[part 3 of 15: package /Cluster]
AUTOSAR XML (schema 4-3-0)
package /Cluster  (continued)
  can cluster HCP3_CANFD01: baudrate=500000, protocol-name=CAN, protocol-version=2.0, bus-off-recovery={bor-counter-l-1-to-l-2=1, bor-time-l-1=0.05, bor-time-l-2=0.2}, can-fd-baudrate=1000000  (continued)
    can physical channel CHNL: comm-connectors=CN_HCP3_CANFD01  (continued)
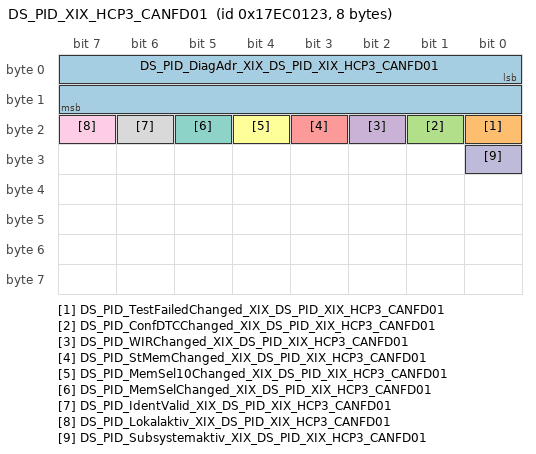
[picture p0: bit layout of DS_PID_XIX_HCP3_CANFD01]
      frame DS_PID_XIX_HCP3_CANFD01: id 0x17EC0123, to HCP3_IONode, frame-length=8, can-addressing-mode=EXTENDED, can-frame-rx-behavior=CAN-FD, can-frame-tx-behavior=CAN-FD
        pdu DS_PID_XIX_HCP3_CANFD01: length=8, minimum-delay=0.08, transmission-mode-true-timing={cyclic-timing={time-offset=0.0, time-period=1.0}, event-controlled-timing={number-of-repetitions=0, repetition-period=0.0}}, unused-bit-pattern=0
          signal DS_PID_DiagAdr_XIX_DS_PID_XIX_HCP3_CANFD01: start 0, 16 bit, little-endian, data-type-policy=OVERRIDE, i-signal-type=PRIMITIVE, init-value=33095, base-type=BT_DS_PID_DiagAdr, compu {phys=raw for raw 0..65535}, range phys 0..65535, raw 0..65535, transfer-property=PENDING  # Übertragung vom Diagnosestatus gem. 80114
          signal DS_PID_TestFailedChanged_XIX_DS_PID_XIX_HCP3_CANFD01: start 16, 1 bit, little-endian, data-type-policy=OVERRIDE, i-signal-type=PRIMITIVE, init-value=0, base-type=BT_DS_PID_TestFailedChanged, compu {phys=raw for raw 0..1}, range phys 0..1, raw 0..1, transfer-property=TRIGGERED-ON-CHANGE-WITHOUT-REPETITION  # Übertragung vom Diagnosestatus gem. 80114
          signal DS_PID_ConfDTCChanged_XIX_DS_PID_XIX_HCP3_CANFD01: start 17, 1 bit, little-endian, data-type-policy=OVERRIDE, i-signal-type=PRIMITIVE, init-value=0, base-type=BT_DS_PID_ConfDTCChanged, compu {phys=raw for raw 0..1}, range phys 0..1, raw 0..1, transfer-property=TRIGGERED-ON-CHANGE-WITHOUT-REPETITION  # Übertragung vom Diagnosestatus gem. 80114
          signal DS_PID_WIRChanged_XIX_DS_PID_XIX_HCP3_CANFD01: start 18, 1 bit, little-endian, data-type-policy=OVERRIDE, i-signal-type=PRIMITIVE, init-value=0, base-type=BT_DS_PID_WIRChanged, compu {phys=raw for raw 0..1}, range phys 0..1, raw 0..1, transfer-property=TRIGGERED-ON-CHANGE-WITHOUT-REPETITION  # Übertragung vom Diagnosestatus gem. 80114
          signal DS_PID_StMemChanged_XIX_DS_PID_XIX_HCP3_CANFD01: start 19, 1 bit, little-endian, data-type-policy=OVERRIDE, i-signal-type=PRIMITIVE, init-value=0, base-type=BT_DS_PID_StMemChanged, compu {phys=raw for raw 0..1}, range phys 0..1, raw 0..1, transfer-property=TRIGGERED-ON-CHANGE-WITHOUT-REPETITION  # Übertragung vom Diagnosestatus gem. 80114
          signal DS_PID_MemSel10Changed_XIX_DS_PID_XIX_HCP3_CANFD01: start 20, 1 bit, little-endian, data-type-policy=OVERRIDE, i-signal-type=PRIMITIVE, init-value=0, base-type=BT_DS_PID_MemSel10Changed, compu {phys=raw for raw 0..1}, range phys 0..1, raw 0..1, transfer-property=TRIGGERED-ON-CHANGE-WITHOUT-REPETITION  # Übertragung vom Diagnosestatus gem. 80114
          signal DS_PID_MemSelChanged_XIX_DS_PID_XIX_HCP3_CANFD01: start 21, 1 bit, little-endian, data-type-policy=OVERRIDE, i-signal-type=PRIMITIVE, init-value=0, base-type=BT_DS_PID_MemSelChanged, compu {phys=raw for raw 0..1}, range phys 0..1, raw 0..1, transfer-property=TRIGGERED-ON-CHANGE-WITHOUT-REPETITION  # Übertragung vom Diagnosestatus gem. 80114
          signal DS_PID_IdentValid_XIX_DS_PID_XIX_HCP3_CANFD01: start 22, 1 bit, little-endian, data-type-policy=OVERRIDE, i-signal-type=PRIMITIVE, init-value=1, base-type=BT_DS_PID_IdentValid, compu {1=Cx1_Gueltig (CM_DS_PID_IdentValid_Cx1_Gueltig), 0=Cx0_Ungueltig (CM_DS_PID_IdentValid_Cx0_Ungueltig)}, range raw 0..1, transfer-property=TRIGGERED-ON-CHANGE-WITHOUT-REPETITION  # Signalisiert ob die Identifikationsdaten gueltig sind
          signal DS_PID_Lokalaktiv_XIX_DS_PID_XIX_HCP3_CANFD01: start 23, 1 bit, little-endian, data-type-policy=OVERRIDE, i-signal-type=PRIMITIVE, init-value=0, base-type=BT_DS_PID_Lokalaktiv, compu {0=Cx0_war_nicht_lokal_aktiv (CM_DS_PID_Lokalaktiv_Cx0_war_nicht_lokal_aktiv), 1=Cx1_war_lokal_aktiv (CM_DS_PID_Lokalaktiv_Cx1_war_lokal_aktiv)}, range raw 0..1, transfer-property=PENDING  # Zeigt an ob das SG nach Klemme15 AUS und nach entsprechender MAX Aktivzeit noch aktiv war.
          signal DS_PID_Subsystemaktiv_XIX_DS_PID_XIX_HCP3_CANFD01: start 24, 1 bit, little-endian, data-type-policy=OVERRIDE, i-signal-type=PRIMITIVE, init-value=0, base-type=BT_DS_PID_Subsystemaktiv, compu {0=Cx0_war_nicht_lokal_aktiv (CM_DS_PID_Subsystemaktiv_Cx0_war_nicht_lokal_aktiv), 1=Cx1_war_lokal_aktiv (CM_DS_PID_Subsystemaktiv_Cx1_war_lokal_aktiv)}, range raw 0..1, transfer-property=PENDING  # Zeigt an ob ein Subsystem des SGs nach Klemme15 AUS und nach entsprechender MAX Aktivzeit noch aktiv war
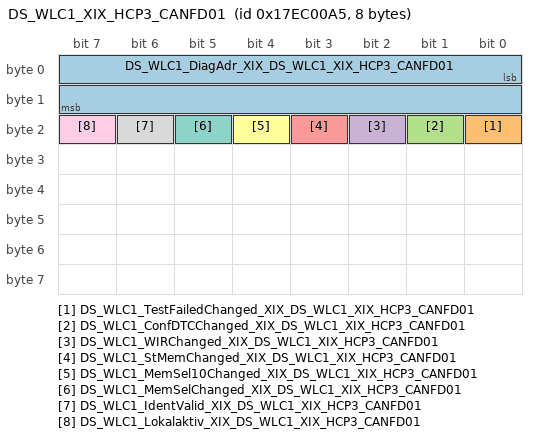
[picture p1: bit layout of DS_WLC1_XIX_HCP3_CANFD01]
      frame DS_WLC1_XIX_HCP3_CANFD01: id 0x17EC00A5, to HCP3_IONode, frame-length=8, can-addressing-mode=EXTENDED, can-frame-rx-behavior=CAN-FD, can-frame-tx-behavior=CAN-FD
        pdu DS_WLC1_XIX_HCP3_CANFD01: length=8, minimum-delay=0.08, transmission-mode-true-timing={cyclic-timing={time-offset=0.0, time-period=1.0}, event-controlled-timing={number-of-repetitions=0, repetition-period=0.0}}, unused-bit-pattern=0
          signal DS_WLC1_DiagAdr_XIX_DS_WLC1_XIX_HCP3_CANFD01: start 0, 16 bit, little-endian, data-type-policy=OVERRIDE, i-signal-type=PRIMITIVE, init-value=222, base-type=BT_DS_WLC1_DiagAdr, compu {phys=raw for raw 0..65535}, range phys 0..65535, raw 0..65535, transfer-property=PENDING  # Übertragung vom Diagnosestatus gem. 80114
          signal DS_WLC1_TestFailedChanged_XIX_DS_WLC1_XIX_HCP3_CANFD01: start 16, 1 bit, little-endian, data-type-policy=OVERRIDE, i-signal-type=PRIMITIVE, init-value=0, base-type=BT_DS_WLC1_TestFailedChanged, compu {phys=raw for raw 0..1}, range phys 0..1, raw 0..1, transfer-property=TRIGGERED-ON-CHANGE-WITHOUT-REPETITION  # Übertragung vom Diagnosestatus gem. 80114
          signal DS_WLC1_ConfDTCChanged_XIX_DS_WLC1_XIX_HCP3_CANFD01: start 17, 1 bit, little-endian, data-type-policy=OVERRIDE, i-signal-type=PRIMITIVE, init-value=0, base-type=BT_DS_WLC1_ConfDTCChanged, compu {phys=raw for raw 0..1}, range phys 0..1, raw 0..1, transfer-property=TRIGGERED-ON-CHANGE-WITHOUT-REPETITION  # Übertragung vom Diagnosestatus gem. 80114
          signal DS_WLC1_WIRChanged_XIX_DS_WLC1_XIX_HCP3_CANFD01: start 18, 1 bit, little-endian, data-type-policy=OVERRIDE, i-signal-type=PRIMITIVE, init-value=0, base-type=BT_DS_WLC1_WIRChanged, compu {phys=raw for raw 0..1}, range phys 0..1, raw 0..1, transfer-property=TRIGGERED-ON-CHANGE-WITHOUT-REPETITION  # Übertragung vom Diagnosestatus gem. 80114
          signal DS_WLC1_StMemChanged_XIX_DS_WLC1_XIX_HCP3_CANFD01: start 19, 1 bit, little-endian, data-type-policy=OVERRIDE, i-signal-type=PRIMITIVE, init-value=0, base-type=BT_DS_WLC1_StMemChanged, compu {phys=raw for raw 0..1}, range phys 0..1, raw 0..1, transfer-property=TRIGGERED-ON-CHANGE-WITHOUT-REPETITION  # Übertragung vom Diagnosestatus gem. 80114
          signal DS_WLC1_MemSel10Changed_XIX_DS_WLC1_XIX_HCP3_CANFD01: start 20, 1 bit, little-endian, data-type-policy=OVERRIDE, i-signal-type=PRIMITIVE, init-value=0, base-type=BT_DS_WLC1_MemSel10Changed, compu {phys=raw for raw 0..1}, range phys 0..1, raw 0..1, transfer-property=TRIGGERED-ON-CHANGE-WITHOUT-REPETITION  # Übertragung vom Diagnosestatus gem. 80114
          signal DS_WLC1_MemSelChanged_XIX_DS_WLC1_XIX_HCP3_CANFD01: start 21, 1 bit, little-endian, data-type-policy=OVERRIDE, i-signal-type=PRIMITIVE, init-value=0, base-type=BT_DS_WLC1_MemSelChanged, compu {phys=raw for raw 0..1}, range phys 0..1, raw 0..1, transfer-property=TRIGGERED-ON-CHANGE-WITHOUT-REPETITION  # Übertragung vom Diagnosestatus gem. 80114
          signal DS_WLC1_IdentValid_XIX_DS_WLC1_XIX_HCP3_CANFD01: start 22, 1 bit, little-endian, data-type-policy=OVERRIDE, i-signal-type=PRIMITIVE, init-value=1, base-type=BT_DS_WLC1_IdentValid, compu {1=Cx1_Gueltig (CM_DS_WLC1_IdentValid_Cx1_Gueltig), 0=Cx0_Ungueltig (CM_DS_WLC1_IdentValid_Cx0_Ungueltig)}, range raw 0..1, transfer-property=TRIGGERED-ON-CHANGE-WITHOUT-REPETITION  # Signalisiert ob die Identifikationsdaten gueltig sind
          signal DS_WLC1_Lokalaktiv_XIX_DS_WLC1_XIX_HCP3_CANFD01: start 23, 1 bit, little-endian, data-type-policy=OVERRIDE, i-signal-type=PRIMITIVE, init-value=0, base-type=BT_DS_WLC1_Lokalaktiv, compu {0=Cx0_war_nicht_lokal_aktiv (CM_DS_WLC1_Lokalaktiv_Cx0_war_nicht_lokal_aktiv), 1=Cx1_war_lokal_aktiv (CM_DS_WLC1_Lokalaktiv_Cx1_war_lokal_aktiv)}, range raw 0..1, transfer-property=PENDING  # Zeigt an ob das SG nach Klemme15 AUS und nach entsprechender MAX Aktivzeit noch aktiv war.
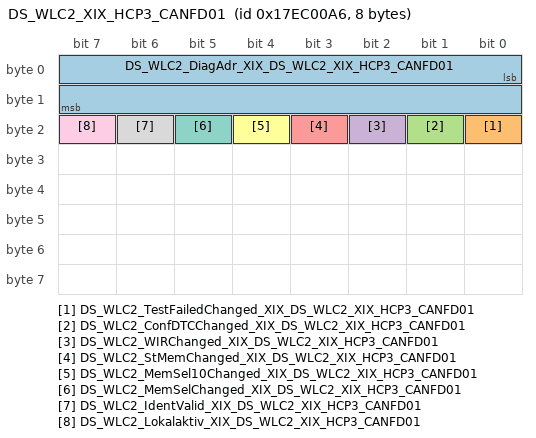
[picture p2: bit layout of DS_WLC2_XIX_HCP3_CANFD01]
      frame DS_WLC2_XIX_HCP3_CANFD01: id 0x17EC00A6, to HCP3_IONode, frame-length=8, can-addressing-mode=EXTENDED, can-frame-rx-behavior=CAN-FD, can-frame-tx-behavior=CAN-FD
        pdu DS_WLC2_XIX_HCP3_CANFD01: length=8, minimum-delay=0.08, transmission-mode-true-timing={cyclic-timing={time-offset=0.0, time-period=1.0}, event-controlled-timing={number-of-repetitions=0, repetition-period=0.0}}, unused-bit-pattern=0
          signal DS_WLC2_DiagAdr_XIX_DS_WLC2_XIX_HCP3_CANFD01: start 0, 16 bit, little-endian, data-type-policy=OVERRIDE, i-signal-type=PRIMITIVE, init-value=223, base-type=BT_DS_WLC2_DiagAdr, compu {phys=raw for raw 0..65535}, range phys 0..65535, raw 0..65535, transfer-property=PENDING  # Übertragung vom Diagnosestatus gem. 80114
          signal DS_WLC2_TestFailedChanged_XIX_DS_WLC2_XIX_HCP3_CANFD01: start 16, 1 bit, little-endian, data-type-policy=OVERRIDE, i-signal-type=PRIMITIVE, init-value=0, base-type=BT_DS_WLC2_TestFailedChanged, compu {phys=raw for raw 0..1}, range phys 0..1, raw 0..1, transfer-property=TRIGGERED-ON-CHANGE-WITHOUT-REPETITION  # Übertragung vom Diagnosestatus gem. 80114
          signal DS_WLC2_ConfDTCChanged_XIX_DS_WLC2_XIX_HCP3_CANFD01: start 17, 1 bit, little-endian, data-type-policy=OVERRIDE, i-signal-type=PRIMITIVE, init-value=0, base-type=BT_DS_WLC2_ConfDTCChanged, compu {phys=raw for raw 0..1}, range phys 0..1, raw 0..1, transfer-property=TRIGGERED-ON-CHANGE-WITHOUT-REPETITION  # Übertragung vom Diagnosestatus gem. 80114
          signal DS_WLC2_WIRChanged_XIX_DS_WLC2_XIX_HCP3_CANFD01: start 18, 1 bit, little-endian, data-type-policy=OVERRIDE, i-signal-type=PRIMITIVE, init-value=0, base-type=BT_DS_WLC2_WIRChanged, compu {phys=raw for raw 0..1}, range phys 0..1, raw 0..1, transfer-property=TRIGGERED-ON-CHANGE-WITHOUT-REPETITION  # Übertragung vom Diagnosestatus gem. 80114
          signal DS_WLC2_StMemChanged_XIX_DS_WLC2_XIX_HCP3_CANFD01: start 19, 1 bit, little-endian, data-type-policy=OVERRIDE, i-signal-type=PRIMITIVE, init-value=0, base-type=BT_DS_WLC2_StMemChanged, compu {phys=raw for raw 0..1}, range phys 0..1, raw 0..1, transfer-property=TRIGGERED-ON-CHANGE-WITHOUT-REPETITION  # Übertragung vom Diagnosestatus gem. 80114
          signal DS_WLC2_MemSel10Changed_XIX_DS_WLC2_XIX_HCP3_CANFD01: start 20, 1 bit, little-endian, data-type-policy=OVERRIDE, i-signal-type=PRIMITIVE, init-value=0, base-type=BT_DS_WLC2_MemSel10Changed, compu {phys=raw for raw 0..1}, range phys 0..1, raw 0..1, transfer-property=TRIGGERED-ON-CHANGE-WITHOUT-REPETITION  # Übertragung vom Diagnosestatus gem. 80114
          signal DS_WLC2_MemSelChanged_XIX_DS_WLC2_XIX_HCP3_CANFD01: start 21, 1 bit, little-endian, data-type-policy=OVERRIDE, i-signal-type=PRIMITIVE, init-value=0, base-type=BT_DS_WLC2_MemSelChanged, compu {phys=raw for raw 0..1}, range phys 0..1, raw 0..1, transfer-property=TRIGGERED-ON-CHANGE-WITHOUT-REPETITION  # Übertragung vom Diagnosestatus gem. 80114
          signal DS_WLC2_IdentValid_XIX_DS_WLC2_XIX_HCP3_CANFD01: start 22, 1 bit, little-endian, data-type-policy=OVERRIDE, i-signal-type=PRIMITIVE, init-value=1, base-type=BT_DS_WLC2_IdentValid, compu {1=Cx1_Gueltig (CM_DS_WLC2_IdentValid_Cx1_Gueltig), 0=Cx0_Ungueltig (CM_DS_WLC2_IdentValid_Cx0_Ungueltig)}, range raw 0..1, transfer-property=TRIGGERED-ON-CHANGE-WITHOUT-REPETITION  # Signalisiert ob die Identifikationsdaten gueltig sind
          signal DS_WLC2_Lokalaktiv_XIX_DS_WLC2_XIX_HCP3_CANFD01: start 23, 1 bit, little-endian, data-type-policy=OVERRIDE, i-signal-type=PRIMITIVE, init-value=0, base-type=BT_DS_WLC2_Lokalaktiv, compu {1=Cx1_war_lokal_aktiv (CM_DS_WLC2_Lokalaktiv_Cx1_war_lokal_aktiv), 0=Cx0_war_nicht_lokal_aktiv (CM_DS_WLC2_Lokalaktiv_Cx0_war_nicht_lokal_aktiv)}, range raw 0..1, transfer-property=PENDING  # Zeigt an ob das SG nach Klemme15 AUS und nach entsprechender MAX Aktivzeit noch aktiv war.
      frame Diag_LSR_1_Req_FD_XIX_HCP3_CANFD01: id 0x1C400693, from HCP3_IONode, frame-length=64, can-addressing-mode=EXTENDED, can-frame-rx-behavior=CAN-FD, can-frame-tx-behavior=CAN-FD
        n pdu Diag_LSR_1_Req_FD_XIX_HCP3_CANFD01: length=64
      frame Diag_LSR_1_Resp_FD_XIX_HCP3_CANFD01: id 0x1C420693, to HCP3_IONode, frame-length=64, can-addressing-mode=EXTENDED, can-frame-rx-behavior=CAN-FD, can-frame-tx-behavior=CAN-FD
        n pdu Diag_LSR_1_Resp_FD_XIX_HCP3_CANFD01: length=64
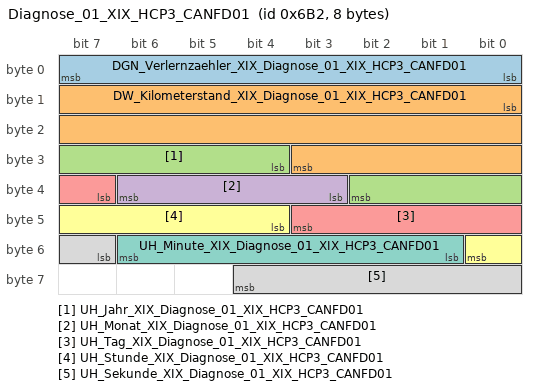
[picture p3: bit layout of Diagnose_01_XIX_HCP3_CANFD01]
      frame Diagnose_01_XIX_HCP3_CANFD01: id 0x6B2, from HCP3_IONode, frame-length=8, can-addressing-mode=STANDARD, can-frame-rx-behavior=CAN-FD, can-frame-tx-behavior=CAN-FD
        pdu Diagnose_01_XIX_HCP3_CANFD01: length=8, transmission-mode-true-timing=cyclic-timing={time-offset=0.0, time-period=1.0}, unused-bit-pattern=0
          signal DGN_Verlernzaehler_XIX_Diagnose_01_XIX_HCP3_CANFD01: start 0, 8 bit, little-endian, data-type-policy=OVERRIDE, i-signal-type=PRIMITIVE, init-value=0, base-type=BT_DGN_Verlernzaehler, compu {phys=raw for raw 0..254, 255=Cxff_ungueltiger_Zaehlerstand_oder_kein_gueltiger_Fahrzyklus (CM_DGN_Verlernzaehler_Cxff_ungueltiger_Zaehlerstand_oder_kein_gueltiger_Fahrzyklus) (ungültiger Zählerstand oder kein gültiger Fahrzyklus)}, range phys 0..254, raw 0..255, transfer-property=PENDING  # wrap around 254 --> 0
          signal DW_Kilometerstand_XIX_Diagnose_01_XIX_HCP3_CANFD01: start 8, 20 bit, little-endian, data-type-policy=OVERRIDE, i-signal-type=PRIMITIVE, init-value=1048574, base-type=BT_DW_Kilometerstand, invalid-value=Invalid_DW_Kilometerstand_XIX_Diagnose_01_XIX_HCP3_CANFD01:1048575, compu {phys=raw for raw 0..1048573, 1048575=Cxfffff_Fehler (CM_DW_Kilometerstand_Cxfffff_Fehler), 1048574=Cxffffe_Init (CM_DW_Kilometerstand_Cxffffe_Init); unit Unit_KiloMeter}, range phys 0..1048573 Unit_KiloMeter, raw 0..1048575, unit=Unit_KiloMeter, transfer-property=PENDING  # Fehler wird ausgegeben, falls Kilometerstand nicht restaurierbar
          signal UH_Jahr_XIX_Diagnose_01_XIX_HCP3_CANFD01: start 28, 7 bit, little-endian, data-type-policy=OVERRIDE, i-signal-type=PRIMITIVE, init-value=0, base-type=BT_UH_Jahr, compu {phys=raw+2000 for raw 0..127; unit Unit_Year}, range phys 2000..2127 Unit_Year, raw 0..127, unit=Unit_Year, transfer-property=PENDING
          signal UH_Monat_XIX_Diagnose_01_XIX_HCP3_CANFD01: start 35, 4 bit, little-endian, data-type-policy=OVERRIDE, i-signal-type=PRIMITIVE, init-value=0, base-type=BT_UH_Monat, invalid-value=Invalid_UH_Monat_XIX_Diagnose_01_XIX_HCP3_CANFD01:15, compu {phys=raw for raw 1..12, 15=Cxf_Fehler (CM_UH_Monat_Cxf_Fehler), 14=Cxe_Relatives_Datum (CM_UH_Monat_Cxe_Relatives_Datum), 0=Cx0_Init (CM_UH_Monat_Cx0_Init); unit Unit_Month}, range phys 1..12 Unit_Month, raw 0..15, unit=Unit_Month, transfer-property=PENDING  # 0x0D, 0xF = Werte ungültig 0x0E = Relatives Datum (nur VW)
          signal UH_Tag_XIX_Diagnose_01_XIX_HCP3_CANFD01: start 39, 5 bit, little-endian, data-type-policy=OVERRIDE, i-signal-type=PRIMITIVE, init-value=0, base-type=BT_UH_Tag, compu {phys=raw for raw 1..31, 0=Cx0_Init (CM_UH_Tag_Cx0_Init); unit Unit_Day}, range phys 1..31 Unit_Day, raw 0..31, unit=Unit_Day, transfer-property=PENDING  # 0x0: reserviert bei VW
          signal UH_Stunde_XIX_Diagnose_01_XIX_HCP3_CANFD01: start 44, 5 bit, little-endian, data-type-policy=OVERRIDE, i-signal-type=PRIMITIVE, init-value=0, base-type=BT_UH_Stunde, compu {phys=raw for raw 0..23; unit Unit_Hours}, range phys 0..23 Unit_Hours, raw 0..23, unit=Unit_Hours, transfer-property=PENDING  # 0x18 - 0x1F = Werte ungültig
          signal UH_Minute_XIX_Diagnose_01_XIX_HCP3_CANFD01: start 49, 6 bit, little-endian, data-type-policy=OVERRIDE, i-signal-type=PRIMITIVE, init-value=0, base-type=BT_UH_Minute, compu {phys=raw for raw 0..59; unit Unit_Minut}, range phys 0..59 Unit_Minut, raw 0..59, unit=Unit_Minut, transfer-property=PENDING  # 0x3C- 0x3f = Werte ungültig
          signal UH_Sekunde_XIX_Diagnose_01_XIX_HCP3_CANFD01: start 55, 6 bit, little-endian, data-type-policy=OVERRIDE, i-signal-type=PRIMITIVE, init-value=0, base-type=BT_UH_Sekunde, compu {phys=raw for raw 0..59; unit Unit_Secon}, range phys 0..59 Unit_Secon, raw 0..59, unit=Unit_Secon, transfer-property=PENDING  # 0x3C- 0x3f = Werte ungültig
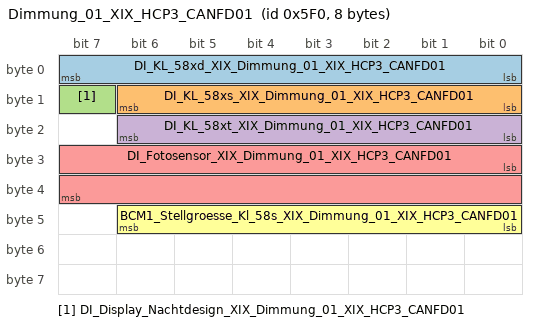
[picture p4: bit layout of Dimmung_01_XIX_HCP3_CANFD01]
      frame Dimmung_01_XIX_HCP3_CANFD01: id 0x5F0, from HCP3_IONode, frame-length=8, can-addressing-mode=STANDARD, can-frame-rx-behavior=CAN-FD, can-frame-tx-behavior=CAN-FD
        pdu Dimmung_01_XIX_HCP3_CANFD01: length=8, minimum-delay=0.05, transmission-mode-true-timing={cyclic-timing={time-offset=0.0, time-period=0.2}, event-controlled-timing={number-of-repetitions=0, repetition-period=0.0}}, unused-bit-pattern=0  # ab MQB nach abgestimmten FLH Dimmung
          signal DI_KL_58xd_XIX_Dimmung_01_XIX_HCP3_CANFD01: start 0, 8 bit, little-endian, data-type-policy=OVERRIDE, i-signal-type=PRIMITIVE, init-value=254, base-type=BT_DI_KL_58xd, invalid-value=Invalid_DI_KL_58xd_XIX_Dimmung_01_XIX_HCP3_CANFD01:255, compu {phys=raw for raw 0..253, 255=Cxff_Fehler (CM_DI_KL_58xd_Cxff_Fehler), 254=Cxfe_Init (CM_DI_KL_58xd_Cxfe_Init)}, range phys 0..253, raw 0..255, transfer-property=TRIGGERED-ON-CHANGE-WITHOUT-REPETITION  # Klemme 58xd Display- und Funktionsbeleuchtung Mit der Klemme 58xd wird die Helligkeit der Display- und der Funktionsbeleuchtungen der Schalter gesteuert. Im Detail beschrieben im 'Funktionslastenheft Dimmung MQB'.
          signal DI_KL_58xs_XIX_Dimmung_01_XIX_HCP3_CANFD01: start 8, 7 bit, little-endian, data-type-policy=OVERRIDE, i-signal-type=PRIMITIVE, init-value=126, base-type=BT_DI_KL_58xs, invalid-value=Invalid_DI_KL_58xs_XIX_Dimmung_01_XIX_HCP3_CANFD01:127, compu {phys=raw for raw 0..100, 127=Cx7f_Fehler (CM_DI_KL_58xs_Cx7f_Fehler), 126=Cx7e_Init (CM_DI_KL_58xs_Cx7e_Init); unit Unit_PerCent}, range phys 0..100 Unit_PerCent, raw 0..127, unit=Unit_PerCent, transfer-property=TRIGGERED-ON-CHANGE-WITHOUT-REPETITION  # Suchbeleuchtung Schalter EIN-AUS-Schaltalgorithmus der allgemeinen Schaltersuchbeleuchtung. Im Detail beschrieben im 'Funktionslastenheft Dimmung MQB'.
          signal DI_Display_Nachtdesign_XIX_Dimmung_01_XIX_HCP3_CANFD01: start 15, 1 bit, little-endian, data-type-policy=OVERRIDE, i-signal-type=PRIMITIVE, init-value=0, base-type=BT_DI_Display_Nachtdesign, transfer-property=TRIGGERED-ON-CHANGE-WITHOUT-REPETITION  # Für Displays sind oft automatische Umschaltungen von Tag-/Nachtdesign vorgesehen. Es gibt jedoch Zustände, an denen auch tagsüber das Abblendlicht eingeschaltet ist. z.B. Dauerfahrlicht, Geschwindigkeitsabhängiges "Licht-An-Bei-Autobahn", "Regenlicht", etc. Die Aufgabe des Signals s_Display_Nachtdesign ist es, Fehlumschaltungen zu vermeiden. Es ist im Dimm-Master zu implementieren. Im Detail beschrieben im 'Funktionslastenheft Dimmung MQB'.
          signal DI_KL_58xt_XIX_Dimmung_01_XIX_HCP3_CANFD01: start 16, 7 bit, little-endian, data-type-policy=OVERRIDE, i-signal-type=PRIMITIVE, init-value=126, base-type=BT_DI_KL_58xt, invalid-value=Invalid_DI_KL_58xt_XIX_Dimmung_01_XIX_HCP3_CANFD01:127, compu {phys=raw for raw 0..100, 127=Cx7f_Fehler (CM_DI_KL_58xt_Cx7f_Fehler), 126=Cx7e_Init (CM_DI_KL_58xt_Cx7e_Init); unit Unit_PerCent}, range phys 0..100 Unit_PerCent, raw 0..127, unit=Unit_PerCent, transfer-property=TRIGGERED-ON-CHANGE-WITHOUT-REPETITION  # Timergesteuerte Suchbeleuchtung Der EIN-AUS-Schaltalgorithmus für die vor- und nachlaufende Schaltersuchbeleuchtungen beim Ein- & Aussteigen; z.B.: Start/Stop-Taster. Im Detail beschrieben im 'Funktionslastenheft Dimmung MQB'.
          signal DI_Fotosensor_XIX_Dimmung_01_XIX_HCP3_CANFD01: start 24, 16 bit, little-endian, data-type-policy=OVERRIDE, i-signal-type=PRIMITIVE, init-value=0, base-type=BT_DI_Fotosensor, compu {phys=raw for raw 0..65535}, range phys 0..65535, raw 0..65535, transfer-property=TRIGGERED-ON-CHANGE-WITHOUT-REPETITION  # Helligkeitswert Fotosensor Für die Dimmung relevanter Wert zur Sensierung der Umgebungshelligkeit Im Detail beschrieben im 'Funktionslastenheft Dimmung MQB'.
          signal BCM1_Stellgroesse_Kl_58s_XIX_Dimmung_01_XIX_HCP3_CANFD01: start 40, 7 bit, little-endian, data-type-policy=OVERRIDE, i-signal-type=PRIMITIVE, init-value=126, base-type=BT_BCM1_Stellgroesse_Kl_58s, invalid-value=Invalid_BCM1_Stellgroesse_Kl_58s_XIX_Dimmung_01_XIX_HCP3_CANFD01:127, compu {phys=raw for raw 0..100, 127=Cx7f_Fehler (CM_BCM1_Stellgroesse_Kl_58s_Cx7f_Fehler), 125=Cx7d_Nicht_verbaut (CM_BCM1_Stellgroesse_Kl_58s_Cx7d_Nicht_verbaut), 126=Cx7e_Init (CM_BCM1_Stellgroesse_Kl_58s_Cx7e_Init)}, range phys 0..100, raw 0..127, transfer-property=TRIGGERED-ON-CHANGE-WITHOUT-REPETITION  # Rohwert Dimmpoti
      frame DispCtrlCID_CID_Req_FD_XIX_HCP3_CANFD01: id 0x1C446822, from HCP3_IONode, frame-length=64, can-addressing-mode=EXTENDED, can-frame-rx-behavior=CAN-FD, can-frame-tx-behavior=CAN-FD
        n pdu DispCtrlCID_CID_Req_FD_XIX_HCP3_CANFD01: length=64
      frame DispCtrlCID_CID_Resp_FD_XIX_HCP3_CANFD01: id 0x1C466822, to HCP3_IONode, frame-length=64, can-addressing-mode=EXTENDED, can-frame-rx-behavior=CAN-FD, can-frame-tx-behavior=CAN-FD
        n pdu DispCtrlCID_CID_Resp_FD_XIX_HCP3_CANFD01: length=64
      frame DispCtrlPID_PID_Req_FD_XIX_HCP3_CANFD01: id 0x1C446723, from HCP3_IONode, frame-length=64, can-addressing-mode=EXTENDED, can-frame-rx-behavior=CAN-FD, can-frame-tx-behavior=CAN-FD
        n pdu DispCtrlPID_PID_Req_FD_XIX_HCP3_CANFD01: length=64
      frame DispCtrlPID_PID_Resp_FD_XIX_HCP3_CANFD01: id 0x1C466723, to HCP3_IONode, frame-length=64, can-addressing-mode=EXTENDED, can-frame-rx-behavior=CAN-FD, can-frame-tx-behavior=CAN-FD
        n pdu DispCtrlPID_PID_Resp_FD_XIX_HCP3_CANFD01: length=64
      frame DispInpCID_CID_Req_FD_XIX_HCP3_CANFD01: id 0x1C446B22, from HCP3_IONode, frame-length=64, can-addressing-mode=EXTENDED, can-frame-rx-behavior=CAN-FD, can-frame-tx-behavior=CAN-FD
        n pdu DispInpCID_CID_Req_FD_XIX_HCP3_CANFD01: length=64
      frame DispInpCID_CID_Resp_FD_XIX_HCP3_CANFD01: id 0x1C466B22, to HCP3_IONode, frame-length=64, can-addressing-mode=EXTENDED, can-frame-rx-behavior=CAN-FD, can-frame-tx-behavior=CAN-FD
        n pdu DispInpCID_CID_Resp_FD_XIX_HCP3_CANFD01: length=64
      frame DispInpPID_PID_Req_FD_XIX_HCP3_CANFD01: id 0x1C446A23, from HCP3_IONode, frame-length=64, can-addressing-mode=EXTENDED, can-frame-rx-behavior=CAN-FD, can-frame-tx-behavior=CAN-FD
        n pdu DispInpPID_PID_Req_FD_XIX_HCP3_CANFD01: length=64
      frame DispInpPID_PID_Resp_FD_XIX_HCP3_CANFD01: id 0x1C466A23, to HCP3_IONode, frame-length=64, can-addressing-mode=EXTENDED, can-frame-rx-behavior=CAN-FD, can-frame-tx-behavior=CAN-FD
        n pdu DispInpPID_PID_Resp_FD_XIX_HCP3_CANFD01: length=64
      frame FBS_MKGO_01_XIX_HCP3_CANFD01: id 0x16A95538, from HCP3_IONode, frame-length=64, can-addressing-mode=EXTENDED, can-frame-rx-behavior=CAN-FD, can-frame-tx-behavior=CAN-FD
        pdu FBS_MKGO_01_XIX_HCP3_CANFD01: length=64, transmission-mode-true-timing=event-controlled-timing={number-of-repetitions=0, repetition-period=0.0}, unused-bit-pattern=0
          signal FBS_MKGO_01_XIX_FBS_MKGO_01_XIX_HCP3_CANFD01: start 0, 512 bit, opaque, data-type-policy=OVERRIDE, i-signal-type=ARRAY, init-value=64 x 0, base-type=BT_FBS_MKGO_01, implementation-data-type=FBS_MKGO_01, transfer-property=TRIGGERED-WITHOUT-REPETITION  # NFC Kommunikation FBS zu MKGO
      frame FBS_MKGO_02_XIX_HCP3_CANFD01: id 0x16A95539, from HCP3_IONode, frame-length=64, can-addressing-mode=EXTENDED, can-frame-rx-behavior=CAN-FD, can-frame-tx-behavior=CAN-FD
        pdu FBS_MKGO_02_XIX_HCP3_CANFD01: length=64, transmission-mode-true-timing=event-controlled-timing={number-of-repetitions=0, repetition-period=0.0}, unused-bit-pattern=0
          signal FBS_MKGO_02_XIX_FBS_MKGO_02_XIX_HCP3_CANFD01: start 0, 512 bit, opaque, data-type-policy=OVERRIDE, i-signal-type=ARRAY, init-value=64 x 0, base-type=BT_FBS_MKGO_02, implementation-data-type=FBS_MKGO_02, transfer-property=TRIGGERED-WITHOUT-REPETITION  # NFC Kommunikation FBS zu MKGO
      frame FBS_MKGO_03_XIX_HCP3_CANFD01: id 0x16A9553A, from HCP3_IONode, frame-length=64, can-addressing-mode=EXTENDED, can-frame-rx-behavior=CAN-FD, can-frame-tx-behavior=CAN-FD
        pdu FBS_MKGO_03_XIX_HCP3_CANFD01: length=64, transmission-mode-true-timing=event-controlled-timing={number-of-repetitions=0, repetition-period=0.0}, unused-bit-pattern=0
          signal FBS_MKGO_03_XIX_FBS_MKGO_03_XIX_HCP3_CANFD01: start 0, 512 bit, opaque, data-type-policy=OVERRIDE, i-signal-type=ARRAY, init-value=64 x 0, base-type=BT_FBS_MKGO_03, implementation-data-type=FBS_MKGO_03, transfer-property=TRIGGERED-WITHOUT-REPETITION  # NFC Kommunikation FBS zu MKGO
      frame FBS_MKGO_04_XIX_HCP3_CANFD01: id 0x16A9553B, from HCP3_IONode, frame-length=64, can-addressing-mode=EXTENDED, can-frame-rx-behavior=CAN-FD, can-frame-tx-behavior=CAN-FD
        pdu FBS_MKGO_04_XIX_HCP3_CANFD01: length=64, transmission-mode-true-timing=event-controlled-timing={number-of-repetitions=0, repetition-period=0.0}, unused-bit-pattern=0
          signal FBS_MKGO_04_XIX_FBS_MKGO_04_XIX_HCP3_CANFD01: start 0, 512 bit, opaque, data-type-policy=OVERRIDE, i-signal-type=ARRAY, init-value=64 x 0, base-type=BT_FBS_MKGO_04, implementation-data-type=FBS_MKGO_04, transfer-property=TRIGGERED-WITHOUT-REPETITION  # NFC Kommunikation FBS zu MKGO
      frame FBS_MKGO_05_XIX_HCP3_CANFD01: id 0x16A9553C, from HCP3_IONode, frame-length=64, can-addressing-mode=EXTENDED, can-frame-rx-behavior=CAN-FD, can-frame-tx-behavior=CAN-FD
        pdu FBS_MKGO_05_XIX_HCP3_CANFD01: length=64, transmission-mode-true-timing=event-controlled-timing={number-of-repetitions=0, repetition-period=0.0}, unused-bit-pattern=0
          signal FBS_MKGO_05_XIX_FBS_MKGO_05_XIX_HCP3_CANFD01: start 0, 512 bit, opaque, data-type-policy=OVERRIDE, i-signal-type=ARRAY, init-value=64 x 0, base-type=BT_FBS_MKGO_05, implementation-data-type=FBS_MKGO_05, transfer-property=TRIGGERED-WITHOUT-REPETITION  # NFC Kommunikation FBS zu MKGO
      frame HID_HUD_ZR_Req_FD_XIX_HCP3_CANFD01: id 0x1D001B73, to HCP3_IONode, frame-length=64, can-addressing-mode=EXTENDED, can-frame-rx-behavior=CAN-FD, can-frame-tx-behavior=CAN-FD
        n pdu HID_HUD_ZR_Req_FD_XIX_HCP3_CANFD01: length=64
      frame HID_HUD_ZR_Resp_FD_XIX_HCP3_CANFD01: id 0x1D021B73, from HCP3_IONode, frame-length=64, can-addressing-mode=EXTENDED, can-frame-rx-behavior=CAN-FD, can-frame-tx-behavior=CAN-FD
        n pdu HID_HUD_ZR_Resp_FD_XIX_HCP3_CANFD01: length=64
      frame HID_ZR_HUD_Req_FD_XIX_HCP3_CANFD01: id 0x1D00731B, from HCP3_IONode, frame-length=64, can-addressing-mode=EXTENDED, can-frame-rx-behavior=CAN-FD, can-frame-tx-behavior=CAN-FD
        n pdu HID_ZR_HUD_Req_FD_XIX_HCP3_CANFD01: length=64
      frame HID_ZR_HUD_Resp_FD_XIX_HCP3_CANFD01: id 0x1D02731B, to HCP3_IONode, frame-length=64, can-addressing-mode=EXTENDED, can-frame-rx-behavior=CAN-FD, can-frame-tx-behavior=CAN-FD
        n pdu HID_ZR_HUD_Resp_FD_XIX_HCP3_CANFD01: length=64
      frame HUD_ARC_Req_FD_XIX_HCP3_CANFD01: id 0x1CC01B3B, to HCP3_IONode, frame-length=64, can-addressing-mode=EXTENDED, can-frame-rx-behavior=CAN-FD, can-frame-tx-behavior=CAN-FD
        n pdu HUD_ARC_Req_FD_XIX_HCP3_CANFD01: length=64
      frame HUD_ARC_Resp_FD_XIX_HCP3_CANFD01: id 0x1CC21B3B, from HCP3_IONode, frame-length=64, can-addressing-mode=EXTENDED, can-frame-rx-behavior=CAN-FD, can-frame-tx-behavior=CAN-FD
        n pdu HUD_ARC_Resp_FD_XIX_HCP3_CANFD01: length=64
      frame ISOx_CCF_Req_FD_XIX_HCP3_CANFD01: id 0x1C440024, from HCP3_IONode, frame-length=64, can-addressing-mode=EXTENDED, can-frame-rx-behavior=CAN-FD, can-frame-tx-behavior=CAN-FD
        n pdu ISOx_CCF_Req_FD_XIX_HCP3_CANFD01: length=64
      frame ISOx_CCF_Resp_FD_XIX_HCP3_CANFD01: id 0x1C460024, to HCP3_IONode, frame-length=64, can-addressing-mode=EXTENDED, can-frame-rx-behavior=CAN-FD, can-frame-tx-behavior=CAN-FD
        n pdu ISOx_CCF_Resp_FD_XIX_HCP3_CANFD01: length=64
      frame ISOx_CID_Req_FD_XIX_HCP3_CANFD01: id 0x1C440022, from HCP3_IONode, frame-length=64, can-addressing-mode=EXTENDED, can-frame-rx-behavior=CAN-FD, can-frame-tx-behavior=CAN-FD
        n pdu ISOx_CID_Req_FD_XIX_HCP3_CANFD01: length=64
      frame ISOx_CID_Resp_FD_XIX_HCP3_CANFD01: id 0x1C460022, to HCP3_IONode, frame-length=64, can-addressing-mode=EXTENDED, can-frame-rx-behavior=CAN-FD, can-frame-tx-behavior=CAN-FD
        n pdu ISOx_CID_Resp_FD_XIX_HCP3_CANFD01: length=64
      frame ISOx_Funkt_Req_All_FD_XIX_HCP3_CANFD01: id 0x1C410000, from HCP3_IONode, frame-length=64, can-addressing-mode=EXTENDED, can-frame-rx-behavior=CAN-FD, can-frame-tx-behavior=CAN-FD
        n pdu ISOx_Funkt_Req_All_FD_XIX_HCP3_CANFD01: length=64
      frame ISOx_HUD_Req_FD_XIX_HCP3_CANFD01: id 0x1C40001B, from HCP3_IONode, frame-length=64, can-addressing-mode=EXTENDED, can-frame-rx-behavior=CAN-FD, can-frame-tx-behavior=CAN-FD
        n pdu ISOx_HUD_Req_FD_XIX_HCP3_CANFD01: length=64
      frame ISOx_HUD_Resp_FD_XIX_HCP3_CANFD01: id 0x1C42001B, to HCP3_IONode, frame-length=64, can-addressing-mode=EXTENDED, can-frame-rx-behavior=CAN-FD, can-frame-tx-behavior=CAN-FD
        n pdu ISOx_HUD_Resp_FD_XIX_HCP3_CANFD01: length=64
      frame ISOx_PID_Req_FD_XIX_HCP3_CANFD01: id 0x1C440023, from HCP3_IONode, frame-length=64, can-addressing-mode=EXTENDED, can-frame-rx-behavior=CAN-FD, can-frame-tx-behavior=CAN-FD
        n pdu ISOx_PID_Req_FD_XIX_HCP3_CANFD01: length=64
      frame ISOx_PID_Resp_FD_XIX_HCP3_CANFD01: id 0x1C460023, to HCP3_IONode, frame-length=64, can-addressing-mode=EXTENDED, can-frame-rx-behavior=CAN-FD, can-frame-tx-behavior=CAN-FD
        n pdu ISOx_PID_Resp_FD_XIX_HCP3_CANFD01: length=64
      frame ISOx_WLC1_Req_FD_XIX_HCP3_CANFD01: id 0x1C4000A5, from HCP3_IONode, frame-length=64, can-addressing-mode=EXTENDED, can-frame-rx-behavior=CAN-FD, can-frame-tx-behavior=CAN-FD
        n pdu ISOx_WLC1_Req_FD_XIX_HCP3_CANFD01: length=64
      frame ISOx_WLC1_Resp_FD_XIX_HCP3_CANFD01: id 0x1C4200A5, to HCP3_IONode, frame-length=64, can-addressing-mode=EXTENDED, can-frame-rx-behavior=CAN-FD, can-frame-tx-behavior=CAN-FD
        n pdu ISOx_WLC1_Resp_FD_XIX_HCP3_CANFD01: length=64
      frame ISOx_WLC2_Req_FD_XIX_HCP3_CANFD01: id 0x1C4000A6, from HCP3_IONode, frame-length=64, can-addressing-mode=EXTENDED, can-frame-rx-behavior=CAN-FD, can-frame-tx-behavior=CAN-FD
        n pdu ISOx_WLC2_Req_FD_XIX_HCP3_CANFD01: length=64
      frame ISOx_WLC2_Resp_FD_XIX_HCP3_CANFD01: id 0x1C4200A6, to HCP3_IONode, frame-length=64, can-addressing-mode=EXTENDED, can-frame-rx-behavior=CAN-FD, can-frame-tx-behavior=CAN-FD
        n pdu ISOx_WLC2_Resp_FD_XIX_HCP3_CANFD01: length=64
      frame Info_El_01_XIX_HCP3_CANFD01: id 0x1A555557, from HCP3_IONode, frame-length=16, can-addressing-mode=EXTENDED, can-frame-rx-behavior=CAN-FD, can-frame-tx-behavior=CAN-FD
        pdu Info_El_01_XIX_HCP3_CANFD01: length=16, minimum-delay=0.04, transmission-mode-true-timing={cyclic-timing={time-offset=0.0, time-period=1.0}, event-controlled-timing={number-of-repetitions=0, repetition-period=0.0}}, unused-bit-pattern=0
          signal ZR_State_CID_XIX_Info_El_01_XIX_HCP3_CANFD01: start 15, 3 bit, little-endian, data-type-policy=OVERRIDE, i-signal-type=PRIMITIVE, init-value=0, base-type=BT_ZR_State_CID, compu {2=Cx2_LowPow (CM_ZR_State_CID_Cx2_LowPow), 0=Cx0_Disp_Off (CM_ZR_State_CID_Cx0_Disp_Off), 1=Cx1_Disp_On (CM_ZR_State_CID_Cx1_Disp_On)}, range raw 0..2, transfer-property=TRIGGERED-ON-CHANGE-WITHOUT-REPETITION  # Kontrollbit für CI Hintergrundbeleuchtung aus, Hintergrundbeleuchtung an, Energiesparmodus
          signal ZR_State_PID_XIX_Info_El_01_XIX_HCP3_CANFD01: start 18, 3 bit, little-endian, data-type-policy=OVERRIDE, i-signal-type=PRIMITIVE, init-value=0, base-type=BT_ZR_State_PID, compu {0=Cx0_Disp_Off (CM_ZR_State_PID_Cx0_Disp_Off), 2=Cx2_LowPow (CM_ZR_State_PID_Cx2_LowPow), 1=Cx1_Disp_on (CM_ZR_State_PID_Cx1_Disp_on)}, range raw 0..2, transfer-property=TRIGGERED-ON-CHANGE-WITHOUT-REPETITION  # Kontrollbit für CID, Hintergrundbeleuchtung aus, Hintergrundbeleuchtung ein, Energiesparmodus
      frame KN_AMP_XIX_HCP3_CANFD01: id 0x17F0006F, to HCP3_IONode, frame-length=16, can-addressing-mode=EXTENDED, can-frame-rx-behavior=CAN-FD, can-frame-tx-behavior=CAN-FD
        pdu KN_AMP_XIX_HCP3_CANFD01: length=16, transmission-mode-true-timing=cyclic-timing={time-offset=0.0, time-period=0.5}, unused-bit-pattern=0
          signal AMP_KompSchutz_XIX_KN_AMP_XIX_HCP3_CANFD01: start 0, 1 bit, little-endian, data-type-policy=OVERRIDE, i-signal-type=PRIMITIVE, init-value=0, base-type=BT_AMP_KompSchutz, compu {0=Cx0_inaktiv (CM_AMP_KompSchutz_Cx0_inaktiv), 1=Cx1_aktiv (CM_AMP_KompSchutz_Cx1_aktiv)}, range raw 0..1, transfer-property=PENDING  # Funktionseinschränkung aufgrund Komponentenschutz aktiv
          signal AMP_Nachlauftyp_XIX_KN_AMP_XIX_HCP3_CANFD01: start 4, 4 bit, little-endian, data-type-policy=OVERRIDE, i-signal-type=PRIMITIVE, init-value=2, base-type=BT_AMP_Nachlauftyp, compu {1=Cx1_Komm_nach_KL15_AUS (CM_AMP_Nachlauftyp_Cx1_Komm_nach_KL15_AUS), 2=Cx2_Komm_bei_KL15_AUS (CM_AMP_Nachlauftyp_Cx2_Komm_bei_KL15_AUS), 4=Cx4_Buskopplung (CM_AMP_Nachlauftyp_Cx4_Buskopplung), 0=Cx0_Komm_bei_KL15_EIN (CM_AMP_Nachlauftyp_Cx0_Komm_bei_KL15_EIN)}, range raw 0..4, transfer-property=PENDING  # Abgebildet wird die von der Hardware vorgegebene Möglichkeit, die Kommunikation nach Klemme 15 = AUS aufrecht zu erhalten. Es wird ein Init-Wert gesendet.
          signal AMP_SNI_10_XIX_KN_AMP_XIX_HCP3_CANFD01: start 8, 10 bit, little-endian, data-type-policy=OVERRIDE, i-signal-type=PRIMITIVE, init-value=111, base-type=BT_AMP_SNI_10, compu {phys=raw for raw 0..1023}, range phys 0..1023, raw 0..1023, transfer-property=PENDING, to HCP3_IONode(timeout 5 s)  # Source Node-Identifier (SNI) identifiziert den Sender der NM-Botschaft (Knotenadresse) eindeutig im Fahrzeug
          signal KN_AMP_ECUKnockOut_XIX_KN_AMP_XIX_HCP3_CANFD01: start 18, 2 bit, little-endian, data-type-policy=OVERRIDE, i-signal-type=PRIMITIVE, init-value=0, base-type=BT_KN_AMP_ECUKnockOut, compu {3=Cx3_Funktion_deaktiviert (CM_KN_AMP_ECUKnockOut_Cx3_Funktion_deaktiviert), 0=Cx0_Funktion_nicht_ausgeloest (CM_KN_AMP_ECUKnockOut_Cx0_Funktion_nicht_ausgeloest), 1=Cx1_Veto_war_aktiv (CM_KN_AMP_ECUKnockOut_Cx1_Veto_war_aktiv), 2=Cx2_Funktion_ausgeloest (CM_KN_AMP_ECUKnockOut_Cx2_Funktion_ausgeloest)}, range raw 0..3, transfer-property=PENDING  # Ausgabe des ECUKnockout-Status
          signal KN_AMP_DiagPfad_V12_XIX_KN_AMP_XIX_HCP3_CANFD01: start 20, 1 bit, little-endian, data-type-policy=OVERRIDE, i-signal-type=PRIMITIVE, init-value=0, base-type=BT_KN_AMP_DiagPfad_V12, compu {1=Cx1_inaktiv (CM_KN_AMP_DiagPfad_V12_Cx1_inaktiv), 0=Cx0_Aktiv (CM_KN_AMP_DiagPfad_V12_Cx0_Aktiv)}, range raw 0..1, transfer-property=PENDING, to HCP3_IONode(timeout 5 s)  # Kennzeichnung der Diagnosefaehigkeit des BusInterfaces eines Steuergeraetes (Knoten) Umfang LAH 80127 Bei Nutzung des Signal explizit pro angebundenem BusInterface zu setzen
          signal AMP_KD_Fehler_XIX_KN_AMP_XIX_HCP3_CANFD01: start 23, 1 bit, little-endian, data-type-policy=OVERRIDE, i-signal-type=PRIMITIVE, init-value=0, base-type=BT_AMP_KD_Fehler, compu {1=Cx1_KD_Fehler (CM_AMP_KD_Fehler_Cx1_KD_Fehler), 0=Cx0_Kein_KD_Fehler (CM_AMP_KD_Fehler_Cx0_Kein_KD_Fehler) (Kein KD_Fehler)}, range raw 0..1, transfer-property=PENDING, to HCP3_IONode(timeout 2.5 s)  # Bei gesetztem Bit ist mindestens ein Kundendienstfehler eingetragen
          signal KN_AMP_ECUKnockOutTimer_XIX_KN_AMP_XIX_HCP3_CANFD01: start 24, 6 bit, little-endian, data-type-policy=OVERRIDE, i-signal-type=PRIMITIVE, init-value=15, base-type=BT_KN_AMP_ECUKnockOutTimer, compu {phys=raw for raw 0..62, 63=Cx3f_ECUKnockOut_deaktiviert (CM_KN_AMP_ECUKnockOutTimer_Cx3f_ECUKnockOut_deaktiviert)}, range phys 0..62, raw 0..63, transfer-property=PENDING  # Ausgabe des ECUKnockOut-Timer
          signal KN_AMP_BusKnockOut_XIX_KN_AMP_XIX_HCP3_CANFD01: start 30, 2 bit, little-endian, data-type-policy=OVERRIDE, i-signal-type=PRIMITIVE, init-value=0, base-type=BT_KN_AMP_BusKnockOut, compu {0=Cx0_Funktion_nicht_ausgeloest (CM_KN_AMP_BusKnockOut_Cx0_Funktion_nicht_ausgeloest), 2=Cx2_Funktion_ausgeloest (CM_KN_AMP_BusKnockOut_Cx2_Funktion_ausgeloest), 3=Cx3_Funktion_deaktiviert (CM_KN_AMP_BusKnockOut_Cx3_Funktion_deaktiviert), 1=Cx1_Veto_aktiv (CM_KN_AMP_BusKnockOut_Cx1_Veto_aktiv)}, range raw 0..3, transfer-property=PENDING  # Ausgabe des BusKnockout-Status
          signal KN_AMP_BusKnockOutTimer_XIX_KN_AMP_XIX_HCP3_CANFD01: start 32, 8 bit, little-endian, data-type-policy=OVERRIDE, i-signal-type=PRIMITIVE, init-value=15, base-type=BT_KN_AMP_BusKnockOutTimer, compu {phys=raw for raw 0..254, 255=Cxff_BusKnockOut_deaktiviert (CM_KN_AMP_BusKnockOutTimer_Cxff_BusKnockOut_deaktiviert)}, range phys 0..254, raw 0..255, transfer-property=PENDING  # Ausgabe des BusKnockOut-Timer
          signal NM_AMP_FCIB_XIX_KN_AMP_XIX_HCP3_CANFD01: start 40, 56 bit, opaque, data-type-policy=OVERRIDE, i-signal-type=ARRAY, init-value=[1, 0, 1, 0, 0, 8, 0], base-type=BT_NM_AMP_FCIB, compu {70368744177664=Cx400000000000_47_Diagnosis_ComfortLINs (CM_NM_AMP_FCIB_Cx400000000000_47_Diagnosis_ComfortLINs), 131072=Cx20000_18_VirtualSideMirrors (CM_NM_AMP_FCIB_Cx20000_18_VirtualSideMirrors), 140737488355328=Cx800000000000_48_Diagnosis_ClimateTmeLINs (CM_NM_AMP_FCIB_Cx800000000000_48_Diagnosis_ClimateTmeLINs), 8796093022208=Cx80000000000_44_Diagnosis_Infotainment (CM_NM_AMP_FCIB_Cx80000000000_44_Diagnosis_Infotainment), 36028797018963968=Cx80000000000000_56_ChargingStatus (CM_NM_AMP_FCIB_Cx80000000000000_56_ChargingStatus), 1073741824=Cx40000000_31_MultifunctionalSteeringWheel (CM_NM_AMP_FCIB_Cx40000000_31_MultifunctionalSteeringWheel), 4096=Cx1000_13_Airbag (CM_NM_AMP_FCIB_Cx1000_13_Airbag), 2=Cx2_02_Basefunction_Powertrain (CM_NM_AMP_FCIB_Cx2_02_Basefunction_Powertrain), 134217728=Cx8000000_28_OnboardTester_DataCollector (CM_NM_AMP_FCIB_Cx8000000_28_OnboardTester_DataCollector), 16777216=Cx1000000_25_AccessSystemSensors (CM_NM_AMP_FCIB_Cx1000000_25_AccessSystemSensors), 68719476736=Cx1000000000_37_HighVoltage_WirelessChargingStation (CM_NM_AMP_FCIB_Cx1000000000_37_HighVoltage_WirelessChargingStation), 16384=Cx4000_15_InstrumentclusterDisplay (CM_NM_AMP_FCIB_Cx4000_15_InstrumentclusterDisplay), 1024=Cx400_11_Chassis (CM_NM_AMP_FCIB_Cx400_11_Chassis), 2097152=Cx200000_22_ExteriorLights (CM_NM_AMP_FCIB_Cx200000_22_ExteriorLights), 4=Cx4_03_Basefunction_Chassis (CM_NM_AMP_FCIB_Cx4_03_Basefunction_Chassis), 268435456=Cx10000000_29_SteeringColumnLock (CM_NM_AMP_FCIB_Cx10000000_29_SteeringColumnLock), 8=Cx8_04_Basefunction_DrivingAssistance (CM_NM_AMP_FCIB_Cx8_04_Basefunction_DrivingAssistance), 33554432=Cx2000000_26_HighVoltage_Charging (CM_NM_AMP_FCIB_Cx2000000_26_HighVoltage_Charging), 17179869184=Cx400000000_35_ExteriorSound (CM_NM_AMP_FCIB_Cx400000000_35_ExteriorSound), 4503599627370496=Cx10000000000000_53_Lock_Unlock (CM_NM_AMP_FCIB_Cx10000000000000_53_Lock_Unlock), 8192=Cx2000_14_InfotainmentExtensions (CM_NM_AMP_FCIB_Cx2000_14_InfotainmentExtensions), 16=Cx10_05_Basefunction_Infotainment (CM_NM_AMP_FCIB_Cx10_05_Basefunction_Infotainment), 262144=Cx40000_19_Doors_Hatches (CM_NM_AMP_FCIB_Cx40000_19_Doors_Hatches), 1=Cx1_01_CarWakeUp (CM_NM_AMP_FCIB_Cx1_01_CarWakeUp), 281474976710656=Cx1000000000000_49_reserved (CM_NM_AMP_FCIB_Cx1000000000000_49_reserved) (49_<reserved>), 4194304=Cx400000_23_Climate (CM_NM_AMP_FCIB_Cx400000_23_Climate), 67108864=Cx4000000_27_Timemaster_Timer (CM_NM_AMP_FCIB_Cx4000000_27_Timemaster_Timer), 128=Cx80_08_Basefunction_Connectivity (CM_NM_AMP_FCIB_Cx80_08_Basefunction_Connectivity), 549755813888=Cx8000000000_40_Diagnosis_Energy (CM_NM_AMP_FCIB_Cx8000000000_40_Diagnosis_Energy), 4398046511104=Cx40000000000_43_Diagnosis_DrivingAssistance (CM_NM_AMP_FCIB_Cx40000000000_43_Diagnosis_DrivingAssistance), 2048=Cx800_12_GearSelector (CM_NM_AMP_FCIB_Cx800_12_GearSelector), 8796093087745=Cx80000010001_InitValueFCIB (CM_NM_AMP_FCIB_Cx80000010001_InitValueFCIB), 2199023255552=Cx20000000000_42_Diagnosis_FlexRay (CM_NM_AMP_FCIB_Cx20000000000_42_Diagnosis_FlexRay), 65536=Cx10000_17_Audio (CM_NM_AMP_FCIB_Cx10000_17_Audio), 32=Cx20_06_Basefunction_ComfortLight (CM_NM_AMP_FCIB_Cx20_06_Basefunction_ComfortLight), 35184372088832=Cx200000000000_46_Diagnosis_Light (CM_NM_AMP_FCIB_Cx200000000000_46_Diagnosis_Light), 32768=Cx8000_16_InfotainmentDisplay (CM_NM_AMP_FCIB_Cx8000_16_InfotainmentDisplay), 512=Cx200_10_Powertrain (CM_NM_AMP_FCIB_Cx200_10_Powertrain), 34359738368=Cx800000000_36_Preheater (CM_NM_AMP_FCIB_Cx800000000_36_Preheater), 2147483648=Cx80000000_32_OnlineAccess (CM_NM_AMP_FCIB_Cx80000000_32_OnlineAccess), 524288=Cx80000_20_OptionalComfort (CM_NM_AMP_FCIB_Cx80000_20_OptionalComfort), 8388608=Cx800000_24_ThermoManagement (CM_NM_AMP_FCIB_Cx800000_24_ThermoManagement), 1048576=Cx100000_21_AirSuspension (CM_NM_AMP_FCIB_Cx100000_21_AirSuspension), 18014398509481984=Cx40000000000000_55_Dimming (CM_NM_AMP_FCIB_Cx40000000000000_55_Dimming), 1099511627776=Cx10000000000_41_Diagnosis_Powertrain (CM_NM_AMP_FCIB_Cx10000000000_41_Diagnosis_Powertrain), 8589934592=Cx200000000_34_GPS_Localization (CM_NM_AMP_FCIB_Cx200000000_34_GPS_Localization), 9007199254740992=Cx20000000000000_54_reserved (CM_NM_AMP_FCIB_Cx20000000000000_54_reserved) (54_<reserved>), 17592186044416=Cx100000000000_45_Diagnosis_Comfort (CM_NM_AMP_FCIB_Cx100000000000_45_Diagnosis_Comfort), 4294967296=Cx100000000_33_ExternalWirelessCommunication (CM_NM_AMP_FCIB_Cx100000000_33_ExternalWirelessCommunication), 64=Cx40_07_Basefunction_CrossSection (CM_NM_AMP_FCIB_Cx40_07_Basefunction_CrossSection), 256=Cx100_09_reserved (CM_NM_AMP_FCIB_Cx100_09_reserved) (09_<reserved>), 536870912=Cx20000000_30_EnergyManagement (CM_NM_AMP_FCIB_Cx20000000_30_EnergyManagement)}, range raw 1..36028797018963968, transfer-property=PENDING, to HCP3_IONode(timeout 5 s)  # FCIB = Funktions-Cluster-Initialisierungs-Bits
      frame KN_CCF_XIX_HCP3_CANFD01: id 0x17F00124, to HCP3_IONode, frame-length=16, can-addressing-mode=EXTENDED, can-frame-rx-behavior=CAN-FD, can-frame-tx-behavior=CAN-FD
        pdu KN_CCF_XIX_HCP3_CANFD01: length=16, transmission-mode-true-timing=cyclic-timing={time-offset=0.0, time-period=0.5}, unused-bit-pattern=0
          signal CCF_SNI_10_XIX_KN_CCF_XIX_HCP3_CANFD01: start 8, 10 bit, little-endian, data-type-policy=OVERRIDE, i-signal-type=PRIMITIVE, init-value=292, base-type=BT_CCF_SNI_10, compu {phys=raw for raw 0..1023}, range phys 0..1023, raw 0..1023, transfer-property=PENDING, to HCP3_IONode(timeout 5 s)  # Source Node-Identifier (SNI) identifiziert den Sender der NM-Botschaft (Knotenadresse) eindeutig im Fahrzeug
          signal KN_CCF_ECUKnockOut_XIX_KN_CCF_XIX_HCP3_CANFD01: start 18, 2 bit, little-endian, data-type-policy=OVERRIDE, i-signal-type=PRIMITIVE, init-value=0, base-type=BT_KN_CCF_ECUKnockOut, compu {1=Cx1_Veto_war_aktiv (CM_KN_CCF_ECUKnockOut_Cx1_Veto_war_aktiv), 2=Cx2_Funktion_ausgeloest (CM_KN_CCF_ECUKnockOut_Cx2_Funktion_ausgeloest), 3=Cx3_Funktion_deaktiviert (CM_KN_CCF_ECUKnockOut_Cx3_Funktion_deaktiviert), 0=Cx0_Funktion_nicht_ausgeloest (CM_KN_CCF_ECUKnockOut_Cx0_Funktion_nicht_ausgeloest)}, range raw 0..3, transfer-property=PENDING  # Ausgabe des ECUKnockout-Status
          signal KN_CCF_DiagPfad_V12_XIX_KN_CCF_XIX_HCP3_CANFD01: start 20, 1 bit, little-endian, data-type-policy=OVERRIDE, i-signal-type=PRIMITIVE, init-value=0, base-type=BT_KN_CCF_DiagPfad_V12, compu {0=Cx0_Aktiv (CM_KN_CCF_DiagPfad_V12_Cx0_Aktiv), 1=Cx1_inaktiv (CM_KN_CCF_DiagPfad_V12_Cx1_inaktiv)}, range raw 0..1, transfer-property=PENDING, to HCP3_IONode(timeout 5 s)  # Kennzeichnung der Diagnosefaehigkeit des BusInterfaces eines Steuergeraetes (Knoten) Umfang LAH 80127 Bei Nutzung des Signal explizit pro angebundenem BusInterface zu setzen
          signal CCF_KD_Fehler_XIX_KN_CCF_XIX_HCP3_CANFD01: start 23, 1 bit, little-endian, data-type-policy=OVERRIDE, i-signal-type=PRIMITIVE, init-value=0, base-type=BT_CCF_KD_Fehler, compu {1=Cx1_KD_Fehler (CM_CCF_KD_Fehler_Cx1_KD_Fehler), 0=Cx0_Kein_KD_Fehler (CM_CCF_KD_Fehler_Cx0_Kein_KD_Fehler)}, range raw 0..1, transfer-property=PENDING, to HCP3_IONode(timeout 5 s)  # Bei gesetztem Bit ist mindestens ein Kundendienstfehler eingetragen
          signal KN_CCF_ECUKnockOutTimer_XIX_KN_CCF_XIX_HCP3_CANFD01: start 24, 6 bit, little-endian, data-type-policy=OVERRIDE, i-signal-type=PRIMITIVE, init-value=15, base-type=BT_KN_CCF_ECUKnockOutTimer, compu {phys=raw for raw 0..62, 63=Cx3f_ECUKnockOut_deaktiviert (CM_KN_CCF_ECUKnockOutTimer_Cx3f_ECUKnockOut_deaktiviert); unit Unit_Minut}, range phys 0..62 Unit_Minut, raw 0..63, unit=Unit_Minut, transfer-property=PENDING  # Ausgabe des ECUKnockOut-Timer
          signal KN_CCF_BusKnockOut_XIX_KN_CCF_XIX_HCP3_CANFD01: start 30, 2 bit, little-endian, data-type-policy=OVERRIDE, i-signal-type=PRIMITIVE, init-value=0, base-type=BT_KN_CCF_BusKnockOut, compu {0=Cx0_Funktion_nicht_ausgeloest (CM_KN_CCF_BusKnockOut_Cx0_Funktion_nicht_ausgeloest), 1=Cx1_Veto_aktiv (CM_KN_CCF_BusKnockOut_Cx1_Veto_aktiv), 3=Cx3_Funktion_deaktiviert (CM_KN_CCF_BusKnockOut_Cx3_Funktion_deaktiviert), 2=Cx2_Funktion_ausgeloest (CM_KN_CCF_BusKnockOut_Cx2_Funktion_ausgeloest)}, range raw 0..3, transfer-property=PENDING  # Ausgabe des BusKnockout-Status
          signal KN_CCF_BusKnockOutTimer_XIX_KN_CCF_XIX_HCP3_CANFD01: start 32, 8 bit, little-endian, data-type-policy=OVERRIDE, i-signal-type=PRIMITIVE, init-value=15, base-type=BT_KN_CCF_BusKnockOutTimer, compu {phys=raw for raw 0..254, 255=Cxff_BusKnockOut_deaktiviert (CM_KN_CCF_BusKnockOutTimer_Cxff_BusKnockOut_deaktiviert); unit Unit_Minut}, range phys 0..254 Unit_Minut, raw 0..255, unit=Unit_Minut, transfer-property=PENDING  # Ausgabe des BusKnockOut-Timer
          signal NM_CCF_FCIB_XIX_KN_CCF_XIX_HCP3_CANFD01: start 40, 56 bit, opaque, data-type-policy=OVERRIDE, i-signal-type=ARRAY, init-value=[1, 128, 0, 0, 0, 8, 0], base-type=BT_NM_CCF_FCIB, compu {8192=Cx2000_14_InfotainmentExtensions (CM_NM_CCF_FCIB_Cx2000_14_InfotainmentExtensions), 4294967296=Cx100000000_33_ExternalWirelessCommunication (CM_NM_CCF_FCIB_Cx100000000_33_ExternalWirelessCommunication), 9007199254740992=Cx20000000000000_54_reserved (CM_NM_CCF_FCIB_Cx20000000000000_54_reserved) (54_<reserved>), 32=Cx20_06_Basefunction_ComfortLight (CM_NM_CCF_FCIB_Cx20_06_Basefunction_ComfortLight), 1073741824=Cx40000000_31_MultifunctionalSteeringWheel (CM_NM_CCF_FCIB_Cx40000000_31_MultifunctionalSteeringWheel), 524288=Cx80000_20_OptionalComfort (CM_NM_CCF_FCIB_Cx80000_20_OptionalComfort), 17179869184=Cx400000000_35_ExteriorSound (CM_NM_CCF_FCIB_Cx400000000_35_ExteriorSound), 131072=Cx20000_18_VirtualSideMirrors (CM_NM_CCF_FCIB_Cx20000_18_VirtualSideMirrors), 33554432=Cx2000000_26_HighVoltage_Charging (CM_NM_CCF_FCIB_Cx2000000_26_HighVoltage_Charging), 2=Cx2_02_Basefunction_Powertrain (CM_NM_CCF_FCIB_Cx2_02_Basefunction_Powertrain), 16384=Cx4000_15_InstrumentclusterDisplay (CM_NM_CCF_FCIB_Cx4000_15_InstrumentclusterDisplay), 1099511627776=Cx10000000000_41_Diagnosis_Powertrain (CM_NM_CCF_FCIB_Cx10000000000_41_Diagnosis_Powertrain), 36028797018963968=Cx80000000000000_56_ChargingStatus (CM_NM_CCF_FCIB_Cx80000000000000_56_ChargingStatus), 16=Cx10_05_Basefunction_Infotainment (CM_NM_CCF_FCIB_Cx10_05_Basefunction_Infotainment), 65536=Cx10000_17_Audio (CM_NM_CCF_FCIB_Cx10000_17_Audio), 4=Cx4_03_Basefunction_Chassis (CM_NM_CCF_FCIB_Cx4_03_Basefunction_Chassis), 2147483648=Cx80000000_32_OnlineAccess (CM_NM_CCF_FCIB_Cx80000000_32_OnlineAccess), 4096=Cx1000_13_Airbag (CM_NM_CCF_FCIB_Cx1000_13_Airbag), 262144=Cx40000_19_Doors_Hatches (CM_NM_CCF_FCIB_Cx40000_19_Doors_Hatches), 18014398509481984=Cx40000000000000_55_Dimming (CM_NM_CCF_FCIB_Cx40000000000000_55_Dimming), 4398046511104=Cx40000000000_43_Diagnosis_DrivingAssistance (CM_NM_CCF_FCIB_Cx40000000000_43_Diagnosis_DrivingAssistance), 2048=Cx800_12_GearSelector (CM_NM_CCF_FCIB_Cx800_12_GearSelector), 549755813888=Cx8000000000_40_Diagnosis_Energy (CM_NM_CCF_FCIB_Cx8000000000_40_Diagnosis_Energy), 2097152=Cx200000_22_ExteriorLights (CM_NM_CCF_FCIB_Cx200000_22_ExteriorLights), 68719476736=Cx1000000000_37_HighVoltage_WirelessChargingStation (CM_NM_CCF_FCIB_Cx1000000000_37_HighVoltage_WirelessChargingStation), 8796093054977=Cx80000008001_InitValueFCIB (CM_NM_CCF_FCIB_Cx80000008001_InitValueFCIB), 8=Cx8_04_Basefunction_DrivingAssistance (CM_NM_CCF_FCIB_Cx8_04_Basefunction_DrivingAssistance), 70368744177664=Cx400000000000_47_Diagnosis_ComfortLINs (CM_NM_CCF_FCIB_Cx400000000000_47_Diagnosis_ComfortLINs), 4503599627370496=Cx10000000000000_53_Lock_Unlock (CM_NM_CCF_FCIB_Cx10000000000000_53_Lock_Unlock), 35184372088832=Cx200000000000_46_Diagnosis_Light (CM_NM_CCF_FCIB_Cx200000000000_46_Diagnosis_Light), 140737488355328=Cx800000000000_48_Diagnosis_ClimateTmeLINs (CM_NM_CCF_FCIB_Cx800000000000_48_Diagnosis_ClimateTmeLINs), 2199023255552=Cx20000000000_42_Diagnosis_FlexRay (CM_NM_CCF_FCIB_Cx20000000000_42_Diagnosis_FlexRay), 128=Cx80_08_Basefunction_Connectivity (CM_NM_CCF_FCIB_Cx80_08_Basefunction_Connectivity), 64=Cx40_07_Basefunction_CrossSection (CM_NM_CCF_FCIB_Cx40_07_Basefunction_CrossSection), 17592186044416=Cx100000000000_45_Diagnosis_Comfort (CM_NM_CCF_FCIB_Cx100000000000_45_Diagnosis_Comfort), 34359738368=Cx800000000_36_Preheater (CM_NM_CCF_FCIB_Cx800000000_36_Preheater), 256=Cx100_09_reserved (CM_NM_CCF_FCIB_Cx100_09_reserved) (09_<reserved>), 536870912=Cx20000000_30_EnergyManagement (CM_NM_CCF_FCIB_Cx20000000_30_EnergyManagement), 32768=Cx8000_16_InfotainmentDisplay (CM_NM_CCF_FCIB_Cx8000_16_InfotainmentDisplay), 268435456=Cx10000000_29_SteeringColumnLock (CM_NM_CCF_FCIB_Cx10000000_29_SteeringColumnLock), 8388608=Cx800000_24_ThermoManagement (CM_NM_CCF_FCIB_Cx800000_24_ThermoManagement), 1048576=Cx100000_21_AirSuspension (CM_NM_CCF_FCIB_Cx100000_21_AirSuspension), 281474976710656=Cx1000000000000_49_reserved (CM_NM_CCF_FCIB_Cx1000000000000_49_reserved) (49_<reserved>), 67108864=Cx4000000_27_Timemaster_Timer (CM_NM_CCF_FCIB_Cx4000000_27_Timemaster_Timer), 512=Cx200_10_Powertrain (CM_NM_CCF_FCIB_Cx200_10_Powertrain), 8796093022208=Cx80000000000_44_Diagnosis_Infotainment (CM_NM_CCF_FCIB_Cx80000000000_44_Diagnosis_Infotainment), 8589934592=Cx200000000_34_GPS_Localization (CM_NM_CCF_FCIB_Cx200000000_34_GPS_Localization), 134217728=Cx8000000_28_OnboardTester_DataCollector (CM_NM_CCF_FCIB_Cx8000000_28_OnboardTester_DataCollector), 1=Cx1_01_CarWakeUp (CM_NM_CCF_FCIB_Cx1_01_CarWakeUp), 16777216=Cx1000000_25_AccessSystemSensors (CM_NM_CCF_FCIB_Cx1000000_25_AccessSystemSensors), 1024=Cx400_11_Chassis (CM_NM_CCF_FCIB_Cx400_11_Chassis), 4194304=Cx400000_23_Climate (CM_NM_CCF_FCIB_Cx400000_23_Climate)}, range raw 1..36028797018963968, transfer-property=PENDING, to HCP3_IONode(timeout 5 s)  # FCIB = Funktions-Cluster-Initialisierungs-Bits
      frame KN_CID_XIX_HCP3_CANFD01: id 0x17F00122, to HCP3_IONode, frame-length=16, can-addressing-mode=EXTENDED, can-frame-rx-behavior=CAN-FD, can-frame-tx-behavior=CAN-FD
        pdu KN_CID_XIX_HCP3_CANFD01: length=16, transmission-mode-true-timing=cyclic-timing={time-offset=0.0, time-period=0.5}, unused-bit-pattern=0
          signal CID_Nachlauftyp_XIX_KN_CID_XIX_HCP3_CANFD01: start 4, 4 bit, little-endian, data-type-policy=OVERRIDE, i-signal-type=PRIMITIVE, init-value=2, base-type=BT_CID_Nachlauftyp, compu {0=Cx0_Komm_bei_KL15_EIN (CM_CID_Nachlauftyp_Cx0_Komm_bei_KL15_EIN), 1=Cx1_Komm_nach_KL15_AUS (CM_CID_Nachlauftyp_Cx1_Komm_nach_KL15_AUS), 2=Cx2_Komm_bei_KL15_AUS (CM_CID_Nachlauftyp_Cx2_Komm_bei_KL15_AUS)}, range raw 0..2, transfer-property=PENDING, to HCP3_IONode(timeout 5 s)  # Abgebildet wird die von der Hardware vorgegebene Möglichkeit, die Kommunikation nach Klemme 15 = AUS aufrecht zu erhalten. Es wird ein Init-Wert gesendet.
          signal CID_SNI_10_XIX_KN_CID_XIX_HCP3_CANFD01: start 8, 10 bit, little-endian, data-type-policy=OVERRIDE, i-signal-type=PRIMITIVE, init-value=290, base-type=BT_CID_SNI_10, compu {phys=raw for raw 0..1023}, range phys 0..1023, raw 0..1023, transfer-property=PENDING, to HCP3_IONode(timeout 5 s)  # Source Node-Identifier (SNI) identifiziert den Sender der NM-Botschaft (Knotenadresse) eindeutig im Fahrzeug
          signal KN_CID_ECUKnockOut_XIX_KN_CID_XIX_HCP3_CANFD01: start 18, 2 bit, little-endian, data-type-policy=OVERRIDE, i-signal-type=PRIMITIVE, init-value=0, base-type=BT_KN_CID_ECUKnockOut, compu {1=Cx1_Veto_war_aktiv (CM_KN_CID_ECUKnockOut_Cx1_Veto_war_aktiv), 2=Cx2_Funktion_ausgeloest (CM_KN_CID_ECUKnockOut_Cx2_Funktion_ausgeloest), 0=Cx0_Funktion_nicht_ausgeloest (CM_KN_CID_ECUKnockOut_Cx0_Funktion_nicht_ausgeloest), 3=Cx3_Funktion_deaktiviert (CM_KN_CID_ECUKnockOut_Cx3_Funktion_deaktiviert)}, range raw 0..3, transfer-property=PENDING  # Ausgabe des ECUKnockout-Status
          signal KN_CID_DiagPfad_V12_XIX_KN_CID_XIX_HCP3_CANFD01: start 20, 1 bit, little-endian, data-type-policy=OVERRIDE, i-signal-type=PRIMITIVE, init-value=0, base-type=BT_KN_CID_DiagPfad_V12, compu {0=Cx0_Aktiv (CM_KN_CID_DiagPfad_V12_Cx0_Aktiv), 1=Cx1_inaktiv (CM_KN_CID_DiagPfad_V12_Cx1_inaktiv)}, range raw 0..1, transfer-property=PENDING, to HCP3_IONode(timeout 5 s)  # Kennzeichnung der Diagnosefaehigkeit des BusInterfaces eines Steuergeraetes (Knoten) Umfang LAH 80127 Bei Nutzung des Signal explizit pro angebundenem BusInterface zu setzen
          signal NM_CID_Lokalaktiv_XIX_KN_CID_XIX_HCP3_CANFD01: start 21, 1 bit, little-endian, data-type-policy=OVERRIDE, i-signal-type=PRIMITIVE, init-value=0, base-type=BT_NM_CID_Lokalaktiv, compu {0=Cx0_war_nicht_lokal_aktiv (CM_NM_CID_Lokalaktiv_Cx0_war_nicht_lokal_aktiv), 1=Cx1_war_lokal_aktiv (CM_NM_CID_Lokalaktiv_Cx1_war_lokal_aktiv)}, range raw 0..1, transfer-property=PENDING  # Zeigt an ob das SG nach Klemme15 AUS und nach entsprechender MAX Aktivzeit noch aktiv war.
          signal NM_CID_Subsystemaktiv_XIX_KN_CID_XIX_HCP3_CANFD01: start 22, 1 bit, little-endian, data-type-policy=OVERRIDE, i-signal-type=PRIMITIVE, init-value=0, base-type=BT_NM_CID_Subsystemaktiv, compu {0=Cx0_war_nicht_lokal_aktiv (CM_NM_CID_Subsystemaktiv_Cx0_war_nicht_lokal_aktiv), 1=Cx1_war_lokal_aktiv (CM_NM_CID_Subsystemaktiv_Cx1_war_lokal_aktiv)}, range raw 0..1, transfer-property=PENDING  # Zeigt an ob ein Subsystem des SGs nach Klemme15 AUS und nach entsprechender MAX Aktivzeit noch aktiv war
          signal CID_KD_Fehler_XIX_KN_CID_XIX_HCP3_CANFD01: start 23, 1 bit, little-endian, data-type-policy=OVERRIDE, i-signal-type=PRIMITIVE, init-value=0, base-type=BT_CID_KD_Fehler, compu {0=Cx0_Kein_KD_Fehler (CM_CID_KD_Fehler_Cx0_Kein_KD_Fehler), 1=Cx1_KD_Fehler (CM_CID_KD_Fehler_Cx1_KD_Fehler)}, range raw 0..1, transfer-property=PENDING, to HCP3_IONode(timeout 2.5 s)  # Bei gesetztem Bit ist mindestens ein Kundendienstfehler eingetragen
          signal KN_CID_ECUKnockOutTimer_XIX_KN_CID_XIX_HCP3_CANFD01: start 24, 6 bit, little-endian, data-type-policy=OVERRIDE, i-signal-type=PRIMITIVE, init-value=15, base-type=BT_KN_CID_ECUKnockOutTimer, compu {phys=raw for raw 0..62, 63=Cx3f_ECUKnockOut_deaktiviert (CM_KN_CID_ECUKnockOutTimer_Cx3f_ECUKnockOut_deaktiviert)}, range phys 0..62, raw 0..63, transfer-property=PENDING  # Ausgabe des ECUKnockOut-Timer
          signal KN_CID_BusKnockOut_XIX_KN_CID_XIX_HCP3_CANFD01: start 30, 2 bit, little-endian, data-type-policy=OVERRIDE, i-signal-type=PRIMITIVE, init-value=0, base-type=BT_KN_CID_BusKnockOut, compu {1=Cx1_Veto_aktiv (CM_KN_CID_BusKnockOut_Cx1_Veto_aktiv), 0=Cx0_Funktion_nicht_ausgeloest (CM_KN_CID_BusKnockOut_Cx0_Funktion_nicht_ausgeloest), 2=Cx2_Funktion_ausgeloest (CM_KN_CID_BusKnockOut_Cx2_Funktion_ausgeloest), 3=Cx3_Funktion_deaktiviert (CM_KN_CID_BusKnockOut_Cx3_Funktion_deaktiviert)}, range raw 0..3, transfer-property=PENDING  # Ausgabe des BusKnockout-Status
          signal KN_CID_BusKnockOutTimer_XIX_KN_CID_XIX_HCP3_CANFD01: start 32, 8 bit, little-endian, data-type-policy=OVERRIDE, i-signal-type=PRIMITIVE, init-value=15, base-type=BT_KN_CID_BusKnockOutTimer, compu {phys=raw for raw 0..254, 255=Cxff_BusKnockOut_deaktiviert (CM_KN_CID_BusKnockOutTimer_Cxff_BusKnockOut_deaktiviert)}, range phys 0..254, raw 0..255, transfer-property=PENDING  # Ausgabe des BusKnockOut-Timer
          signal NM_CID_FCIB_XIX_KN_CID_XIX_HCP3_CANFD01: start 40, 56 bit, opaque, data-type-policy=OVERRIDE, i-signal-type=ARRAY, init-value=[1, 128, 0, 0, 0, 8, 0], base-type=BT_NM_CID_FCIB, compu {32=Cx20_06_Basefunction_ComfortLight (CM_NM_CID_FCIB_Cx20_06_Basefunction_ComfortLight), 1099511627776=Cx10000000000_41_Diagnosis_Powertrain (CM_NM_CID_FCIB_Cx10000000000_41_Diagnosis_Powertrain), 134217728=Cx8000000_28_OnboardTester_DataCollector (CM_NM_CID_FCIB_Cx8000000_28_OnboardTester_DataCollector), 8=Cx8_04_Basefunction_DrivingAssistance (CM_NM_CID_FCIB_Cx8_04_Basefunction_DrivingAssistance), 1=Cx1_01_CarWakeUp (CM_NM_CID_FCIB_Cx1_01_CarWakeUp), 34359738368=Cx800000000_36_Preheater (CM_NM_CID_FCIB_Cx800000000_36_Preheater), 536870912=Cx20000000_30_EnergyManagement (CM_NM_CID_FCIB_Cx20000000_30_EnergyManagement), 268435456=Cx10000000_29_SteeringColumnLock (CM_NM_CID_FCIB_Cx10000000_29_SteeringColumnLock), 65536=Cx10000_17_Audio (CM_NM_CID_FCIB_Cx10000_17_Audio), 1048576=Cx100000_21_AirSuspension (CM_NM_CID_FCIB_Cx100000_21_AirSuspension), 17179869184=Cx400000000_35_ExteriorSound (CM_NM_CID_FCIB_Cx400000000_35_ExteriorSound), 4398046511104=Cx40000000000_43_Diagnosis_DrivingAssistance (CM_NM_CID_FCIB_Cx40000000000_43_Diagnosis_DrivingAssistance), 36028797018963968=Cx80000000000000_56_ChargingStatus (CM_NM_CID_FCIB_Cx80000000000000_56_ChargingStatus), 2048=Cx800_12_GearSelector (CM_NM_CID_FCIB_Cx800_12_GearSelector), 4096=Cx1000_13_Airbag (CM_NM_CID_FCIB_Cx1000_13_Airbag), 8796093022208=Cx80000000000_44_Diagnosis_Infotainment (CM_NM_CID_FCIB_Cx80000000000_44_Diagnosis_Infotainment), 9007199254740992=Cx20000000000000_54_reserved (CM_NM_CID_FCIB_Cx20000000000000_54_reserved) (54_<reserved>), 8589934592=Cx200000000_34_GPS_Localization (CM_NM_CID_FCIB_Cx200000000_34_GPS_Localization), 128=Cx80_08_Basefunction_Connectivity (CM_NM_CID_FCIB_Cx80_08_Basefunction_Connectivity), 67108864=Cx4000000_27_Timemaster_Timer (CM_NM_CID_FCIB_Cx4000000_27_Timemaster_Timer), 2147483648=Cx80000000_32_OnlineAccess (CM_NM_CID_FCIB_Cx80000000_32_OnlineAccess), 281474976710656=Cx1000000000000_49_reserved (CM_NM_CID_FCIB_Cx1000000000000_49_reserved) (49_<reserved>), 1024=Cx400_11_Chassis (CM_NM_CID_FCIB_Cx400_11_Chassis), 131072=Cx20000_18_VirtualSideMirrors (CM_NM_CID_FCIB_Cx20000_18_VirtualSideMirrors), 33554432=Cx2000000_26_HighVoltage_Charging (CM_NM_CID_FCIB_Cx2000000_26_HighVoltage_Charging), 68719476736=Cx1000000000_37_HighVoltage_WirelessChargingStation (CM_NM_CID_FCIB_Cx1000000000_37_HighVoltage_WirelessChargingStation), 2=Cx2_02_Basefunction_Powertrain (CM_NM_CID_FCIB_Cx2_02_Basefunction_Powertrain), 256=Cx100_09_reserved (CM_NM_CID_FCIB_Cx100_09_reserved) (09_<reserved>), 1073741824=Cx40000000_31_MultifunctionalSteeringWheel (CM_NM_CID_FCIB_Cx40000000_31_MultifunctionalSteeringWheel), 524288=Cx80000_20_OptionalComfort (CM_NM_CID_FCIB_Cx80000_20_OptionalComfort), 549755813888=Cx8000000000_40_Diagnosis_Energy (CM_NM_CID_FCIB_Cx8000000000_40_Diagnosis_Energy), 512=Cx200_10_Powertrain (CM_NM_CID_FCIB_Cx200_10_Powertrain), 8388608=Cx800000_24_ThermoManagement (CM_NM_CID_FCIB_Cx800000_24_ThermoManagement), 16777216=Cx1000000_25_AccessSystemSensors (CM_NM_CID_FCIB_Cx1000000_25_AccessSystemSensors), 2097152=Cx200000_22_ExteriorLights (CM_NM_CID_FCIB_Cx200000_22_ExteriorLights), 35184372088832=Cx200000000000_46_Diagnosis_Light (CM_NM_CID_FCIB_Cx200000000000_46_Diagnosis_Light), 4503599627370496=Cx10000000000000_53_Lock_Unlock (CM_NM_CID_FCIB_Cx10000000000000_53_Lock_Unlock), 64=Cx40_07_Basefunction_CrossSection (CM_NM_CID_FCIB_Cx40_07_Basefunction_CrossSection), 32768=Cx8000_16_InfotainmentDisplay (CM_NM_CID_FCIB_Cx8000_16_InfotainmentDisplay), 2199023255552=Cx20000000000_42_Diagnosis_FlexRay (CM_NM_CID_FCIB_Cx20000000000_42_Diagnosis_FlexRay), 4=Cx4_03_Basefunction_Chassis (CM_NM_CID_FCIB_Cx4_03_Basefunction_Chassis), 140737488355328=Cx800000000000_48_Diagnosis_ClimateTmeLINs (CM_NM_CID_FCIB_Cx800000000000_48_Diagnosis_ClimateTmeLINs), 17592186044416=Cx100000000000_45_Diagnosis_Comfort (CM_NM_CID_FCIB_Cx100000000000_45_Diagnosis_Comfort), 70368744177664=Cx400000000000_47_Diagnosis_ComfortLINs (CM_NM_CID_FCIB_Cx400000000000_47_Diagnosis_ComfortLINs), 262144=Cx40000_19_Doors_Hatches (CM_NM_CID_FCIB_Cx40000_19_Doors_Hatches), 4194304=Cx400000_23_Climate (CM_NM_CID_FCIB_Cx400000_23_Climate), 16384=Cx4000_15_InstrumentclusterDisplay (CM_NM_CID_FCIB_Cx4000_15_InstrumentclusterDisplay), 8192=Cx2000_14_InfotainmentExtensions (CM_NM_CID_FCIB_Cx2000_14_InfotainmentExtensions), 16=Cx10_05_Basefunction_Infotainment (CM_NM_CID_FCIB_Cx10_05_Basefunction_Infotainment), 18014398509481984=Cx40000000000000_55_Dimming (CM_NM_CID_FCIB_Cx40000000000000_55_Dimming), 8796093054977=Cx80000008001_InitValueFCIB (CM_NM_CID_FCIB_Cx80000008001_InitValueFCIB), 4294967296=Cx100000000_33_ExternalWirelessCommunication (CM_NM_CID_FCIB_Cx100000000_33_ExternalWirelessCommunication)}, range raw 1..36028797018963968, transfer-property=PENDING, to HCP3_IONode(timeout 5 s)  # FCIB = Funktions-Cluster-Initialisierungs-Bits
      frame KN_DispKBI_FS_XIX_HCP3_CANFD01: id 0x17F00109, to HCP3_IONode, frame-length=16, can-addressing-mode=EXTENDED, can-frame-rx-behavior=CAN-FD, can-frame-tx-behavior=CAN-FD
        pdu KN_DispKBI_FS_XIX_HCP3_CANFD01: length=16, transmission-mode-true-timing=cyclic-timing={time-offset=0, time-period=0.5}, unused-bit-pattern=0
          signal DispKBI_FS_KompSchutz_XIX_KN_DispKBI_FS_XIX_HCP3_CANFD01: start 0, 1 bit, little-endian, data-type-policy=OVERRIDE, i-signal-type=PRIMITIVE, init-value=0, base-type=BT_DispKBI_FS_KompSchutz, compu {0=Cx0_KS_nicht_aktiv (CM_DispKBI_FS_KompSchutz_Cx0_KS_nicht_aktiv), 1=Cx1_KS_aktiv (CM_DispKBI_FS_KompSchutz_Cx1_KS_aktiv)}, range raw 0..1, transfer-property=PENDING  # Signal wird gesetzt wenn Komponentenschutz (KS) im Steuergerät aktiv ist.
          signal DispKBI_FS_Abschaltstufe_XIX_KN_DispKBI_FS_XIX_HCP3_CANFD01: start 1, 1 bit, little-endian, data-type-policy=OVERRIDE, i-signal-type=PRIMITIVE, init-value=0, base-type=BT_DispKBI_FS_Abschaltstufe, compu {0=Cx0_keine_Einschraenkung (CM_DispKBI_FS_Abschaltstufe_Cx0_keine_Einschraenkung), 1=Cx1_Funktionseinschraenkung (CM_DispKBI_FS_Abschaltstufe_Cx1_Funktionseinschraenkung)}, range raw 0..1, transfer-property=PENDING  # Funktionseinschränkung aufgrund aktiver Abschaltstufe
          signal DispKBI_FS_Transport_Mode_XIX_KN_DispKBI_FS_XIX_HCP3_CANFD01: start 2, 1 bit, little-endian, data-type-policy=OVERRIDE, i-signal-type=PRIMITIVE, init-value=0, base-type=BT_DispKBI_FS_Transport_Mode, compu {1=Cx1_Funktionseinschraenkung (CM_DispKBI_FS_Transport_Mode_Cx1_Funktionseinschraenkung), 0=Cx0_keine_Einschraenkung (CM_DispKBI_FS_Transport_Mode_Cx0_keine_Einschraenkung)}, range raw 0..1, transfer-property=PENDING  # Funktionseinschränkung aufgrund aktivem Transport Mode und/oder Transport Schutz
          signal DispKBI_FS_Nachlauftyp_XIX_KN_DispKBI_FS_XIX_HCP3_CANFD01: start 4, 4 bit, little-endian, data-type-policy=OVERRIDE, i-signal-type=PRIMITIVE, init-value=2, base-type=BT_DispKBI_FS_Nachlauftyp, compu {0=Cx0_Komm_bei_KL15_EIN (CM_DispKBI_FS_Nachlauftyp_Cx0_Komm_bei_KL15_EIN), 1=Cx1_Komm_nach_KL15_AUS (CM_DispKBI_FS_Nachlauftyp_Cx1_Komm_nach_KL15_AUS), 2=Cx2_Komm_bei_KL15_AUS (CM_DispKBI_FS_Nachlauftyp_Cx2_Komm_bei_KL15_AUS)}, range raw 0..2, transfer-property=PENDING, to HCP3_IONode(timeout 5 s)  # Abgebildet wird die von der Hardware vorgegebene Möglichkeit, die Kommunikation nach Klemme 15 = AUS aufrecht zu erhalten. Es wird ein Init-Wert gesendet.
          signal DispKBI_FS_SNI_10_XIX_KN_DispKBI_FS_XIX_HCP3_CANFD01: start 8, 10 bit, little-endian, data-type-policy=OVERRIDE, i-signal-type=PRIMITIVE, init-value=265, base-type=BT_DispKBI_FS_SNI_10, compu {phys=raw for raw 0..1023}, range phys 0..1023, raw 0..1023, transfer-property=PENDING, to HCP3_IONode(timeout 5 s)  # Source Node-Identifier (SNI) identifiziert den Sender der NM-Botschaft (Knotenadresse) eindeutig im Fahrzeug
          signal KN_DispKBI_FS_ECUKnockOut_XIX_KN_DispKBI_FS_XIX_HCP3_CANFD01: start 18, 2 bit, little-endian, data-type-policy=OVERRIDE, i-signal-type=PRIMITIVE, init-value=0, base-type=BT_KN_DispKBI_FS_ECUKnockOut, compu {2=Cx2_Funktion_ausgeloest (CM_KN_DispKBI_FS_ECUKnockOut_Cx2_Funktion_ausgeloest), 0=Cx0_Funktion_nicht_ausgeloest (CM_KN_DispKBI_FS_ECUKnockOut_Cx0_Funktion_nicht_ausgeloest), 3=Cx3_Funktion_deaktiviert (CM_KN_DispKBI_FS_ECUKnockOut_Cx3_Funktion_deaktiviert), 1=Cx1_Veto_war_aktiv (CM_KN_DispKBI_FS_ECUKnockOut_Cx1_Veto_war_aktiv)}, range raw 0..3, transfer-property=PENDING  # Ausgabe des ECUKnockout-Status
          signal KN_DispKBI_FS_DiagPfad_V12_XIX_KN_DispKBI_FS_XIX_HCP3_CANFD01: start 20, 1 bit, little-endian, data-type-policy=OVERRIDE, i-signal-type=PRIMITIVE, init-value=0, base-type=BT_KN_DispKBI_FS_DiagPfad_V12, compu {0=Cx0_Aktiv (CM_KN_DispKBI_FS_DiagPfad_V12_Cx0_Aktiv), 1=Cx1_inaktiv (CM_KN_DispKBI_FS_DiagPfad_V12_Cx1_inaktiv)}, range raw 0..1, transfer-property=PENDING, to HCP3_IONode(timeout 5 s)  # Kennzeichnung der Diagnosefaehigkeit des BusInterfaces eines Steuergeraetes (Knoten) Umfang LAH 80127 Bei Nutzung des Signal explizit pro angebundenem BusInterface zu setzen
          signal DispKBI_FS_KD_Fehler_XIX_KN_DispKBI_FS_XIX_HCP3_CANFD01: start 23, 1 bit, little-endian, data-type-policy=OVERRIDE, i-signal-type=PRIMITIVE, init-value=0, base-type=BT_DispKBI_FS_KD_Fehler, compu {0=Cx0_Kein_KD_Fehler (CM_DispKBI_FS_KD_Fehler_Cx0_Kein_KD_Fehler) (Kein KD_Fehler), 1=Cx1_KD_Fehler (CM_DispKBI_FS_KD_Fehler_Cx1_KD_Fehler)}, range raw 0..1, transfer-property=PENDING, to HCP3_IONode(timeout 5 s)  # Bei gesetztem Bit ist mindestens ein Kundendienstfehler eingetragen
          signal KN_DispKBI_FS_ECUKnockOutTimer_XIX_KN_DispKBI_FS_XIX_HCP3_CANFD01: start 24, 6 bit, little-endian, data-type-policy=OVERRIDE, i-signal-type=PRIMITIVE, init-value=15, base-type=BT_KN_DispKBI_FS_ECUKnockOutTimer, compu {phys=raw for raw 0..62, 63=Cx3f_ECUKnockOut_deaktiviert (CM_KN_DispKBI_FS_ECUKnockOutTimer_Cx3f_ECUKnockOut_deaktiviert)}, range phys 0..62, raw 0..63, transfer-property=PENDING  # Ausgabe des ECUKnockOut-Timer
          signal KN_DispKBI_FS_BusKnockOut_XIX_KN_DispKBI_FS_XIX_HCP3_CANFD01: start 30, 2 bit, little-endian, data-type-policy=OVERRIDE, i-signal-type=PRIMITIVE, init-value=0, base-type=BT_KN_DispKBI_FS_BusKnockOut, compu {0=Cx0_Funktion_nicht_ausgeloest (CM_KN_DispKBI_FS_BusKnockOut_Cx0_Funktion_nicht_ausgeloest), 2=Cx2_Funktion_ausgeloest (CM_KN_DispKBI_FS_BusKnockOut_Cx2_Funktion_ausgeloest), 3=Cx3_Funktion_deaktiviert (CM_KN_DispKBI_FS_BusKnockOut_Cx3_Funktion_deaktiviert), 1=Cx1_Veto_aktiv (CM_KN_DispKBI_FS_BusKnockOut_Cx1_Veto_aktiv)}, range raw 0..3, transfer-property=PENDING  # Ausgabe des BusKnockout-Status
          signal KN_DispKBI_FS_BusKnockOutTimer_XIX_KN_DispKBI_FS_XIX_HCP3_CANFD01: start 32, 8 bit, little-endian, data-type-policy=OVERRIDE, i-signal-type=PRIMITIVE, init-value=15, base-type=BT_KN_DispKBI_FS_BusKnockOutTimer, compu {phys=raw for raw 0..254, 255=Cxff_BusKnockOut_deaktiviert (CM_KN_DispKBI_FS_BusKnockOutTimer_Cxff_BusKnockOut_deaktiviert)}, range phys 0..254, raw 0..255, transfer-property=PENDING  # Ausgabe des BusKnockOut-Timer
          signal NM_DispKBI_FS_FCIB_XIX_KN_DispKBI_FS_XIX_HCP3_CANFD01: start 40, 56 bit, opaque, data-type-policy=OVERRIDE, i-signal-type=ARRAY, init-value=[1, 66, 0, 0, 0, 16, 0], base-type=BT_NM_DispKBI_FS_FCIB, compu {1048576=Cx100000_21_AirSuspension (CM_NM_DispKBI_FS_FCIB_Cx100000_21_AirSuspension), 33554432=Cx2000000_26_HighVoltage_Charging (CM_NM_DispKBI_FS_FCIB_Cx2000000_26_HighVoltage_Charging), 134217728=Cx8000000_28_OnboardTester_DataCollector (CM_NM_DispKBI_FS_FCIB_Cx8000000_28_OnboardTester_DataCollector), 17179869184=Cx400000000_35_ExteriorSound (CM_NM_DispKBI_FS_FCIB_Cx400000000_35_ExteriorSound), 2199023255552=Cx20000000000_42_Diagnosis_FlexRay (CM_NM_DispKBI_FS_FCIB_Cx20000000000_42_Diagnosis_FlexRay), 16777216=Cx1000000_25_AccessSystemSensors (CM_NM_DispKBI_FS_FCIB_Cx1000000_25_AccessSystemSensors), 67108864=Cx4000000_27_Timemaster_Timer (CM_NM_DispKBI_FS_FCIB_Cx4000000_27_Timemaster_Timer), 70368744177664=Cx400000000000_47_Diagnosis_ComfortLINs (CM_NM_DispKBI_FS_FCIB_Cx400000000000_47_Diagnosis_ComfortLINs), 17592186044416=Cx100000000000_45_Diagnosis_Comfort (CM_NM_DispKBI_FS_FCIB_Cx100000000000_45_Diagnosis_Comfort), 32=Cx20_06_Basefunction_ComfortLight (CM_NM_DispKBI_FS_FCIB_Cx20_06_Basefunction_ComfortLight), 549755813888=Cx8000000000_40_Diagnosis_Energy (CM_NM_DispKBI_FS_FCIB_Cx8000000000_40_Diagnosis_Energy), 8388608=Cx800000_24_ThermoManagement (CM_NM_DispKBI_FS_FCIB_Cx800000_24_ThermoManagement), 2097152=Cx200000_22_ExteriorLights (CM_NM_DispKBI_FS_FCIB_Cx200000_22_ExteriorLights), 2147483648=Cx80000000_32_OnlineAccess (CM_NM_DispKBI_FS_FCIB_Cx80000000_32_OnlineAccess), 131072=Cx20000_18_VirtualSideMirrors (CM_NM_DispKBI_FS_FCIB_Cx20000_18_VirtualSideMirrors), 1073741824=Cx40000000_31_MultifunctionalSteeringWheel (CM_NM_DispKBI_FS_FCIB_Cx40000000_31_MultifunctionalSteeringWheel), 65536=Cx10000_17_Audio (CM_NM_DispKBI_FS_FCIB_Cx10000_17_Audio), 36028797018963968=Cx80000000000000_56_ChargingStatus (CM_NM_DispKBI_FS_FCIB_Cx80000000000000_56_ChargingStatus), 536870912=Cx20000000_30_EnergyManagement (CM_NM_DispKBI_FS_FCIB_Cx20000000_30_EnergyManagement), 2048=Cx800_12_GearSelector (CM_NM_DispKBI_FS_FCIB_Cx800_12_GearSelector), 2=Cx2_02_Basefunction_Powertrain (CM_NM_DispKBI_FS_FCIB_Cx2_02_Basefunction_Powertrain), 140737488355328=Cx800000000000_48_Diagnosis_ClimateTmeLINs (CM_NM_DispKBI_FS_FCIB_Cx800000000000_48_Diagnosis_ClimateTmeLINs), 4503599627370496=Cx10000000000000_53_Lock_Unlock (CM_NM_DispKBI_FS_FCIB_Cx10000000000000_53_Lock_Unlock), 64=Cx40_07_Basefunction_CrossSection (CM_NM_DispKBI_FS_FCIB_Cx40_07_Basefunction_CrossSection), 18014398509481984=Cx40000000000000_55_Dimming (CM_NM_DispKBI_FS_FCIB_Cx40000000000000_55_Dimming), 4=Cx4_03_Basefunction_Chassis (CM_NM_DispKBI_FS_FCIB_Cx4_03_Basefunction_Chassis), 268435456=Cx10000000_29_SteeringColumnLock (CM_NM_DispKBI_FS_FCIB_Cx10000000_29_SteeringColumnLock), 262144=Cx40000_19_Doors_Hatches (CM_NM_DispKBI_FS_FCIB_Cx40000_19_Doors_Hatches), 8796093022208=Cx80000000000_44_Diagnosis_Infotainment (CM_NM_DispKBI_FS_FCIB_Cx80000000000_44_Diagnosis_Infotainment), 17592186061313=Cx100000004201_InitValueFCIB (CM_NM_DispKBI_FS_FCIB_Cx100000004201_InitValueFCIB), 512=Cx200_10_Powertrain (CM_NM_DispKBI_FS_FCIB_Cx200_10_Powertrain), 1099511627776=Cx10000000000_41_Diagnosis_Powertrain (CM_NM_DispKBI_FS_FCIB_Cx10000000000_41_Diagnosis_Powertrain), 8192=Cx2000_14_InfotainmentExtensions (CM_NM_DispKBI_FS_FCIB_Cx2000_14_InfotainmentExtensions), 1=Cx1_01_CarWakeUp (CM_NM_DispKBI_FS_FCIB_Cx1_01_CarWakeUp), 4294967296=Cx100000000_33_ExternalWirelessCommunication (CM_NM_DispKBI_FS_FCIB_Cx100000000_33_ExternalWirelessCommunication), 68719476736=Cx1000000000_37_HighVoltage_WirelessChargingStation (CM_NM_DispKBI_FS_FCIB_Cx1000000000_37_HighVoltage_WirelessChargingStation), 524288=Cx80000_20_OptionalComfort (CM_NM_DispKBI_FS_FCIB_Cx80000_20_OptionalComfort), 32768=Cx8000_16_InfotainmentDisplay (CM_NM_DispKBI_FS_FCIB_Cx8000_16_InfotainmentDisplay), 4096=Cx1000_13_Airbag (CM_NM_DispKBI_FS_FCIB_Cx1000_13_Airbag), 256=Cx100_09_reserved (CM_NM_DispKBI_FS_FCIB_Cx100_09_reserved) (09_<reserved>), 4194304=Cx400000_23_Climate (CM_NM_DispKBI_FS_FCIB_Cx400000_23_Climate), 34359738368=Cx800000000_36_Preheater (CM_NM_DispKBI_FS_FCIB_Cx800000000_36_Preheater), 128=Cx80_08_Basefunction_Connectivity (CM_NM_DispKBI_FS_FCIB_Cx80_08_Basefunction_Connectivity), 8=Cx8_04_Basefunction_DrivingAssistance (CM_NM_DispKBI_FS_FCIB_Cx8_04_Basefunction_DrivingAssistance), 16384=Cx4000_15_InstrumentclusterDisplay (CM_NM_DispKBI_FS_FCIB_Cx4000_15_InstrumentclusterDisplay), 281474976710656=Cx1000000000000_49_reserved (CM_NM_DispKBI_FS_FCIB_Cx1000000000000_49_reserved) (49_<reserved>), 4398046511104=Cx40000000000_43_Diagnosis_DrivingAssistance (CM_NM_DispKBI_FS_FCIB_Cx40000000000_43_Diagnosis_DrivingAssistance), 9007199254740992=Cx20000000000000_54_reserved (CM_NM_DispKBI_FS_FCIB_Cx20000000000000_54_reserved) (54_<reserved>), 8589934592=Cx200000000_34_GPS_Localization (CM_NM_DispKBI_FS_FCIB_Cx200000000_34_GPS_Localization), 1024=Cx400_11_Chassis (CM_NM_DispKBI_FS_FCIB_Cx400_11_Chassis), 16=Cx10_05_Basefunction_Infotainment (CM_NM_DispKBI_FS_FCIB_Cx10_05_Basefunction_Infotainment), 35184372088832=Cx200000000000_46_Diagnosis_Light (CM_NM_DispKBI_FS_FCIB_Cx200000000000_46_Diagnosis_Light)}, range raw 1..36028797018963968, transfer-property=PENDING, to HCP3_IONode(timeout 5 s)  # FCIB = Funktions-Cluster-Initialisierungs-Bits
      frame KN_HUD_XIX_HCP3_CANFD01: id 0x17F0001B, to HCP3_IONode, frame-length=16, can-addressing-mode=EXTENDED, can-frame-rx-behavior=CAN-FD, can-frame-tx-behavior=CAN-FD
        pdu KN_HUD_XIX_HCP3_CANFD01: length=16, transmission-mode-true-timing=cyclic-timing={time-offset=0.0, time-period=0.5}, unused-bit-pattern=0
          signal HUD_KompSchutz_XIX_KN_HUD_XIX_HCP3_CANFD01: start 0, 1 bit, little-endian, data-type-policy=OVERRIDE, i-signal-type=PRIMITIVE, init-value=0, base-type=BT_HUD_KompSchutz, compu {0=Cx0_inaktiv (CM_HUD_KompSchutz_Cx0_inaktiv), 1=Cx1_aktiv (CM_HUD_KompSchutz_Cx1_aktiv)}, range raw 0..1, transfer-property=PENDING  # Funktionseinschränkung aufgrund Komponentenschutz aktiv
          signal HUD_Abschaltstufe_XIX_KN_HUD_XIX_HCP3_CANFD01: start 1, 1 bit, little-endian, data-type-policy=OVERRIDE, i-signal-type=PRIMITIVE, init-value=0, base-type=BT_HUD_Abschaltstufe, compu {0=Cx0_keine_Einschraenkung (CM_HUD_Abschaltstufe_Cx0_keine_Einschraenkung), 1=Cx1_Funktionseinschraenkung (CM_HUD_Abschaltstufe_Cx1_Funktionseinschraenkung)}, range raw 0..1, transfer-property=PENDING  # Funktionseinschränkung aufgrund aktiver Abschaltstufe
          signal HUD_Transport_Mode_XIX_KN_HUD_XIX_HCP3_CANFD01: start 2, 1 bit, little-endian, data-type-policy=OVERRIDE, i-signal-type=PRIMITIVE, init-value=0, base-type=BT_HUD_Transport_Mode, compu {1=Cx1_Funktionseinschraenkung (CM_HUD_Transport_Mode_Cx1_Funktionseinschraenkung), 0=Cx0_keine_Einschraenkung (CM_HUD_Transport_Mode_Cx0_keine_Einschraenkung)}, range raw 0..1, transfer-property=PENDING  # Funktionseinschränkung aufgrund aktivem Transport Mode und/oder Transport Schutz
          signal HUD_Nachlauftyp_XIX_KN_HUD_XIX_HCP3_CANFD01: start 4, 4 bit, little-endian, data-type-policy=OVERRIDE, i-signal-type=PRIMITIVE, init-value=2, base-type=BT_HUD_Nachlauftyp, compu {1=Cx1_Komm_nach_KL15_AUS (CM_HUD_Nachlauftyp_Cx1_Komm_nach_KL15_AUS), 2=Cx2_Komm_bei_KL15_AUS (CM_HUD_Nachlauftyp_Cx2_Komm_bei_KL15_AUS), 0=Cx0_Komm_bei_KL15_EIN (CM_HUD_Nachlauftyp_Cx0_Komm_bei_KL15_EIN)}, range raw 0..2, transfer-property=PENDING, to HCP3_IONode(timeout 5 s)  # Abgebildet wird die von der Hardware vorgegebene Möglichkeit, die Kommunikation nach Klemme 15 = AUS aufrecht zu erhalten. Es wird ein Init-Wert gesendet.
          signal HUD_SNI_10_XIX_KN_HUD_XIX_HCP3_CANFD01: start 8, 10 bit, little-endian, data-type-policy=OVERRIDE, i-signal-type=PRIMITIVE, init-value=27, base-type=BT_HUD_SNI_10, compu {phys=raw for raw 0..1023}, range phys 0..1023, raw 0..1023, transfer-property=PENDING, to HCP3_IONode(timeout 5 s)  # Source Node-Identifier (SNI) identifiziert den Sender der NM-Botschaft (Knotenadresse) eindeutig im Fahrzeug
          signal KN_HUD_ECUKnockOut_XIX_KN_HUD_XIX_HCP3_CANFD01: start 18, 2 bit, little-endian, data-type-policy=OVERRIDE, i-signal-type=PRIMITIVE, init-value=0, base-type=BT_KN_HUD_ECUKnockOut, compu {0=Cx0_Funktion_nicht_ausgeloest (CM_KN_HUD_ECUKnockOut_Cx0_Funktion_nicht_ausgeloest), 2=Cx2_Funktion_ausgeloest (CM_KN_HUD_ECUKnockOut_Cx2_Funktion_ausgeloest), 3=Cx3_Funktion_deaktiviert (CM_KN_HUD_ECUKnockOut_Cx3_Funktion_deaktiviert), 1=Cx1_Veto_war_aktiv (CM_KN_HUD_ECUKnockOut_Cx1_Veto_war_aktiv)}, range raw 0..3, transfer-property=PENDING  # Ausgabe des ECUKnockout-Status
          signal KN_HUD_DiagPfad_V12_XIX_KN_HUD_XIX_HCP3_CANFD01: start 20, 1 bit, little-endian, data-type-policy=OVERRIDE, i-signal-type=PRIMITIVE, init-value=0, base-type=BT_KN_HUD_DiagPfad_V12, compu {1=Cx1_inaktiv (CM_KN_HUD_DiagPfad_V12_Cx1_inaktiv), 0=Cx0_Aktiv (CM_KN_HUD_DiagPfad_V12_Cx0_Aktiv)}, range raw 0..1, transfer-property=PENDING, to HCP3_IONode(timeout 5 s)  # Kennzeichnung der Diagnosefaehigkeit des BusInterfaces eines Steuergeraetes (Knoten) Umfang LAH 80127 Bei Nutzung des Signal explizit pro angebundenem BusInterface zu setzen
          signal NM_HUD_Lokalaktiv_XIX_KN_HUD_XIX_HCP3_CANFD01: start 21, 1 bit, little-endian, data-type-policy=OVERRIDE, i-signal-type=PRIMITIVE, init-value=0, base-type=BT_NM_HUD_Lokalaktiv, compu {0=Cx0_war_nicht_lokal_aktiv (CM_NM_HUD_Lokalaktiv_Cx0_war_nicht_lokal_aktiv), 1=Cx1_war_lokal_aktiv (CM_NM_HUD_Lokalaktiv_Cx1_war_lokal_aktiv)}, range raw 0..1, transfer-property=PENDING  # Zeigt an ob das SG nach Klemme15 AUS und nach entsprechender MAX Aktivzeit noch aktiv war.
          signal NM_HUD_Subsystemaktiv_XIX_KN_HUD_XIX_HCP3_CANFD01: start 22, 1 bit, little-endian, data-type-policy=OVERRIDE, i-signal-type=PRIMITIVE, init-value=0, base-type=BT_NM_HUD_Subsystemaktiv, compu {0=Cx0_war_nicht_lokal_aktiv (CM_NM_HUD_Subsystemaktiv_Cx0_war_nicht_lokal_aktiv), 1=Cx1_war_lokal_aktiv (CM_NM_HUD_Subsystemaktiv_Cx1_war_lokal_aktiv)}, range raw 0..1, transfer-property=PENDING  # Zeigt an ob ein Subsystem des SGs nach Klemme15 AUS und nach entsprechender MAX Aktivzeit noch aktiv war
          signal HUD_KD_Fehler_XIX_KN_HUD_XIX_HCP3_CANFD01: start 23, 1 bit, little-endian, data-type-policy=OVERRIDE, i-signal-type=PRIMITIVE, init-value=0, base-type=BT_HUD_KD_Fehler, compu {0=Cx0_Kein_KD_Fehler (CM_HUD_KD_Fehler_Cx0_Kein_KD_Fehler), 1=Cx1_KD_Fehler (CM_HUD_KD_Fehler_Cx1_KD_Fehler)}, range raw 0..1, transfer-property=PENDING, to HCP3_IONode(timeout 2.5 s)  # Bei gesetztem Bit ist mindestens ein Kundendienstfehler eingetragen
          signal KN_HUD_ECUKnockOutTimer_XIX_KN_HUD_XIX_HCP3_CANFD01: start 24, 6 bit, little-endian, data-type-policy=OVERRIDE, i-signal-type=PRIMITIVE, init-value=15, base-type=BT_KN_HUD_ECUKnockOutTimer, compu {phys=raw for raw 0..62, 63=Cx3f_ECUKnockOut_deaktiviert (CM_KN_HUD_ECUKnockOutTimer_Cx3f_ECUKnockOut_deaktiviert); unit Unit_Minut}, range phys 0..62 Unit_Minut, raw 0..63, unit=Unit_Minut, transfer-property=PENDING  # Ausgabe des ECUKnockOut-Timer
          signal KN_HUD_BusKnockOut_XIX_KN_HUD_XIX_HCP3_CANFD01: start 30, 2 bit, little-endian, data-type-policy=OVERRIDE, i-signal-type=PRIMITIVE, init-value=0, base-type=BT_KN_HUD_BusKnockOut, compu {3=Cx3_Funktion_deaktiviert (CM_KN_HUD_BusKnockOut_Cx3_Funktion_deaktiviert), 2=Cx2_Funktion_ausgeloest (CM_KN_HUD_BusKnockOut_Cx2_Funktion_ausgeloest), 0=Cx0_Funktion_nicht_ausgeloest (CM_KN_HUD_BusKnockOut_Cx0_Funktion_nicht_ausgeloest), 1=Cx1_Veto_aktiv (CM_KN_HUD_BusKnockOut_Cx1_Veto_aktiv)}, range raw 0..3, transfer-property=PENDING  # Ausgabe des BusKnockout-Status
          signal KN_HUD_BusKnockOutTimer_XIX_KN_HUD_XIX_HCP3_CANFD01: start 32, 8 bit, little-endian, data-type-policy=OVERRIDE, i-signal-type=PRIMITIVE, init-value=15, base-type=BT_KN_HUD_BusKnockOutTimer, compu {phys=raw for raw 0..254, 255=Cxff_BusKnockOut_deaktiviert (CM_KN_HUD_BusKnockOutTimer_Cxff_BusKnockOut_deaktiviert); unit Unit_Minut}, range phys 0..254 Unit_Minut, raw 0..255, unit=Unit_Minut, transfer-property=PENDING  # Ausgabe des BusKnockOut-Timer
          signal NM_HUD_FCIB_XIX_KN_HUD_XIX_HCP3_CANFD01: start 40, 56 bit, opaque, data-type-policy=OVERRIDE, i-signal-type=ARRAY, init-value=[1, 128, 0, 0, 0, 8, 0], base-type=BT_NM_HUD_FCIB, compu {1048576=Cx100000_21_AirSuspension (CM_NM_HUD_FCIB_Cx100000_21_AirSuspension), 16777216=Cx1000000_25_AccessSystemSensors (CM_NM_HUD_FCIB_Cx1000000_25_AccessSystemSensors), 140737488355328=Cx800000000000_48_Diagnosis_ClimateTmeLINs (CM_NM_HUD_FCIB_Cx800000000000_48_Diagnosis_ClimateTmeLINs), 18014398509481984=Cx40000000000000_55_Dimming (CM_NM_HUD_FCIB_Cx40000000000000_55_Dimming), 512=Cx200_10_Powertrain (CM_NM_HUD_FCIB_Cx200_10_Powertrain), 65536=Cx10000_17_Audio (CM_NM_HUD_FCIB_Cx10000_17_Audio), 536870912=Cx20000000_30_EnergyManagement (CM_NM_HUD_FCIB_Cx20000000_30_EnergyManagement), 1099511627776=Cx10000000000_41_Diagnosis_Powertrain (CM_NM_HUD_FCIB_Cx10000000000_41_Diagnosis_Powertrain), 8796093022208=Cx80000000000_44_Diagnosis_Infotainment (CM_NM_HUD_FCIB_Cx80000000000_44_Diagnosis_Infotainment), 4=Cx4_03_Basefunction_Chassis (CM_NM_HUD_FCIB_Cx4_03_Basefunction_Chassis), 131072=Cx20000_18_VirtualSideMirrors (CM_NM_HUD_FCIB_Cx20000_18_VirtualSideMirrors), 281474976710656=Cx1000000000000_49_reserved (CM_NM_HUD_FCIB_Cx1000000000000_49_reserved) (49_<reserved>), 17179869184=Cx400000000_35_ExteriorSound (CM_NM_HUD_FCIB_Cx400000000_35_ExteriorSound), 34359738368=Cx800000000_36_Preheater (CM_NM_HUD_FCIB_Cx800000000_36_Preheater), 35184372088832=Cx200000000000_46_Diagnosis_Light (CM_NM_HUD_FCIB_Cx200000000000_46_Diagnosis_Light), 32=Cx20_06_Basefunction_ComfortLight (CM_NM_HUD_FCIB_Cx20_06_Basefunction_ComfortLight), 8589934592=Cx200000000_34_GPS_Localization (CM_NM_HUD_FCIB_Cx200000000_34_GPS_Localization), 8192=Cx2000_14_InfotainmentExtensions (CM_NM_HUD_FCIB_Cx2000_14_InfotainmentExtensions), 32768=Cx8000_16_InfotainmentDisplay (CM_NM_HUD_FCIB_Cx8000_16_InfotainmentDisplay), 128=Cx80_08_Basefunction_Connectivity (CM_NM_HUD_FCIB_Cx80_08_Basefunction_Connectivity), 36028797018963968=Cx80000000000000_56_ChargingStatus (CM_NM_HUD_FCIB_Cx80000000000000_56_ChargingStatus), 8=Cx8_04_Basefunction_DrivingAssistance (CM_NM_HUD_FCIB_Cx8_04_Basefunction_DrivingAssistance), 1073741824=Cx40000000_31_MultifunctionalSteeringWheel (CM_NM_HUD_FCIB_Cx40000000_31_MultifunctionalSteeringWheel), 16=Cx10_05_Basefunction_Infotainment (CM_NM_HUD_FCIB_Cx10_05_Basefunction_Infotainment), 4096=Cx1000_13_Airbag (CM_NM_HUD_FCIB_Cx1000_13_Airbag), 134217728=Cx8000000_28_OnboardTester_DataCollector (CM_NM_HUD_FCIB_Cx8000000_28_OnboardTester_DataCollector), 4398046511104=Cx40000000000_43_Diagnosis_DrivingAssistance (CM_NM_HUD_FCIB_Cx40000000000_43_Diagnosis_DrivingAssistance), 4194304=Cx400000_23_Climate (CM_NM_HUD_FCIB_Cx400000_23_Climate), 33554432=Cx2000000_26_HighVoltage_Charging (CM_NM_HUD_FCIB_Cx2000000_26_HighVoltage_Charging), 2=Cx2_02_Basefunction_Powertrain (CM_NM_HUD_FCIB_Cx2_02_Basefunction_Powertrain), 524288=Cx80000_20_OptionalComfort (CM_NM_HUD_FCIB_Cx80000_20_OptionalComfort), 70368744177664=Cx400000000000_47_Diagnosis_ComfortLINs (CM_NM_HUD_FCIB_Cx400000000000_47_Diagnosis_ComfortLINs), 4503599627370496=Cx10000000000000_53_Lock_Unlock (CM_NM_HUD_FCIB_Cx10000000000000_53_Lock_Unlock), 2147483648=Cx80000000_32_OnlineAccess (CM_NM_HUD_FCIB_Cx80000000_32_OnlineAccess), 4294967296=Cx100000000_33_ExternalWirelessCommunication (CM_NM_HUD_FCIB_Cx100000000_33_ExternalWirelessCommunication), 16384=Cx4000_15_InstrumentclusterDisplay (CM_NM_HUD_FCIB_Cx4000_15_InstrumentclusterDisplay), 64=Cx40_07_Basefunction_CrossSection (CM_NM_HUD_FCIB_Cx40_07_Basefunction_CrossSection), 8388608=Cx800000_24_ThermoManagement (CM_NM_HUD_FCIB_Cx800000_24_ThermoManagement), 8796093054977=Cx80000008001_InitValueFCIB (CM_NM_HUD_FCIB_Cx80000008001_InitValueFCIB), 549755813888=Cx8000000000_40_Diagnosis_Energy (CM_NM_HUD_FCIB_Cx8000000000_40_Diagnosis_Energy), 2097152=Cx200000_22_ExteriorLights (CM_NM_HUD_FCIB_Cx200000_22_ExteriorLights), 262144=Cx40000_19_Doors_Hatches (CM_NM_HUD_FCIB_Cx40000_19_Doors_Hatches), 256=Cx100_09_reserved (CM_NM_HUD_FCIB_Cx100_09_reserved) (09_<reserved>), 68719476736=Cx1000000000_37_HighVoltage_WirelessChargingStation (CM_NM_HUD_FCIB_Cx1000000000_37_HighVoltage_WirelessChargingStation), 1024=Cx400_11_Chassis (CM_NM_HUD_FCIB_Cx400_11_Chassis), 2199023255552=Cx20000000000_42_Diagnosis_FlexRay (CM_NM_HUD_FCIB_Cx20000000000_42_Diagnosis_FlexRay), 1=Cx1_01_CarWakeUp (CM_NM_HUD_FCIB_Cx1_01_CarWakeUp), 2048=Cx800_12_GearSelector (CM_NM_HUD_FCIB_Cx800_12_GearSelector), 67108864=Cx4000000_27_Timemaster_Timer (CM_NM_HUD_FCIB_Cx4000000_27_Timemaster_Timer), 9007199254740992=Cx20000000000000_54_reserved (CM_NM_HUD_FCIB_Cx20000000000000_54_reserved) (54_<reserved>), 17592186044416=Cx100000000000_45_Diagnosis_Comfort (CM_NM_HUD_FCIB_Cx100000000000_45_Diagnosis_Comfort), 268435456=Cx10000000_29_SteeringColumnLock (CM_NM_HUD_FCIB_Cx10000000_29_SteeringColumnLock)}, range raw 1..36028797018963968, transfer-property=PENDING, to HCP3_IONode(timeout 5 s)  # FCIB = Funktions-Cluster-Initialisierungs-Bits
      frame KN_Info_El_XIX_HCP3_CANFD01: id 0x17F00073, from HCP3_IONode, frame-length=16, can-addressing-mode=EXTENDED, can-frame-rx-behavior=CAN-FD, can-frame-tx-behavior=CAN-FD
        pdu KN_Info_El_XIX_HCP3_CANFD01: length=16, transmission-mode-true-timing=cyclic-timing={time-offset=0.0, time-period=0.5}, unused-bit-pattern=0
          signal Info_El_Nachlauftyp_XIX_KN_Info_El_XIX_HCP3_CANFD01: start 4, 4 bit, little-endian, data-type-policy=OVERRIDE, i-signal-type=PRIMITIVE, init-value=2, base-type=BT_Info_El_Nachlauftyp, compu {0=Cx0_Komm_bei_KL15_EIN (CM_Info_El_Nachlauftyp_Cx0_Komm_bei_KL15_EIN), 2=Cx2_Komm_bei_KL15_AUS (CM_Info_El_Nachlauftyp_Cx2_Komm_bei_KL15_AUS), 1=Cx1_Komm_nach_KL15_AUS (CM_Info_El_Nachlauftyp_Cx1_Komm_nach_KL15_AUS)}, range raw 0..2, transfer-property=PENDING  # Abgebildet wird die von der Hardware vorgegebene Möglichkeit, die Kommunikation nach Klemme 15 = AUS aufrecht zu erhalten. Es wird ein Init-Wert gesendet.
          signal Info_El_SNI_10_XIX_KN_Info_El_XIX_HCP3_CANFD01: start 8, 10 bit, little-endian, data-type-policy=OVERRIDE, i-signal-type=PRIMITIVE, init-value=115, base-type=BT_Info_El_SNI_10, compu {phys=raw for raw 0..1023}, range phys 0..1023, raw 0..1023, transfer-property=PENDING  # Source Node-Identifier (SNI) identifiziert den Sender der NM-Botschaft (Knotenadresse) eindeutig im Fahrzeug
          signal KN_Info_El_ECUKnockOut_XIX_KN_Info_El_XIX_HCP3_CANFD01: start 18, 2 bit, little-endian, data-type-policy=OVERRIDE, i-signal-type=PRIMITIVE, init-value=0, base-type=BT_KN_Info_El_ECUKnockOut, compu {2=Cx2_Funktion_ausgeloest (CM_KN_Info_El_ECUKnockOut_Cx2_Funktion_ausgeloest), 1=Cx1_Veto_war_aktiv (CM_KN_Info_El_ECUKnockOut_Cx1_Veto_war_aktiv), 0=Cx0_Funktion_nicht_ausgeloest (CM_KN_Info_El_ECUKnockOut_Cx0_Funktion_nicht_ausgeloest), 3=Cx3_Funktion_deaktiviert (CM_KN_Info_El_ECUKnockOut_Cx3_Funktion_deaktiviert)}, range raw 0..3, transfer-property=PENDING  # Ausgabe des ECUKnockout-Status
          signal KN_Info_El_DiagPfad_V12_XIX_KN_Info_El_XIX_HCP3_CANFD01: start 20, 1 bit, little-endian, data-type-policy=OVERRIDE, i-signal-type=PRIMITIVE, base-type=BT_KN_Info_El_DiagPfad_V12, compu {0=Cx0_Aktiv (CM_KN_Info_El_DiagPfad_V12_Cx0_Aktiv), 1=Cx1_inaktiv (CM_KN_Info_El_DiagPfad_V12_Cx1_inaktiv)}, range raw 0..1, transfer-property=PENDING  # Kennzeichnung der Diagnosefaehigkeit des BusInterfaces eines Steuergeraetes (Knoten) Umfang LAH 80127 Bei Nutzung des Signal explizit pro angebundenem BusInterface zu setzen
          signal Info_El_KD_Fehler_XIX_KN_Info_El_XIX_HCP3_CANFD01: start 23, 1 bit, little-endian, data-type-policy=OVERRIDE, i-signal-type=PRIMITIVE, init-value=0, base-type=BT_Info_El_KD_Fehler, compu {0=Cx0_Kein_KD_Fehler (CM_Info_El_KD_Fehler_Cx0_Kein_KD_Fehler), 1=Cx1_KD_Fehler (CM_Info_El_KD_Fehler_Cx1_KD_Fehler)}, range raw 0..1, transfer-property=PENDING  # Bei gesetztem Bit ist mindestens ein Kundendienstfehler eingetragen
          signal KN_Info_El_ECUKnockOutTimer_XIX_KN_Info_El_XIX_HCP3_CANFD01: start 24, 6 bit, little-endian, data-type-policy=OVERRIDE, i-signal-type=PRIMITIVE, init-value=15, base-type=BT_KN_Info_El_ECUKnockOutTimer, compu {phys=raw for raw 0..62, 63=Cx3f_ECUKnockOut_deaktiviert (CM_KN_Info_El_ECUKnockOutTimer_Cx3f_ECUKnockOut_deaktiviert); unit Unit_Minut}, range phys 0..62 Unit_Minut, raw 0..63, unit=Unit_Minut, transfer-property=PENDING  # Ausgabe des ECUKnockOut-Timer
          signal KN_Info_El_BusKnockOut_XIX_KN_Info_El_XIX_HCP3_CANFD01: start 30, 2 bit, little-endian, data-type-policy=OVERRIDE, i-signal-type=PRIMITIVE, init-value=0, base-type=BT_KN_Info_El_BusKnockOut, compu {0=Cx0_Funktion_nicht_ausgeloest (CM_KN_Info_El_BusKnockOut_Cx0_Funktion_nicht_ausgeloest), 2=Cx2_Funktion_ausgeloest (CM_KN_Info_El_BusKnockOut_Cx2_Funktion_ausgeloest), 1=Cx1_Veto_aktiv (CM_KN_Info_El_BusKnockOut_Cx1_Veto_aktiv), 3=Cx3_Funktion_deaktiviert (CM_KN_Info_El_BusKnockOut_Cx3_Funktion_deaktiviert)}, range raw 0..3, transfer-property=PENDING  # Ausgabe des BusKnockout-Status
          signal KN_Info_El_BusKnockOutTimer_XIX_KN_Info_El_XIX_HCP3_CANFD01: start 32, 8 bit, little-endian, data-type-policy=OVERRIDE, i-signal-type=PRIMITIVE, init-value=15, base-type=BT_KN_Info_El_BusKnockOutTimer, compu {phys=raw for raw 0..254, 255=Cxff_BusKnockOut_deaktiviert (CM_KN_Info_El_BusKnockOutTimer_Cxff_BusKnockOut_deaktiviert); unit Unit_Minut}, range phys 0..254 Unit_Minut, raw 0..255, unit=Unit_Minut, transfer-property=PENDING  # Ausgabe des BusKnockOut-Timer
          signal NM_Info_El_FCIB_XIX_KN_Info_El_XIX_HCP3_CANFD01: start 40, 56 bit, opaque, data-type-policy=OVERRIDE, i-signal-type=ARRAY, init-value=[17, 0, 0, 0, 0, 0, 0], base-type=BT_NM_Info_El_FCIB, compu {256=Cx100_09_reserved (CM_NM_Info_El_FCIB_Cx100_09_reserved) (09_<reserved>), 16=Cx10_05_Basefunction_Infotainment (CM_NM_Info_El_FCIB_Cx10_05_Basefunction_Infotainment), 4503599627370496=Cx10000000000000_53_Lock_Unlock (CM_NM_Info_El_FCIB_Cx10000000000000_53_Lock_Unlock), 17=Cx11_InitValueFCIB (CM_NM_Info_El_FCIB_Cx11_InitValueFCIB), 536870912=Cx20000000_30_EnergyManagement (CM_NM_Info_El_FCIB_Cx20000000_30_EnergyManagement), 16777216=Cx1000000_25_AccessSystemSensors (CM_NM_Info_El_FCIB_Cx1000000_25_AccessSystemSensors), 1=Cx1_01_CarWakeUp (CM_NM_Info_El_FCIB_Cx1_01_CarWakeUp), 2199023255552=Cx20000000000_42_Diagnosis_FlexRay (CM_NM_Info_El_FCIB_Cx20000000000_42_Diagnosis_FlexRay), 34359738368=Cx800000000_36_Preheater (CM_NM_Info_El_FCIB_Cx800000000_36_Preheater), 268435456=Cx10000000_29_SteeringColumnLock (CM_NM_Info_El_FCIB_Cx10000000_29_SteeringColumnLock), 2048=Cx800_12_GearSelector (CM_NM_Info_El_FCIB_Cx800_12_GearSelector), 128=Cx80_08_Basefunction_Connectivity (CM_NM_Info_El_FCIB_Cx80_08_Basefunction_Connectivity), 4=Cx4_03_Basefunction_Chassis (CM_NM_Info_El_FCIB_Cx4_03_Basefunction_Chassis), 1048576=Cx100000_21_AirSuspension (CM_NM_Info_El_FCIB_Cx100000_21_AirSuspension), 16384=Cx4000_15_InstrumentclusterDisplay (CM_NM_Info_El_FCIB_Cx4000_15_InstrumentclusterDisplay), 2=Cx2_02_Basefunction_Powertrain (CM_NM_Info_El_FCIB_Cx2_02_Basefunction_Powertrain), 134217728=Cx8000000_28_OnboardTester_DataCollector (CM_NM_Info_El_FCIB_Cx8000000_28_OnboardTester_DataCollector), 17179869184=Cx400000000_35_ExteriorSound (CM_NM_Info_El_FCIB_Cx400000000_35_ExteriorSound), 70368744177664=Cx400000000000_47_Diagnosis_ComfortLINs (CM_NM_Info_El_FCIB_Cx400000000000_47_Diagnosis_ComfortLINs), 4194304=Cx400000_23_Climate (CM_NM_Info_El_FCIB_Cx400000_23_Climate), 281474976710656=Cx1000000000000_49_reserved (CM_NM_Info_El_FCIB_Cx1000000000000_49_reserved) (49_<reserved>), 4096=Cx1000_13_Airbag (CM_NM_Info_El_FCIB_Cx1000_13_Airbag), 140737488355328=Cx800000000000_48_Diagnosis_ClimateTmeLINs (CM_NM_Info_El_FCIB_Cx800000000000_48_Diagnosis_ClimateTmeLINs), 36028797018963968=Cx80000000000000_56_ChargingStatus (CM_NM_Info_El_FCIB_Cx80000000000000_56_ChargingStatus), 2147483648=Cx80000000_32_OnlineAccess (CM_NM_Info_El_FCIB_Cx80000000_32_OnlineAccess), 4398046511104=Cx40000000000_43_Diagnosis_DrivingAssistance (CM_NM_Info_El_FCIB_Cx40000000000_43_Diagnosis_DrivingAssistance), 65536=Cx10000_17_Audio (CM_NM_Info_El_FCIB_Cx10000_17_Audio), 17592186044416=Cx100000000000_45_Diagnosis_Comfort (CM_NM_Info_El_FCIB_Cx100000000000_45_Diagnosis_Comfort), 33554432=Cx2000000_26_HighVoltage_Charging (CM_NM_Info_El_FCIB_Cx2000000_26_HighVoltage_Charging), 549755813888=Cx8000000000_40_Diagnosis_Energy (CM_NM_Info_El_FCIB_Cx8000000000_40_Diagnosis_Energy), 4294967296=Cx100000000_33_ExternalWirelessCommunication (CM_NM_Info_El_FCIB_Cx100000000_33_ExternalWirelessCommunication), 262144=Cx40000_19_Doors_Hatches (CM_NM_Info_El_FCIB_Cx40000_19_Doors_Hatches), 9007199254740992=Cx20000000000000_54_reserved (CM_NM_Info_El_FCIB_Cx20000000000000_54_reserved) (54_<reserved>), 18014398509481984=Cx40000000000000_55_Dimming (CM_NM_Info_El_FCIB_Cx40000000000000_55_Dimming), 32768=Cx8000_16_InfotainmentDisplay (CM_NM_Info_El_FCIB_Cx8000_16_InfotainmentDisplay), 524288=Cx80000_20_OptionalComfort (CM_NM_Info_El_FCIB_Cx80000_20_OptionalComfort), 1073741824=Cx40000000_31_MultifunctionalSteeringWheel (CM_NM_Info_El_FCIB_Cx40000000_31_MultifunctionalSteeringWheel), 512=Cx200_10_Powertrain (CM_NM_Info_El_FCIB_Cx200_10_Powertrain), 1024=Cx400_11_Chassis (CM_NM_Info_El_FCIB_Cx400_11_Chassis), 8388608=Cx800000_24_ThermoManagement (CM_NM_Info_El_FCIB_Cx800000_24_ThermoManagement), 32=Cx20_06_Basefunction_ComfortLight (CM_NM_Info_El_FCIB_Cx20_06_Basefunction_ComfortLight), 35184372088832=Cx200000000000_46_Diagnosis_Light (CM_NM_Info_El_FCIB_Cx200000000000_46_Diagnosis_Light), 8589934592=Cx200000000_34_GPS_Localization (CM_NM_Info_El_FCIB_Cx200000000_34_GPS_Localization), 8=Cx8_04_Basefunction_DrivingAssistance (CM_NM_Info_El_FCIB_Cx8_04_Basefunction_DrivingAssistance), 8192=Cx2000_14_InfotainmentExtensions (CM_NM_Info_El_FCIB_Cx2000_14_InfotainmentExtensions), 68719476736=Cx1000000000_37_HighVoltage_WirelessChargingStation (CM_NM_Info_El_FCIB_Cx1000000000_37_HighVoltage_WirelessChargingStation), 67108864=Cx4000000_27_Timemaster_Timer (CM_NM_Info_El_FCIB_Cx4000000_27_Timemaster_Timer), 64=Cx40_07_Basefunction_CrossSection (CM_NM_Info_El_FCIB_Cx40_07_Basefunction_CrossSection), 8796093022208=Cx80000000000_44_Diagnosis_Infotainment (CM_NM_Info_El_FCIB_Cx80000000000_44_Diagnosis_Infotainment), 131072=Cx20000_18_VirtualSideMirrors (CM_NM_Info_El_FCIB_Cx20000_18_VirtualSideMirrors), 2097152=Cx200000_22_ExteriorLights (CM_NM_Info_El_FCIB_Cx200000_22_ExteriorLights), 1099511627776=Cx10000000000_41_Diagnosis_Powertrain (CM_NM_Info_El_FCIB_Cx10000000000_41_Diagnosis_Powertrain)}, range raw 1..36028797018963968, transfer-property=PENDING  # FCIB = Funktions-Cluster-Initialisierungs-Bits
      frame KN_PID_XIX_HCP3_CANFD01: id 0x17F00123, to HCP3_IONode, frame-length=16, can-addressing-mode=EXTENDED, can-frame-rx-behavior=CAN-FD, can-frame-tx-behavior=CAN-FD
        pdu KN_PID_XIX_HCP3_CANFD01: length=16, transmission-mode-true-timing=cyclic-timing={time-offset=0.0, time-period=0.5}, unused-bit-pattern=0
          signal PID_Nachlauftyp_XIX_KN_PID_XIX_HCP3_CANFD01: start 4, 4 bit, little-endian, data-type-policy=OVERRIDE, i-signal-type=PRIMITIVE, init-value=2, base-type=BT_PID_Nachlauftyp, compu {1=Cx1_Komm_nach_KL15_AUS (CM_PID_Nachlauftyp_Cx1_Komm_nach_KL15_AUS), 2=Cx2_Komm_bei_KL15_AUS (CM_PID_Nachlauftyp_Cx2_Komm_bei_KL15_AUS), 0=Cx0_Komm_bei_KL15_EIN (CM_PID_Nachlauftyp_Cx0_Komm_bei_KL15_EIN)}, range raw 0..2, transfer-property=PENDING, to HCP3_IONode(timeout 5 s)  # Abgebildet wird die von der Hardware vorgegebene Möglichkeit, die Kommunikation nach Klemme 15 = AUS aufrecht zu erhalten. Es wird ein Init-Wert gesendet.
          signal PID_SNI_10_XIX_KN_PID_XIX_HCP3_CANFD01: start 8, 10 bit, little-endian, data-type-policy=OVERRIDE, i-signal-type=PRIMITIVE, init-value=291, base-type=BT_PID_SNI_10, compu {phys=raw for raw 0..1023}, range phys 0..1023, raw 0..1023, transfer-property=PENDING, to HCP3_IONode(timeout 5 s)  # Source Node-Identifier (SNI) identifiziert den Sender der NM-Botschaft (Knotenadresse) eindeutig im Fahrzeug
          signal KN_PID_ECUKnockOut_XIX_KN_PID_XIX_HCP3_CANFD01: start 18, 2 bit, little-endian, data-type-policy=OVERRIDE, i-signal-type=PRIMITIVE, init-value=0, base-type=BT_KN_PID_ECUKnockOut, compu {2=Cx2_Funktion_ausgeloest (CM_KN_PID_ECUKnockOut_Cx2_Funktion_ausgeloest), 1=Cx1_Veto_war_aktiv (CM_KN_PID_ECUKnockOut_Cx1_Veto_war_aktiv), 0=Cx0_Funktion_nicht_ausgeloest (CM_KN_PID_ECUKnockOut_Cx0_Funktion_nicht_ausgeloest), 3=Cx3_Funktion_deaktiviert (CM_KN_PID_ECUKnockOut_Cx3_Funktion_deaktiviert)}, range raw 0..3, transfer-property=PENDING  # Ausgabe des ECUKnockout-Status
          signal KN_PID_DiagPfad_V12_XIX_KN_PID_XIX_HCP3_CANFD01: start 20, 1 bit, little-endian, data-type-policy=OVERRIDE, i-signal-type=PRIMITIVE, init-value=0, base-type=BT_KN_PID_DiagPfad_V12, compu {0=Cx0_Aktiv (CM_KN_PID_DiagPfad_V12_Cx0_Aktiv), 1=Cx1_inaktiv (CM_KN_PID_DiagPfad_V12_Cx1_inaktiv)}, range raw 0..1, transfer-property=PENDING, to HCP3_IONode(timeout 5 s)  # Kennzeichnung der Diagnosefaehigkeit des BusInterfaces eines Steuergeraetes (Knoten) Umfang LAH 80127 Bei Nutzung des Signal explizit pro angebundenem BusInterface zu setzen
          signal NM_PID_Lokalaktiv_XIX_KN_PID_XIX_HCP3_CANFD01: start 21, 1 bit, little-endian, data-type-policy=OVERRIDE, i-signal-type=PRIMITIVE, init-value=0, base-type=BT_NM_PID_Lokalaktiv, compu {1=Cx1_war_lokal_aktiv (CM_NM_PID_Lokalaktiv_Cx1_war_lokal_aktiv), 0=Cx0_war_nicht_lokal_aktiv (CM_NM_PID_Lokalaktiv_Cx0_war_nicht_lokal_aktiv)}, range raw 0..1, transfer-property=PENDING  # Zeigt an ob das SG nach Klemme15 AUS und nach entsprechender MAX Aktivzeit noch aktiv war.
          signal NM_PID_Subsystemaktiv_XIX_KN_PID_XIX_HCP3_CANFD01: start 22, 1 bit, little-endian, data-type-policy=OVERRIDE, i-signal-type=PRIMITIVE, init-value=0, base-type=BT_NM_PID_Subsystemaktiv, compu {0=Cx0_war_nicht_lokal_aktiv (CM_NM_PID_Subsystemaktiv_Cx0_war_nicht_lokal_aktiv), 1=Cx1_war_lokal_aktiv (CM_NM_PID_Subsystemaktiv_Cx1_war_lokal_aktiv)}, range raw 0..1, transfer-property=PENDING  # Zeigt an ob ein Subsystem des SGs nach Klemme15 AUS und nach entsprechender MAX Aktivzeit noch aktiv war
          signal PID_KD_Fehler_XIX_KN_PID_XIX_HCP3_CANFD01: start 23, 1 bit, little-endian, data-type-policy=OVERRIDE, i-signal-type=PRIMITIVE, init-value=0, base-type=BT_PID_KD_Fehler, compu {0=Cx0_Kein_KD_Fehler (CM_PID_KD_Fehler_Cx0_Kein_KD_Fehler), 1=Cx1_KD_Fehler (CM_PID_KD_Fehler_Cx1_KD_Fehler)}, range raw 0..1, transfer-property=PENDING, to HCP3_IONode(timeout 2.5 s)  # Bei gesetztem Bit ist mindestens ein Kundendienstfehler eingetragen
          signal KN_PID_ECUKnockOutTimer_XIX_KN_PID_XIX_HCP3_CANFD01: start 24, 6 bit, little-endian, data-type-policy=OVERRIDE, i-signal-type=PRIMITIVE, init-value=15, base-type=BT_KN_PID_ECUKnockOutTimer, compu {phys=raw for raw 0..62, 63=Cx3f_ECUKnockOut_deaktiviert (CM_KN_PID_ECUKnockOutTimer_Cx3f_ECUKnockOut_deaktiviert); unit Unit_Minut}, range phys 0..62 Unit_Minut, raw 0..63, unit=Unit_Minut, transfer-property=PENDING  # Ausgabe des ECUKnockOut-Timer
          signal KN_PID_BusKnockOut_XIX_KN_PID_XIX_HCP3_CANFD01: start 30, 2 bit, little-endian, data-type-policy=OVERRIDE, i-signal-type=PRIMITIVE, init-value=0, base-type=BT_KN_PID_BusKnockOut, compu {0=Cx0_Funktion_nicht_ausgeloest (CM_KN_PID_BusKnockOut_Cx0_Funktion_nicht_ausgeloest), 3=Cx3_Funktion_deaktiviert (CM_KN_PID_BusKnockOut_Cx3_Funktion_deaktiviert), 2=Cx2_Funktion_ausgeloest (CM_KN_PID_BusKnockOut_Cx2_Funktion_ausgeloest), 1=Cx1_Veto_aktiv (CM_KN_PID_BusKnockOut_Cx1_Veto_aktiv)}, range raw 0..3, transfer-property=PENDING  # Ausgabe des BusKnockout-Status
          signal KN_PID_BusKnockOutTimer_XIX_KN_PID_XIX_HCP3_CANFD01: start 32, 8 bit, little-endian, data-type-policy=OVERRIDE, i-signal-type=PRIMITIVE, init-value=15, base-type=BT_KN_PID_BusKnockOutTimer, compu {phys=raw for raw 0..254, 255=Cxff_BusKnockOut_deaktiviert (CM_KN_PID_BusKnockOutTimer_Cxff_BusKnockOut_deaktiviert); unit Unit_Minut}, range phys 0..254 Unit_Minut, raw 0..255, unit=Unit_Minut, transfer-property=PENDING  # Ausgabe des BusKnockOut-Timer
          signal NM_PID_FCIB_XIX_KN_PID_XIX_HCP3_CANFD01: start 40, 56 bit, opaque, data-type-policy=OVERRIDE, i-signal-type=ARRAY, init-value=[1, 128, 0, 0, 0, 8, 0], base-type=BT_NM_PID_FCIB, compu {16384=Cx4000_15_InstrumentclusterDisplay (CM_NM_PID_FCIB_Cx4000_15_InstrumentclusterDisplay), 32768=Cx8000_16_InfotainmentDisplay (CM_NM_PID_FCIB_Cx8000_16_InfotainmentDisplay), 35184372088832=Cx200000000000_46_Diagnosis_Light (CM_NM_PID_FCIB_Cx200000000000_46_Diagnosis_Light), 17592186044416=Cx100000000000_45_Diagnosis_Comfort (CM_NM_PID_FCIB_Cx100000000000_45_Diagnosis_Comfort), 1073741824=Cx40000000_31_MultifunctionalSteeringWheel (CM_NM_PID_FCIB_Cx40000000_31_MultifunctionalSteeringWheel), 1048576=Cx100000_21_AirSuspension (CM_NM_PID_FCIB_Cx100000_21_AirSuspension), 67108864=Cx4000000_27_Timemaster_Timer (CM_NM_PID_FCIB_Cx4000000_27_Timemaster_Timer), 524288=Cx80000_20_OptionalComfort (CM_NM_PID_FCIB_Cx80000_20_OptionalComfort), 18014398509481984=Cx40000000000000_55_Dimming (CM_NM_PID_FCIB_Cx40000000000000_55_Dimming), 4294967296=Cx100000000_33_ExternalWirelessCommunication (CM_NM_PID_FCIB_Cx100000000_33_ExternalWirelessCommunication), 16777216=Cx1000000_25_AccessSystemSensors (CM_NM_PID_FCIB_Cx1000000_25_AccessSystemSensors), 2147483648=Cx80000000_32_OnlineAccess (CM_NM_PID_FCIB_Cx80000000_32_OnlineAccess), 536870912=Cx20000000_30_EnergyManagement (CM_NM_PID_FCIB_Cx20000000_30_EnergyManagement), 1024=Cx400_11_Chassis (CM_NM_PID_FCIB_Cx400_11_Chassis), 1099511627776=Cx10000000000_41_Diagnosis_Powertrain (CM_NM_PID_FCIB_Cx10000000000_41_Diagnosis_Powertrain), 4503599627370496=Cx10000000000000_53_Lock_Unlock (CM_NM_PID_FCIB_Cx10000000000000_53_Lock_Unlock), 512=Cx200_10_Powertrain (CM_NM_PID_FCIB_Cx200_10_Powertrain), 34359738368=Cx800000000_36_Preheater (CM_NM_PID_FCIB_Cx800000000_36_Preheater), 32=Cx20_06_Basefunction_ComfortLight (CM_NM_PID_FCIB_Cx20_06_Basefunction_ComfortLight), 68719476736=Cx1000000000_37_HighVoltage_WirelessChargingStation (CM_NM_PID_FCIB_Cx1000000000_37_HighVoltage_WirelessChargingStation), 8589934592=Cx200000000_34_GPS_Localization (CM_NM_PID_FCIB_Cx200000000_34_GPS_Localization), 4194304=Cx400000_23_Climate (CM_NM_PID_FCIB_Cx400000_23_Climate), 128=Cx80_08_Basefunction_Connectivity (CM_NM_PID_FCIB_Cx80_08_Basefunction_Connectivity), 64=Cx40_07_Basefunction_CrossSection (CM_NM_PID_FCIB_Cx40_07_Basefunction_CrossSection), 549755813888=Cx8000000000_40_Diagnosis_Energy (CM_NM_PID_FCIB_Cx8000000000_40_Diagnosis_Energy), 134217728=Cx8000000_28_OnboardTester_DataCollector (CM_NM_PID_FCIB_Cx8000000_28_OnboardTester_DataCollector), 2=Cx2_02_Basefunction_Powertrain (CM_NM_PID_FCIB_Cx2_02_Basefunction_Powertrain), 8796093022208=Cx80000000000_44_Diagnosis_Infotainment (CM_NM_PID_FCIB_Cx80000000000_44_Diagnosis_Infotainment), 131072=Cx20000_18_VirtualSideMirrors (CM_NM_PID_FCIB_Cx20000_18_VirtualSideMirrors), 2048=Cx800_12_GearSelector (CM_NM_PID_FCIB_Cx800_12_GearSelector), 256=Cx100_09_reserved (CM_NM_PID_FCIB_Cx100_09_reserved) (09_<reserved>), 262144=Cx40000_19_Doors_Hatches (CM_NM_PID_FCIB_Cx40000_19_Doors_Hatches), 140737488355328=Cx800000000000_48_Diagnosis_ClimateTmeLINs (CM_NM_PID_FCIB_Cx800000000000_48_Diagnosis_ClimateTmeLINs), 8=Cx8_04_Basefunction_DrivingAssistance (CM_NM_PID_FCIB_Cx8_04_Basefunction_DrivingAssistance), 17179869184=Cx400000000_35_ExteriorSound (CM_NM_PID_FCIB_Cx400000000_35_ExteriorSound), 36028797018963968=Cx80000000000000_56_ChargingStatus (CM_NM_PID_FCIB_Cx80000000000000_56_ChargingStatus), 4096=Cx1000_13_Airbag (CM_NM_PID_FCIB_Cx1000_13_Airbag), 4=Cx4_03_Basefunction_Chassis (CM_NM_PID_FCIB_Cx4_03_Basefunction_Chassis), 16=Cx10_05_Basefunction_Infotainment (CM_NM_PID_FCIB_Cx10_05_Basefunction_Infotainment), 9007199254740992=Cx20000000000000_54_reserved (CM_NM_PID_FCIB_Cx20000000000000_54_reserved) (54_<reserved>), 65536=Cx10000_17_Audio (CM_NM_PID_FCIB_Cx10000_17_Audio), 8192=Cx2000_14_InfotainmentExtensions (CM_NM_PID_FCIB_Cx2000_14_InfotainmentExtensions), 281474976710656=Cx1000000000000_49_reserved (CM_NM_PID_FCIB_Cx1000000000000_49_reserved) (49_<reserved>), 33554432=Cx2000000_26_HighVoltage_Charging (CM_NM_PID_FCIB_Cx2000000_26_HighVoltage_Charging), 70368744177664=Cx400000000000_47_Diagnosis_ComfortLINs (CM_NM_PID_FCIB_Cx400000000000_47_Diagnosis_ComfortLINs), 4398046511104=Cx40000000000_43_Diagnosis_DrivingAssistance (CM_NM_PID_FCIB_Cx40000000000_43_Diagnosis_DrivingAssistance), 268435456=Cx10000000_29_SteeringColumnLock (CM_NM_PID_FCIB_Cx10000000_29_SteeringColumnLock), 2199023255552=Cx20000000000_42_Diagnosis_FlexRay (CM_NM_PID_FCIB_Cx20000000000_42_Diagnosis_FlexRay), 8388608=Cx800000_24_ThermoManagement (CM_NM_PID_FCIB_Cx800000_24_ThermoManagement), 2097152=Cx200000_22_ExteriorLights (CM_NM_PID_FCIB_Cx200000_22_ExteriorLights), 1=Cx1_01_CarWakeUp (CM_NM_PID_FCIB_Cx1_01_CarWakeUp), 8796093054977=Cx80000008001_InitValueFCIB (CM_NM_PID_FCIB_Cx80000008001_InitValueFCIB)}, range raw 1..36028797018963968, transfer-property=PENDING, to HCP3_IONode(timeout 5 s)  # FCIB = Funktions-Cluster-Initialisierungs-Bits
      frame KN_WLC1_XIX_HCP3_CANFD01: id 0x17F000A5, to HCP3_IONode, frame-length=16, can-addressing-mode=EXTENDED, can-frame-rx-behavior=CAN-FD, can-frame-tx-behavior=CAN-FD
        pdu KN_WLC1_XIX_HCP3_CANFD01: length=16, transmission-mode-true-timing=cyclic-timing={time-offset=0.0, time-period=0.5}, unused-bit-pattern=0
          signal WLC1_KompSchutz_XIX_KN_WLC1_XIX_HCP3_CANFD01: start 0, 1 bit, little-endian, data-type-policy=OVERRIDE, i-signal-type=PRIMITIVE, init-value=0, base-type=BT_WLC1_KompSchutz, compu {0=Cx0_inaktiv (CM_WLC1_KompSchutz_Cx0_inaktiv), 1=Cx1_aktiv (CM_WLC1_KompSchutz_Cx1_aktiv)}, range raw 0..1, transfer-property=PENDING  # Funktionseinschränkung aufgrund Komponentenschutz aktiv
          signal WLC1_Abschaltstufe_XIX_KN_WLC1_XIX_HCP3_CANFD01: start 1, 1 bit, little-endian, data-type-policy=OVERRIDE, i-signal-type=PRIMITIVE, init-value=0, base-type=BT_WLC1_Abschaltstufe, compu {0=Cx0_keine_Einschraenkung (CM_WLC1_Abschaltstufe_Cx0_keine_Einschraenkung), 1=Cx1_Funktionseinschraenkung (CM_WLC1_Abschaltstufe_Cx1_Funktionseinschraenkung)}, range raw 0..1, transfer-property=PENDING  # Funktionseinschränkung aufgrund aktiver Abschaltstufe
          signal WLC1_Transport_Mode_XIX_KN_WLC1_XIX_HCP3_CANFD01: start 2, 1 bit, little-endian, data-type-policy=OVERRIDE, i-signal-type=PRIMITIVE, init-value=0, base-type=BT_WLC1_Transport_Mode, compu {1=Cx1_Funktionseinschraenkung (CM_WLC1_Transport_Mode_Cx1_Funktionseinschraenkung), 0=Cx0_keine_Einschraenkung (CM_WLC1_Transport_Mode_Cx0_keine_Einschraenkung)}, range raw 0..1, transfer-property=PENDING  # Funktionseinschränkung aufgrund aktivem Transport Mode und/oder Transport Schutz
          signal WLC1_Nachlauftyp_XIX_KN_WLC1_XIX_HCP3_CANFD01: start 4, 4 bit, little-endian, data-type-policy=OVERRIDE, i-signal-type=PRIMITIVE, init-value=2, base-type=BT_WLC1_Nachlauftyp, compu {1=Cx1_Komm_nach_KL15_AUS (CM_WLC1_Nachlauftyp_Cx1_Komm_nach_KL15_AUS), 0=Cx0_Komm_bei_KL15_EIN (CM_WLC1_Nachlauftyp_Cx0_Komm_bei_KL15_EIN), 2=Cx2_Komm_bei_KL15_AUS (CM_WLC1_Nachlauftyp_Cx2_Komm_bei_KL15_AUS)}, range raw 0..2, transfer-property=PENDING, to HCP3_IONode(timeout 5 s)  # Abgebildet wird die von der Hardware vorgegebene Möglichkeit, die Kommunikation nach Klemme 15 = AUS aufrecht zu erhalten. Es wird ein Init-Wert gesendet.
          signal WLC1_SNI_10_XIX_KN_WLC1_XIX_HCP3_CANFD01: start 8, 10 bit, little-endian, data-type-policy=OVERRIDE, i-signal-type=PRIMITIVE, init-value=165, base-type=BT_WLC1_SNI_10, compu {phys=raw for raw 0..1023; unit Unit_None}, range phys 0..1023 Unit_None, raw 0..1023, unit=Unit_None, transfer-property=PENDING, to HCP3_IONode(timeout 5 s)  # Source Node-Identifier (SNI) identifiziert den Sender der NM-Botschaft (Knotenadresse) eindeutig im Fahrzeug
          signal KN_WLC1_ECUKnockOut_XIX_KN_WLC1_XIX_HCP3_CANFD01: start 18, 2 bit, little-endian, data-type-policy=OVERRIDE, i-signal-type=PRIMITIVE, init-value=0, base-type=BT_KN_WLC1_ECUKnockOut, compu {1=Cx1_Veto_war_aktiv (CM_KN_WLC1_ECUKnockOut_Cx1_Veto_war_aktiv), 0=Cx0_Funktion_nicht_ausgeloest (CM_KN_WLC1_ECUKnockOut_Cx0_Funktion_nicht_ausgeloest), 3=Cx3_Funktion_deaktiviert (CM_KN_WLC1_ECUKnockOut_Cx3_Funktion_deaktiviert), 2=Cx2_Funktion_ausgeloest (CM_KN_WLC1_ECUKnockOut_Cx2_Funktion_ausgeloest)}, range raw 0..3, transfer-property=PENDING  # Ausgabe des ECUKnockout-Status
          signal KN_WLC1_DiagPfad_V12_XIX_KN_WLC1_XIX_HCP3_CANFD01: start 20, 1 bit, little-endian, data-type-policy=OVERRIDE, i-signal-type=PRIMITIVE, init-value=0, base-type=BT_KN_WLC1_DiagPfad_V12, compu {1=Cx1_inaktiv (CM_KN_WLC1_DiagPfad_V12_Cx1_inaktiv), 0=Cx0_Aktiv (CM_KN_WLC1_DiagPfad_V12_Cx0_Aktiv)}, range raw 0..1, transfer-property=PENDING, to HCP3_IONode(timeout 5 s)  # Kennzeichnung der Diagnosefaehigkeit des BusInterfaces eines Steuergeraetes (Knoten) Umfang LAH 80127 Bei Nutzung des Signal explizit pro angebundenem BusInterface zu setzen
          signal WLC1_KD_Fehler_XIX_KN_WLC1_XIX_HCP3_CANFD01: start 23, 1 bit, little-endian, data-type-policy=OVERRIDE, i-signal-type=PRIMITIVE, init-value=0, base-type=BT_WLC1_KD_Fehler, compu {0=Cx0_Kein_KD_Fehler (CM_WLC1_KD_Fehler_Cx0_Kein_KD_Fehler) (Kein KD_Fehler), 1=Cx1_KD_Fehler (CM_WLC1_KD_Fehler_Cx1_KD_Fehler)}, range raw 0..1, transfer-property=PENDING, to HCP3_IONode(timeout 2.5 s)  # Bei gesetztem Bit ist mindestens ein Kundendienstfehler eingetragen
          signal KN_WLC1_ECUKnockOutTimer_XIX_KN_WLC1_XIX_HCP3_CANFD01: start 24, 6 bit, little-endian, data-type-policy=OVERRIDE, i-signal-type=PRIMITIVE, init-value=15, base-type=BT_KN_WLC1_ECUKnockOutTimer, compu {phys=raw for raw 0..62, 63=Cx3f_ECUKnockOut_deaktiviert (CM_KN_WLC1_ECUKnockOutTimer_Cx3f_ECUKnockOut_deaktiviert); unit Unit_Minut}, range phys 0..62 Unit_Minut, raw 0..63, unit=Unit_Minut, transfer-property=PENDING  # Ausgabe des ECUKnockOut-Timer
          signal KN_WLC1_BusKnockOut_XIX_KN_WLC1_XIX_HCP3_CANFD01: start 30, 2 bit, little-endian, data-type-policy=OVERRIDE, i-signal-type=PRIMITIVE, init-value=0, base-type=BT_KN_WLC1_BusKnockOut, compu {1=Cx1_Veto_aktiv (CM_KN_WLC1_BusKnockOut_Cx1_Veto_aktiv), 3=Cx3_Funktion_deaktiviert (CM_KN_WLC1_BusKnockOut_Cx3_Funktion_deaktiviert), 0=Cx0_Funktion_nicht_ausgeloest (CM_KN_WLC1_BusKnockOut_Cx0_Funktion_nicht_ausgeloest), 2=Cx2_Funktion_ausgeloest (CM_KN_WLC1_BusKnockOut_Cx2_Funktion_ausgeloest)}, range raw 0..3, transfer-property=PENDING  # Ausgabe des BusKnockout-Status
          signal KN_WLC1_BusKnockOutTimer_XIX_KN_WLC1_XIX_HCP3_CANFD01: start 32, 8 bit, little-endian, data-type-policy=OVERRIDE, i-signal-type=PRIMITIVE, init-value=15, base-type=BT_KN_WLC1_BusKnockOutTimer, compu {phys=raw for raw 0..254, 255=Cxff_BusKnockOut_deaktiviert (CM_KN_WLC1_BusKnockOutTimer_Cxff_BusKnockOut_deaktiviert); unit Unit_Minut}, range phys 0..254 Unit_Minut, raw 0..255, unit=Unit_Minut, transfer-property=PENDING  # Ausgabe des BusKnockOut-Timer
          signal NM_WLC1_FCIB_XIX_KN_WLC1_XIX_HCP3_CANFD01: start 40, 56 bit, opaque, data-type-policy=OVERRIDE, i-signal-type=ARRAY, init-value=[1, 128, 0, 0, 0, 8, 0], base-type=BT_NM_WLC1_FCIB, compu {32768=Cx8000_16_InfotainmentDisplay (CM_NM_WLC1_FCIB_Cx8000_16_InfotainmentDisplay), 1048576=Cx100000_21_AirSuspension (CM_NM_WLC1_FCIB_Cx100000_21_AirSuspension), 4194304=Cx400000_23_Climate (CM_NM_WLC1_FCIB_Cx400000_23_Climate), 2147483648=Cx80000000_32_OnlineAccess (CM_NM_WLC1_FCIB_Cx80000000_32_OnlineAccess), 8388608=Cx800000_24_ThermoManagement (CM_NM_WLC1_FCIB_Cx800000_24_ThermoManagement), 128=Cx80_08_Basefunction_Connectivity (CM_NM_WLC1_FCIB_Cx80_08_Basefunction_Connectivity), 68719476736=Cx1000000000_37_HighVoltage_WirelessChargingStation (CM_NM_WLC1_FCIB_Cx1000000000_37_HighVoltage_WirelessChargingStation), 4398046511104=Cx40000000000_43_Diagnosis_DrivingAssistance (CM_NM_WLC1_FCIB_Cx40000000000_43_Diagnosis_DrivingAssistance), 4=Cx4_03_Basefunction_Chassis (CM_NM_WLC1_FCIB_Cx4_03_Basefunction_Chassis), 8589934592=Cx200000000_34_GPS_Localization (CM_NM_WLC1_FCIB_Cx200000000_34_GPS_Localization), 281474976710656=Cx1000000000000_49_reserved (CM_NM_WLC1_FCIB_Cx1000000000000_49_reserved) (49_<reserved>), 512=Cx200_10_Powertrain (CM_NM_WLC1_FCIB_Cx200_10_Powertrain), 35184372088832=Cx200000000000_46_Diagnosis_Light (CM_NM_WLC1_FCIB_Cx200000000000_46_Diagnosis_Light), 4096=Cx1000_13_Airbag (CM_NM_WLC1_FCIB_Cx1000_13_Airbag), 16384=Cx4000_15_InstrumentclusterDisplay (CM_NM_WLC1_FCIB_Cx4000_15_InstrumentclusterDisplay), 4294967296=Cx100000000_33_ExternalWirelessCommunication (CM_NM_WLC1_FCIB_Cx100000000_33_ExternalWirelessCommunication), 131072=Cx20000_18_VirtualSideMirrors (CM_NM_WLC1_FCIB_Cx20000_18_VirtualSideMirrors), 134217728=Cx8000000_28_OnboardTester_DataCollector (CM_NM_WLC1_FCIB_Cx8000000_28_OnboardTester_DataCollector), 8796093022208=Cx80000000000_44_Diagnosis_Infotainment (CM_NM_WLC1_FCIB_Cx80000000000_44_Diagnosis_Infotainment), 16=Cx10_05_Basefunction_Infotainment (CM_NM_WLC1_FCIB_Cx10_05_Basefunction_Infotainment), 1073741824=Cx40000000_31_MultifunctionalSteeringWheel (CM_NM_WLC1_FCIB_Cx40000000_31_MultifunctionalSteeringWheel), 70368744177664=Cx400000000000_47_Diagnosis_ComfortLINs (CM_NM_WLC1_FCIB_Cx400000000000_47_Diagnosis_ComfortLINs), 256=Cx100_09_reserved (CM_NM_WLC1_FCIB_Cx100_09_reserved) (09_<reserved>), 33554432=Cx2000000_26_HighVoltage_Charging (CM_NM_WLC1_FCIB_Cx2000000_26_HighVoltage_Charging), 2097152=Cx200000_22_ExteriorLights (CM_NM_WLC1_FCIB_Cx200000_22_ExteriorLights), 4503599627370496=Cx10000000000000_53_Lock_Unlock (CM_NM_WLC1_FCIB_Cx10000000000000_53_Lock_Unlock), 2199023255552=Cx20000000000_42_Diagnosis_FlexRay (CM_NM_WLC1_FCIB_Cx20000000000_42_Diagnosis_FlexRay), 64=Cx40_07_Basefunction_CrossSection (CM_NM_WLC1_FCIB_Cx40_07_Basefunction_CrossSection), 32=Cx20_06_Basefunction_ComfortLight (CM_NM_WLC1_FCIB_Cx20_06_Basefunction_ComfortLight), 268435456=Cx10000000_29_SteeringColumnLock (CM_NM_WLC1_FCIB_Cx10000000_29_SteeringColumnLock), 549755813888=Cx8000000000_40_Diagnosis_Energy (CM_NM_WLC1_FCIB_Cx8000000000_40_Diagnosis_Energy), 8192=Cx2000_14_InfotainmentExtensions (CM_NM_WLC1_FCIB_Cx2000_14_InfotainmentExtensions), 18014398509481984=Cx40000000000000_55_Dimming (CM_NM_WLC1_FCIB_Cx40000000000000_55_Dimming), 1099511627776=Cx10000000000_41_Diagnosis_Powertrain (CM_NM_WLC1_FCIB_Cx10000000000_41_Diagnosis_Powertrain), 140737488355328=Cx800000000000_48_Diagnosis_ClimateTmeLINs (CM_NM_WLC1_FCIB_Cx800000000000_48_Diagnosis_ClimateTmeLINs), 17592186044416=Cx100000000000_45_Diagnosis_Comfort (CM_NM_WLC1_FCIB_Cx100000000000_45_Diagnosis_Comfort), 16777216=Cx1000000_25_AccessSystemSensors (CM_NM_WLC1_FCIB_Cx1000000_25_AccessSystemSensors), 2048=Cx800_12_GearSelector (CM_NM_WLC1_FCIB_Cx800_12_GearSelector), 1024=Cx400_11_Chassis (CM_NM_WLC1_FCIB_Cx400_11_Chassis), 536870912=Cx20000000_30_EnergyManagement (CM_NM_WLC1_FCIB_Cx20000000_30_EnergyManagement), 65536=Cx10000_17_Audio (CM_NM_WLC1_FCIB_Cx10000_17_Audio), 524288=Cx80000_20_OptionalComfort (CM_NM_WLC1_FCIB_Cx80000_20_OptionalComfort), 262144=Cx40000_19_Doors_Hatches (CM_NM_WLC1_FCIB_Cx40000_19_Doors_Hatches), 1=Cx1_01_CarWakeUp (CM_NM_WLC1_FCIB_Cx1_01_CarWakeUp), 67108864=Cx4000000_27_Timemaster_Timer (CM_NM_WLC1_FCIB_Cx4000000_27_Timemaster_Timer), 36028797018963968=Cx80000000000000_56_ChargingStatus (CM_NM_WLC1_FCIB_Cx80000000000000_56_ChargingStatus), 9007199254740992=Cx20000000000000_54_reserved (CM_NM_WLC1_FCIB_Cx20000000000000_54_reserved) (54_<reserved>), 2=Cx2_02_Basefunction_Powertrain (CM_NM_WLC1_FCIB_Cx2_02_Basefunction_Powertrain), 17179869184=Cx400000000_35_ExteriorSound (CM_NM_WLC1_FCIB_Cx400000000_35_ExteriorSound), 34359738368=Cx800000000_36_Preheater (CM_NM_WLC1_FCIB_Cx800000000_36_Preheater), 8796093054977=Cx80000008001_InitValueFCIB (CM_NM_WLC1_FCIB_Cx80000008001_InitValueFCIB), 8=Cx8_04_Basefunction_DrivingAssistance (CM_NM_WLC1_FCIB_Cx8_04_Basefunction_DrivingAssistance)}, range raw 1..36028797018963968, transfer-property=PENDING, to HCP3_IONode(timeout 5 s)  # FCIB = Funktions-Cluster-Initialisierungs-Bits
      frame KN_WLC2_XIX_HCP3_CANFD01: id 0x17F000A6, to HCP3_IONode, frame-length=16, can-addressing-mode=EXTENDED, can-frame-rx-behavior=CAN-FD, can-frame-tx-behavior=CAN-FD
        pdu KN_WLC2_XIX_HCP3_CANFD01: length=16, transmission-mode-true-timing=cyclic-timing={time-offset=0.0, time-period=0.5}, unused-bit-pattern=0
          signal WLC2_KompSchutz_XIX_KN_WLC2_XIX_HCP3_CANFD01: start 0, 1 bit, little-endian, data-type-policy=OVERRIDE, i-signal-type=PRIMITIVE, init-value=0, base-type=BT_WLC2_KompSchutz, compu {0=Cx0_inaktiv (CM_WLC2_KompSchutz_Cx0_inaktiv), 1=Cx1_aktiv (CM_WLC2_KompSchutz_Cx1_aktiv)}, range raw 0..1, transfer-property=PENDING  # Funktionseinschränkung aufgrund Komponentenschutz aktiv
          signal WLC2_Abschaltstufe_XIX_KN_WLC2_XIX_HCP3_CANFD01: start 1, 1 bit, little-endian, data-type-policy=OVERRIDE, i-signal-type=PRIMITIVE, init-value=0, base-type=BT_WLC2_Abschaltstufe, compu {0=Cx0_keine_Einschraenkung (CM_WLC2_Abschaltstufe_Cx0_keine_Einschraenkung), 1=Cx1_Funktionseinschraenkung (CM_WLC2_Abschaltstufe_Cx1_Funktionseinschraenkung)}, range raw 0..1, transfer-property=PENDING  # Funktionseinschränkung aufgrund aktiver Abschaltstufe
          signal WLC2_Transport_Mode_XIX_KN_WLC2_XIX_HCP3_CANFD01: start 2, 1 bit, little-endian, data-type-policy=OVERRIDE, i-signal-type=PRIMITIVE, init-value=0, base-type=BT_WLC2_Transport_Mode, compu {1=Cx1_Funktionseinschraenkung (CM_WLC2_Transport_Mode_Cx1_Funktionseinschraenkung), 0=Cx0_keine_Einschraenkung (CM_WLC2_Transport_Mode_Cx0_keine_Einschraenkung)}, range raw 0..1, transfer-property=PENDING  # Funktionseinschränkung aufgrund aktivem Transport Mode und/oder Transport Schutz
          signal WLC2_Nachlauftyp_XIX_KN_WLC2_XIX_HCP3_CANFD01: start 4, 4 bit, little-endian, data-type-policy=OVERRIDE, i-signal-type=PRIMITIVE, init-value=2, base-type=BT_WLC2_Nachlauftyp, compu {1=Cx1_Komm_nach_KL15_AUS (CM_WLC2_Nachlauftyp_Cx1_Komm_nach_KL15_AUS), 2=Cx2_Komm_bei_KL15_AUS (CM_WLC2_Nachlauftyp_Cx2_Komm_bei_KL15_AUS), 0=Cx0_Komm_bei_KL15_EIN (CM_WLC2_Nachlauftyp_Cx0_Komm_bei_KL15_EIN)}, range raw 0..2, transfer-property=PENDING, to HCP3_IONode(timeout 5 s)  # Abgebildet wird die von der Hardware vorgegebene Möglichkeit, die Kommunikation nach Klemme 15 = AUS aufrecht zu erhalten. Es wird ein Init-Wert gesendet.
          signal WLC2_SNI_10_XIX_KN_WLC2_XIX_HCP3_CANFD01: start 8, 10 bit, little-endian, data-type-policy=OVERRIDE, i-signal-type=PRIMITIVE, init-value=166, base-type=BT_WLC2_SNI_10, compu {phys=raw for raw 0..1023; unit Unit_None}, range phys 0..1023 Unit_None, raw 0..1023, unit=Unit_None, transfer-property=PENDING, to HCP3_IONode(timeout 5 s)  # Source Node-Identifier (SNI) identifiziert den Sender der NM-Botschaft (Knotenadresse) eindeutig im Fahrzeug
          signal KN_WLC2_ECUKnockOut_XIX_KN_WLC2_XIX_HCP3_CANFD01: start 18, 2 bit, little-endian, data-type-policy=OVERRIDE, i-signal-type=PRIMITIVE, init-value=0, base-type=BT_KN_WLC2_ECUKnockOut, compu {2=Cx2_Funktion_ausgeloest (CM_KN_WLC2_ECUKnockOut_Cx2_Funktion_ausgeloest), 1=Cx1_Veto_war_aktiv (CM_KN_WLC2_ECUKnockOut_Cx1_Veto_war_aktiv), 0=Cx0_Funktion_nicht_ausgeloest (CM_KN_WLC2_ECUKnockOut_Cx0_Funktion_nicht_ausgeloest), 3=Cx3_Funktion_deaktiviert (CM_KN_WLC2_ECUKnockOut_Cx3_Funktion_deaktiviert)}, range raw 0..3, transfer-property=PENDING  # Ausgabe des ECUKnockout-Status
          signal KN_WLC2_DiagPfad_V12_XIX_KN_WLC2_XIX_HCP3_CANFD01: start 20, 1 bit, little-endian, data-type-policy=OVERRIDE, i-signal-type=PRIMITIVE, init-value=0, base-type=BT_KN_WLC2_DiagPfad_V12, compu {1=Cx1_inaktiv (CM_KN_WLC2_DiagPfad_V12_Cx1_inaktiv), 0=Cx0_Aktiv (CM_KN_WLC2_DiagPfad_V12_Cx0_Aktiv)}, range raw 0..1, transfer-property=PENDING, to HCP3_IONode(timeout 5 s)  # Kennzeichnung der Diagnosefaehigkeit des BusInterfaces eines Steuergeraetes (Knoten) Umfang LAH 80127 Bei Nutzung des Signal explizit pro angebundenem BusInterface zu setzen
          signal WLC2_KD_Fehler_XIX_KN_WLC2_XIX_HCP3_CANFD01: start 23, 1 bit, little-endian, data-type-policy=OVERRIDE, i-signal-type=PRIMITIVE, init-value=0, base-type=BT_WLC2_KD_Fehler, compu {0=Cx0_Kein_KD_Fehler (CM_WLC2_KD_Fehler_Cx0_Kein_KD_Fehler) (Kein KD_Fehler), 1=Cx1_KD_Fehler (CM_WLC2_KD_Fehler_Cx1_KD_Fehler)}, range raw 0..1, transfer-property=PENDING, to HCP3_IONode(timeout 2.5 s)  # Bei gesetztem Bit ist mindestens ein Kundendienstfehler eingetragen
          signal KN_WLC2_ECUKnockOutTimer_XIX_KN_WLC2_XIX_HCP3_CANFD01: start 24, 6 bit, little-endian, data-type-policy=OVERRIDE, i-signal-type=PRIMITIVE, init-value=15, base-type=BT_KN_WLC2_ECUKnockOutTimer, compu {phys=raw for raw 0..62, 63=Cx3f_ECUKnockOut_deaktiviert (CM_KN_WLC2_ECUKnockOutTimer_Cx3f_ECUKnockOut_deaktiviert); unit Unit_Minut}, range phys 0..62 Unit_Minut, raw 0..63, unit=Unit_Minut, transfer-property=PENDING  # Ausgabe des ECUKnockOut-Timer
          signal KN_WLC2_BusKnockOut_XIX_KN_WLC2_XIX_HCP3_CANFD01: start 30, 2 bit, little-endian, data-type-policy=OVERRIDE, i-signal-type=PRIMITIVE, init-value=0, base-type=BT_KN_WLC2_BusKnockOut, compu {3=Cx3_Funktion_deaktiviert (CM_KN_WLC2_BusKnockOut_Cx3_Funktion_deaktiviert), 2=Cx2_Funktion_ausgeloest (CM_KN_WLC2_BusKnockOut_Cx2_Funktion_ausgeloest), 0=Cx0_Funktion_nicht_ausgeloest (CM_KN_WLC2_BusKnockOut_Cx0_Funktion_nicht_ausgeloest), 1=Cx1_Veto_aktiv (CM_KN_WLC2_BusKnockOut_Cx1_Veto_aktiv)}, range raw 0..3, transfer-property=PENDING  # Ausgabe des BusKnockout-Status
          signal KN_WLC2_BusKnockOutTimer_XIX_KN_WLC2_XIX_HCP3_CANFD01: start 32, 8 bit, little-endian, data-type-policy=OVERRIDE, i-signal-type=PRIMITIVE, init-value=15, base-type=BT_KN_WLC2_BusKnockOutTimer, compu {phys=raw for raw 0..254, 255=Cxff_BusKnockOut_deaktiviert (CM_KN_WLC2_BusKnockOutTimer_Cxff_BusKnockOut_deaktiviert); unit Unit_Minut}, range phys 0..254 Unit_Minut, raw 0..255, unit=Unit_Minut, transfer-property=PENDING  # Ausgabe des BusKnockOut-Timer
          signal NM_WLC2_FCIB_XIX_KN_WLC2_XIX_HCP3_CANFD01: start 40, 56 bit, opaque, data-type-policy=OVERRIDE, i-signal-type=ARRAY, init-value=[1, 128, 0, 0, 0, 8, 0], base-type=BT_NM_WLC2_FCIB, compu {4096=Cx1000_13_Airbag (CM_NM_WLC2_FCIB_Cx1000_13_Airbag), 8192=Cx2000_14_InfotainmentExtensions (CM_NM_WLC2_FCIB_Cx2000_14_InfotainmentExtensions), 2097152=Cx200000_22_ExteriorLights (CM_NM_WLC2_FCIB_Cx200000_22_ExteriorLights), 34359738368=Cx800000000_36_Preheater (CM_NM_WLC2_FCIB_Cx800000000_36_Preheater), 32=Cx20_06_Basefunction_ComfortLight (CM_NM_WLC2_FCIB_Cx20_06_Basefunction_ComfortLight), 4398046511104=Cx40000000000_43_Diagnosis_DrivingAssistance (CM_NM_WLC2_FCIB_Cx40000000000_43_Diagnosis_DrivingAssistance), 33554432=Cx2000000_26_HighVoltage_Charging (CM_NM_WLC2_FCIB_Cx2000000_26_HighVoltage_Charging), 64=Cx40_07_Basefunction_CrossSection (CM_NM_WLC2_FCIB_Cx40_07_Basefunction_CrossSection), 36028797018963968=Cx80000000000000_56_ChargingStatus (CM_NM_WLC2_FCIB_Cx80000000000000_56_ChargingStatus), 4503599627370496=Cx10000000000000_53_Lock_Unlock (CM_NM_WLC2_FCIB_Cx10000000000000_53_Lock_Unlock), 68719476736=Cx1000000000_37_HighVoltage_WirelessChargingStation (CM_NM_WLC2_FCIB_Cx1000000000_37_HighVoltage_WirelessChargingStation), 128=Cx80_08_Basefunction_Connectivity (CM_NM_WLC2_FCIB_Cx80_08_Basefunction_Connectivity), 65536=Cx10000_17_Audio (CM_NM_WLC2_FCIB_Cx10000_17_Audio), 524288=Cx80000_20_OptionalComfort (CM_NM_WLC2_FCIB_Cx80000_20_OptionalComfort), 512=Cx200_10_Powertrain (CM_NM_WLC2_FCIB_Cx200_10_Powertrain), 1073741824=Cx40000000_31_MultifunctionalSteeringWheel (CM_NM_WLC2_FCIB_Cx40000000_31_MultifunctionalSteeringWheel), 262144=Cx40000_19_Doors_Hatches (CM_NM_WLC2_FCIB_Cx40000_19_Doors_Hatches), 8796093022208=Cx80000000000_44_Diagnosis_Infotainment (CM_NM_WLC2_FCIB_Cx80000000000_44_Diagnosis_Infotainment), 256=Cx100_09_reserved (CM_NM_WLC2_FCIB_Cx100_09_reserved) (09_<reserved>), 536870912=Cx20000000_30_EnergyManagement (CM_NM_WLC2_FCIB_Cx20000000_30_EnergyManagement), 281474976710656=Cx1000000000000_49_reserved (CM_NM_WLC2_FCIB_Cx1000000000000_49_reserved) (49_<reserved>), 1=Cx1_01_CarWakeUp (CM_NM_WLC2_FCIB_Cx1_01_CarWakeUp), 32768=Cx8000_16_InfotainmentDisplay (CM_NM_WLC2_FCIB_Cx8000_16_InfotainmentDisplay), 8796093054977=Cx80000008001_InitValueFCIB (CM_NM_WLC2_FCIB_Cx80000008001_InitValueFCIB), 4=Cx4_03_Basefunction_Chassis (CM_NM_WLC2_FCIB_Cx4_03_Basefunction_Chassis), 140737488355328=Cx800000000000_48_Diagnosis_ClimateTmeLINs (CM_NM_WLC2_FCIB_Cx800000000000_48_Diagnosis_ClimateTmeLINs), 8589934592=Cx200000000_34_GPS_Localization (CM_NM_WLC2_FCIB_Cx200000000_34_GPS_Localization), 17592186044416=Cx100000000000_45_Diagnosis_Comfort (CM_NM_WLC2_FCIB_Cx100000000000_45_Diagnosis_Comfort), 8=Cx8_04_Basefunction_DrivingAssistance (CM_NM_WLC2_FCIB_Cx8_04_Basefunction_DrivingAssistance), 2=Cx2_02_Basefunction_Powertrain (CM_NM_WLC2_FCIB_Cx2_02_Basefunction_Powertrain), 18014398509481984=Cx40000000000000_55_Dimming (CM_NM_WLC2_FCIB_Cx40000000000000_55_Dimming), 16777216=Cx1000000_25_AccessSystemSensors (CM_NM_WLC2_FCIB_Cx1000000_25_AccessSystemSensors), 1099511627776=Cx10000000000_41_Diagnosis_Powertrain (CM_NM_WLC2_FCIB_Cx10000000000_41_Diagnosis_Powertrain), 16384=Cx4000_15_InstrumentclusterDisplay (CM_NM_WLC2_FCIB_Cx4000_15_InstrumentclusterDisplay), 4294967296=Cx100000000_33_ExternalWirelessCommunication (CM_NM_WLC2_FCIB_Cx100000000_33_ExternalWirelessCommunication), 134217728=Cx8000000_28_OnboardTester_DataCollector (CM_NM_WLC2_FCIB_Cx8000000_28_OnboardTester_DataCollector), 268435456=Cx10000000_29_SteeringColumnLock (CM_NM_WLC2_FCIB_Cx10000000_29_SteeringColumnLock), 16=Cx10_05_Basefunction_Infotainment (CM_NM_WLC2_FCIB_Cx10_05_Basefunction_Infotainment), 17179869184=Cx400000000_35_ExteriorSound (CM_NM_WLC2_FCIB_Cx400000000_35_ExteriorSound), 131072=Cx20000_18_VirtualSideMirrors (CM_NM_WLC2_FCIB_Cx20000_18_VirtualSideMirrors), 8388608=Cx800000_24_ThermoManagement (CM_NM_WLC2_FCIB_Cx800000_24_ThermoManagement), 35184372088832=Cx200000000000_46_Diagnosis_Light (CM_NM_WLC2_FCIB_Cx200000000000_46_Diagnosis_Light), 67108864=Cx4000000_27_Timemaster_Timer (CM_NM_WLC2_FCIB_Cx4000000_27_Timemaster_Timer), 2147483648=Cx80000000_32_OnlineAccess (CM_NM_WLC2_FCIB_Cx80000000_32_OnlineAccess), 70368744177664=Cx400000000000_47_Diagnosis_ComfortLINs (CM_NM_WLC2_FCIB_Cx400000000000_47_Diagnosis_ComfortLINs), 9007199254740992=Cx20000000000000_54_reserved (CM_NM_WLC2_FCIB_Cx20000000000000_54_reserved) (54_<reserved>), 2048=Cx800_12_GearSelector (CM_NM_WLC2_FCIB_Cx800_12_GearSelector), 1024=Cx400_11_Chassis (CM_NM_WLC2_FCIB_Cx400_11_Chassis), 549755813888=Cx8000000000_40_Diagnosis_Energy (CM_NM_WLC2_FCIB_Cx8000000000_40_Diagnosis_Energy), 4194304=Cx400000_23_Climate (CM_NM_WLC2_FCIB_Cx400000_23_Climate), 1048576=Cx100000_21_AirSuspension (CM_NM_WLC2_FCIB_Cx100000_21_AirSuspension), 2199023255552=Cx20000000000_42_Diagnosis_FlexRay (CM_NM_WLC2_FCIB_Cx20000000000_42_Diagnosis_FlexRay)}, range raw 1..36028797018963968, transfer-property=PENDING, to HCP3_IONode(timeout 5 s)  # FCIB = Funktions-Cluster-Initialisierungs-Bits
      frame KeyInpCID_CID_Req_FD_XIX_HCP3_CANFD01: id 0x1C446E22, from HCP3_IONode, frame-length=64, can-addressing-mode=EXTENDED, can-frame-rx-behavior=CAN-FD, can-frame-tx-behavior=CAN-FD
        n pdu KeyInpCID_CID_Req_FD_XIX_HCP3_CANFD01: length=64
      frame KeyInpCID_CID_Resp_FD_XIX_HCP3_CANFD01: id 0x1C466E22, to HCP3_IONode, frame-length=64, can-addressing-mode=EXTENDED, can-frame-rx-behavior=CAN-FD, can-frame-tx-behavior=CAN-FD
        n pdu KeyInpCID_CID_Resp_FD_XIX_HCP3_CANFD01: length=64
      frame KeyInpLSR_LSR_Req_FD_XIX_HCP3_CANFD01: id 0x1C446C24, from HCP3_IONode, frame-length=64, can-addressing-mode=EXTENDED, can-frame-rx-behavior=CAN-FD, can-frame-tx-behavior=CAN-FD
        n pdu KeyInpLSR_LSR_Req_FD_XIX_HCP3_CANFD01: length=64
      frame KeyInpLSR_LSR_Resp_FD_XIX_HCP3_CANFD01: id 0x1C466C24, to HCP3_IONode, frame-length=64, can-addressing-mode=EXTENDED, can-frame-rx-behavior=CAN-FD, can-frame-tx-behavior=CAN-FD
        n pdu KeyInpLSR_LSR_Resp_FD_XIX_HCP3_CANFD01: length=64
      frame KeyInpPID_PID_Req_FD_XIX_HCP3_CANFD01: id 0x1C446D23, from HCP3_IONode, frame-length=64, can-addressing-mode=EXTENDED, can-frame-rx-behavior=CAN-FD, can-frame-tx-behavior=CAN-FD
        n pdu KeyInpPID_PID_Req_FD_XIX_HCP3_CANFD01: length=64
      frame KeyInpPID_PID_Resp_FD_XIX_HCP3_CANFD01: id 0x1C466D23, to HCP3_IONode, frame-length=64, can-addressing-mode=EXTENDED, can-frame-rx-behavior=CAN-FD, can-frame-tx-behavior=CAN-FD
        n pdu KeyInpPID_PID_Resp_FD_XIX_HCP3_CANFD01: length=64
      frame KeylessAccess_01_XIX_HCP3_CANFD01: id 0x12DD5509, from HCP3_IONode, frame-length=32, can-addressing-mode=EXTENDED, can-frame-rx-behavior=CAN-FD, can-frame-tx-behavior=CAN-FD
        pdu KeylessAccess_01_XIX_HCP3_CANFD01:
          length=32
          minimum-delay=0.02
          transmission-mode-condition{data-filter={data-filter-type=MASKED-NEW-DIFFERS-X, mask=1, x=0}, i-signal-in-i-pdu=KeylessAccess_01_XIX_HCP3_CANFD01/VIP_Sensor_betaetigt}
          transmission-mode-false-timing={cyclic-timing={time-offset=0.0, time-period=0.2}, event-controlled-timing={number-of-repetitions=7, repetition-period=0.04}}
          transmission-mode-true-timing={cyclic-timing={time-offset=0.0, time-period=0.04}, event-controlled-timing={number-of-repetitions=7, repetition-period=0.04}}
          unused-bit-pattern=0
          signal Kessy_KeylessAccess_01_CRC_XIX_KeylessAccess_01_XIX_HCP3_CANFD01: start 0, 8 bit, little-endian, data-type-policy=OVERRIDE, i-signal-type=PRIMITIVE, init-value=0, base-type=BT_Kessy_KeylessAccess_01_CRC, compu {phys=raw for raw 0..255}, range phys 0..255, raw 0..255, transfer-property=TRIGGERED-WITHOUT-REPETITION  # Für MLB: Berechnung siehe Lastenheft "Kommunikationsabsicherung für FlexRay und CAN" Ab MQB und MLBevo: Berechnung siehe Lastenheft "End-to-End Kommunikationsabsicherung" Endwerte siehe Begleitdokument "S-PDU Kennungsfolgen"
          signal Kessy_KeylessAccess_01_BZ_XIX_KeylessAccess_01_XIX_HCP3_CANFD01: start 8, 4 bit, little-endian, data-type-policy=OVERRIDE, i-signal-type=PRIMITIVE, init-value=0, base-type=BT_Kessy_KeylessAccess_01_BZ, compu {phys=raw for raw 0..15}, range phys 0..15, raw 0..15, transfer-property=TRIGGERED-WITHOUT-REPETITION  # 4bit Botschaftszähler, wird mit jeder Sendebotschaft inkrementiert
          signal KY_Fzg_Verlassen_erkannt_XIX_KeylessAccess_01_XIX_HCP3_CANFD01: start 19, 1 bit, little-endian, data-type-policy=OVERRIDE, i-signal-type=PRIMITIVE, init-value=0, base-type=BT_KY_Fzg_Verlassen_erkannt, compu {1=Cx1_erkannt (CM_KY_Fzg_Verlassen_erkannt_Cx1_erkannt), 0=Cx0_nicht_erkannt (CM_KY_Fzg_Verlassen_erkannt_Cx0_nicht_erkannt)}, range raw 0..1, transfer-property=TRIGGERED-WITHOUT-REPETITION  # Fahrer/Schlüssel hat das Fahrzeug verlassen und FT wurde geschlossen
          signal KY_Front_Entr_Autorisiert_02_XIX_KeylessAccess_01_XIX_HCP3_CANFD01: start 20, 2 bit, little-endian, data-type-policy=OVERRIDE, i-signal-type=PRIMITIVE, init-value=0, base-type=BT_KY_Front_Entr_Autorisiert_02, invalid-value=Invalid_KY_Front_Entr_Autorisiert_02_XIX_KeylessAccess_01_XIX_HCP3_CANFD01:3, compu {3=Cx3_Fehler (CM_KY_Front_Entr_Autorisiert_02_Cx3_Fehler), 1=Cx1_kein_Keylessschluessel_erkannt (CM_KY_Front_Entr_Autorisiert_02_Cx1_kein_Keylessschluessel_erkannt), 2=Cx2_Keyless_Schluessel_erkannt_und_authorisiert (CM_KY_Front_Entr_Autorisiert_02_Cx2_Keyless_Schluessel_erkannt_und_authorisiert), 0=Cx0_Init_oder_nicht_verbaut (CM_KY_Front_Entr_Autorisiert_02_Cx0_Init_oder_nicht_verbaut)}, range raw 0..3, transfer-property=TRIGGERED-WITHOUT-REPETITION  # Erkennung / Authorisierung Keyless Front
          signal KY_Front_Verr_Autorisiert_02_XIX_KeylessAccess_01_XIX_HCP3_CANFD01: start 22, 2 bit, little-endian, data-type-policy=OVERRIDE, i-signal-type=PRIMITIVE, init-value=0, base-type=BT_KY_Front_Verr_Autorisiert_02, invalid-value=Invalid_KY_Front_Verr_Autorisiert_02_XIX_KeylessAccess_01_XIX_HCP3_CANFD01:3, compu {3=Cx3_Fehler (CM_KY_Front_Verr_Autorisiert_02_Cx3_Fehler), 1=Cx1_Verriegelungssensor_erkannt (CM_KY_Front_Verr_Autorisiert_02_Cx1_Verriegelungssensor_erkannt), 0=Cx0_Init_oder_nicht_verbaut (CM_KY_Front_Verr_Autorisiert_02_Cx0_Init_oder_nicht_verbaut), 2=Cx2_Verriegelungssensor_erkannt_und_authorisiert (CM_KY_Front_Verr_Autorisiert_02_Cx2_Verriegelungssensor_erkannt_und_authorisiert)}, range raw 0..3, transfer-property=TRIGGERED-WITHOUT-REPETITION  # Authorisierung Verriegelungssensor Keyless Front
          signal KY_HD_Entr_Autorisiert_02_XIX_KeylessAccess_01_XIX_HCP3_CANFD01: start 32, 2 bit, little-endian, data-type-policy=OVERRIDE, i-signal-type=PRIMITIVE, init-value=0, base-type=BT_KY_HD_Entr_Autorisiert_02, invalid-value=Invalid_KY_HD_Entr_Autorisiert_02_XIX_KeylessAccess_01_XIX_HCP3_CANFD01:3, compu {3=Cx3_Fehler (CM_KY_HD_Entr_Autorisiert_02_Cx3_Fehler), 0=Cx0_Init_oder_nicht_verbaut (CM_KY_HD_Entr_Autorisiert_02_Cx0_Init_oder_nicht_verbaut), 1=Cx1_kein_Keylessschluessel_erkannt (CM_KY_HD_Entr_Autorisiert_02_Cx1_kein_Keylessschluessel_erkannt), 2=Cx2_Keyless_Schluessel_erkannt_und_authorisiert (CM_KY_HD_Entr_Autorisiert_02_Cx2_Keyless_Schluessel_erkannt_und_authorisiert)}, range raw 0..3, transfer-property=TRIGGERED-WITHOUT-REPETITION  # Erkennung / Authorisierung Keyless Heck
          signal KY_HD_Verr_Autorisiert_02_XIX_KeylessAccess_01_XIX_HCP3_CANFD01: start 34, 2 bit, little-endian, data-type-policy=OVERRIDE, i-signal-type=PRIMITIVE, init-value=0, base-type=BT_KY_HD_Verr_Autorisiert_02, invalid-value=Invalid_KY_HD_Verr_Autorisiert_02_XIX_KeylessAccess_01_XIX_HCP3_CANFD01:3, compu {3=Cx3_Fehler (CM_KY_HD_Verr_Autorisiert_02_Cx3_Fehler), 1=Cx1_Verriegelungssensor_erkannt (CM_KY_HD_Verr_Autorisiert_02_Cx1_Verriegelungssensor_erkannt), 0=Cx0_Init_oder_nicht_verbaut (CM_KY_HD_Verr_Autorisiert_02_Cx0_Init_oder_nicht_verbaut), 2=Cx2_Verriegelungssensor_erkannt_und_authorisiert (CM_KY_HD_Verr_Autorisiert_02_Cx2_Verriegelungssensor_erkannt_und_authorisiert)}, range raw 0..3, transfer-property=TRIGGERED-WITHOUT-REPETITION  # Autorisierung der Schließanforderung über Verriegelungsinnentaster
          signal FBS_Anf_Access_Auth_XIX_KeylessAccess_01_XIX_HCP3_CANFD01: start 36, 1 bit, little-endian, data-type-policy=OVERRIDE, i-signal-type=PRIMITIVE, init-value=0, base-type=BT_FBS_Anf_Access_Auth, compu {0=Cx0_Init_kein_Auth_Request (CM_FBS_Anf_Access_Auth_Cx0_Init_kein_Auth_Request), 1=Cx1_Auth_Request (CM_FBS_Anf_Access_Auth_Cx1_Auth_Request)}, range raw 0..1, transfer-property=TRIGGERED-WITHOUT-REPETITION  # Trigger um Authentifikation für Zugang zu starten
          signal KY_FDF_Taste_XIX_KeylessAccess_01_XIX_HCP3_CANFD01: start 37, 1 bit, little-endian, data-type-policy=OVERRIDE, i-signal-type=PRIMITIVE, init-value=0, base-type=BT_KY_FDF_Taste, compu {0=Cx0_Taste_nicht_betaetigt (CM_KY_FDF_Taste_Cx0_Taste_nicht_betaetigt), 1=Cx1_FDF_Taste_am_Funkschluessel_betaetigt (CM_KY_FDF_Taste_Cx1_FDF_Taste_am_Funkschluessel_betaetigt)}, range raw 0..1, transfer-property=TRIGGERED-WITHOUT-REPETITION  # Front Deckel Fernentriegelung Taste am Funkschluessel
          signal KY_Mehrere_Schluessel_aussen_XIX_KeylessAccess_01_XIX_HCP3_CANFD01: start 38, 1 bit, little-endian, data-type-policy=OVERRIDE, i-signal-type=PRIMITIVE, init-value=0, base-type=BT_KY_Mehrere_Schluessel_aussen, compu {0=Cx0_keine_Indikation (CM_KY_Mehrere_Schluessel_aussen_Cx0_keine_Indikation), 1=Cx1_Mehrere_Schluessel_aussen_gefunden (CM_KY_Mehrere_Schluessel_aussen_Cx1_Mehrere_Schluessel_aussen_gefunden)}, range raw 0..1, transfer-property=TRIGGERED-WITHOUT-REPETITION  # Indikator, dass sich mehr als ein Schlüssel im Aussenbereich befindet
          signal FBS_MDK_in_Reichweite_XIX_KeylessAccess_01_XIX_HCP3_CANFD01: start 39, 1 bit, little-endian, data-type-policy=OVERRIDE, i-signal-type=PRIMITIVE, init-value=0, base-type=BT_FBS_MDK_in_Reichweite, compu {0=Cx0_ausser_Reichweite (CM_FBS_MDK_in_Reichweite_Cx0_ausser_Reichweite), 1=Cx1_innerhalb_Reichweite (CM_FBS_MDK_in_Reichweite_Cx1_innerhalb_Reichweite)}, range raw 0..1, transfer-property=TRIGGERED-WITHOUT-REPETITION  # Für elektrisch betätigte Türen und Klappen muss für eine Remote-Betätigung mittels MobileDeviceKey eine Reichweitenbegrenzung eingeführt werden. Dieses Bit zeigt an, dass sich der MobileDeviceKey innerhalb der geforderten Reichweite befindet
          signal KY_Fzg_Zugang_erkannt_XIX_KeylessAccess_01_XIX_HCP3_CANFD01: start 41, 1 bit, little-endian, data-type-policy=OVERRIDE, i-signal-type=PRIMITIVE, init-value=0, base-type=BT_KY_Fzg_Zugang_erkannt, compu {1=Cx1_erkannt (CM_KY_Fzg_Zugang_erkannt_Cx1_erkannt), 0=Cx0_nicht_erkannt (CM_KY_Fzg_Zugang_erkannt_Cx0_nicht_erkannt)}, range raw 0..1, transfer-property=TRIGGERED-WITHOUT-REPETITION  # Fahrer/Schlüssel hat Fahrzeug betreten und die FT geschlossen
          signal KY_HD_Auffahrt_XIX_KeylessAccess_01_XIX_HCP3_CANFD01: start 42, 1 bit, little-endian, data-type-policy=OVERRIDE, i-signal-type=PRIMITIVE, base-type=BT_KY_HD_Auffahrt, compu {0=Cx0_keine_Anforderung (CM_KY_HD_Auffahrt_Cx0_keine_Anforderung), 1=Cx1_HD_Auffahrt_angefordert (CM_KY_HD_Auffahrt_Cx1_HD_Auffahrt_angefordert)}, range raw 0..1, transfer-property=TRIGGERED-WITHOUT-REPETITION  # Auffahrt HD nach Wiedereintritt ID-Geber in EasyClose Nahbereich
          signal KY_HD_Zufahrt_XIX_KeylessAccess_01_XIX_HCP3_CANFD01: start 43, 1 bit, little-endian, data-type-policy=OVERRIDE, i-signal-type=PRIMITIVE, base-type=BT_KY_HD_Zufahrt, compu {1=Cx1_HD_Zufahrt_angefordert (CM_KY_HD_Zufahrt_Cx1_HD_Zufahrt_angefordert), 0=Cx0_keine_Anforderung (CM_KY_HD_Zufahrt_Cx0_keine_Anforderung)}, range raw 0..1, transfer-property=TRIGGERED-WITHOUT-REPETITION  # Zufahrt HD nach erfolgreicher Funktion EasyClose
          signal KY_EasyClose_Abbruch_XIX_KeylessAccess_01_XIX_HCP3_CANFD01: start 48, 1 bit, little-endian, data-type-policy=OVERRIDE, i-signal-type=PRIMITIVE, init-value=0, base-type=BT_KY_EasyClose_Abbruch, compu {1=Cx1_EasyClose_Abbruch (CM_KY_EasyClose_Abbruch_Cx1_EasyClose_Abbruch), 0=Cx0_EasyClose_kein_Abbruch (CM_KY_EasyClose_Abbruch_Cx0_EasyClose_kein_Abbruch)}, range raw 0..1, transfer-property=TRIGGERED-WITHOUT-REPETITION  # ID-Geber während HD-Zufahrt im Nahbereich EasyClose erkannt
          signal KY_EasyClose_Status_XIX_KeylessAccess_01_XIX_HCP3_CANFD01: start 49, 3 bit, little-endian, data-type-policy=OVERRIDE, i-signal-type=PRIMITIVE, init-value=0, base-type=BT_KY_EasyClose_Status, compu {2=Cx2_Lampe_NORMAL (CM_KY_EasyClose_Status_Cx2_Lampe_NORMAL), 1=Cx1_Lampe_EIN (CM_KY_EasyClose_Status_Cx1_Lampe_EIN), 4=Cx4_Akustik_Verweigerung (CM_KY_EasyClose_Status_Cx4_Akustik_Verweigerung), 0=Cx0_Lampe_AUS (CM_KY_EasyClose_Status_Cx0_Lampe_AUS), 3=Cx3_Lampe_HEKTIK (CM_KY_EasyClose_Status_Cx3_Lampe_HEKTIK)}, range raw 0..4, transfer-property=TRIGGERED-WITHOUT-REPETITION  # Signal zur LED Ansteuerung im HD-Verriegelungstaster für die Funktion EasyClose.
          signal KY_IDG_in_Reichweite_XIX_KeylessAccess_01_XIX_HCP3_CANFD01: start 54, 1 bit, little-endian, data-type-policy=OVERRIDE, i-signal-type=PRIMITIVE, init-value=0, base-type=BT_KY_IDG_in_Reichweite, compu {1=Cx1_innerhalb_Reichweite (CM_KY_IDG_in_Reichweite_Cx1_innerhalb_Reichweite), 0=Cx0_ausser_Reichweite_bzw_nicht_ermittelbar (CM_KY_IDG_in_Reichweite_Cx0_ausser_Reichweite_bzw_nicht_ermittelbar)}, range raw 0..1, transfer-property=TRIGGERED-WITHOUT-REPETITION  # Für elektrisch betätigte Türen und Klappen muss für eine Betätigung über Funk eine Reichweitenbegrenzung eingeführt werden. Diese Bit zeigt an, dass sich der Funkschlüssel innerhalb der geforderten Reichweite befindet
          signal KY_Indikator_Mehrere_Schluessel_XIX_KeylessAccess_01_XIX_HCP3_CANFD01: start 55, 1 bit, little-endian, data-type-policy=OVERRIDE, i-signal-type=PRIMITIVE, init-value=0, base-type=BT_KY_Indikator_Mehrere_Schluessel, compu {0=Cx0_Init (CM_KY_Indikator_Mehrere_Schluessel_Cx0_Init), 1=Cx1_Mehrere_Schluessel_im_Fahrzeug_gefunden (CM_KY_Indikator_Mehrere_Schluessel_Cx1_Mehrere_Schluessel_im_Fahrzeug_gefunden)}, range raw 0..1, transfer-property=TRIGGERED-WITHOUT-REPETITION  # Indikator für u.a. Sitzmemory, dass sich mehr als ein Schlüssel im Fahrzeug befinden.
          signal KY_ZV_Signatur_XIX_KeylessAccess_01_XIX_HCP3_CANFD01: start 56, 11 bit, little-endian, data-type-policy=OVERRIDE, i-signal-type=PRIMITIVE, init-value=0, base-type=BT_KY_ZV_Signatur, compu {phys=raw for raw 0..2047; unit Unit_None}, range phys 0..2047 Unit_None, raw 0..2047, unit=Unit_None, transfer-property=TRIGGERED-WITHOUT-REPETITION  # Signatur der ZV
          signal KY_Schluessel_im_Fzg_XIX_KeylessAccess_01_XIX_HCP3_CANFD01: start 67, 1 bit, little-endian, data-type-policy=OVERRIDE, i-signal-type=PRIMITIVE, base-type=BT_KY_Schluessel_im_Fzg, compu {0=Cx0_Schluessel_nicht_im_Fahrzeug (CM_KY_Schluessel_im_Fzg_Cx0_Schluessel_nicht_im_Fahrzeug), 1=Cx1_Schluessel_im_Fahrzeug (CM_KY_Schluessel_im_Fzg_Cx1_Schluessel_im_Fahrzeug)}, range raw 0..1, transfer-property=TRIGGERED-WITHOUT-REPETITION  # Zeigt einen erkannten Schlüssel im Fzg an.
          signal FBS_KSY_VIP_XIX_KeylessAccess_01_XIX_HCP3_CANFD01: start 75, 3 bit, little-endian, data-type-policy=OVERRIDE, i-signal-type=PRIMITIVE, init-value=0, base-type=BT_FBS_KSY_VIP, compu {6=Cx6_reserved (CM_FBS_KSY_VIP_Cx6_reserved), 0=Cx0_init (CM_FBS_KSY_VIP_Cx0_init), 2=Cx2_approach_valid (CM_FBS_KSY_VIP_Cx2_approach_valid), 4=Cx4_reserved (CM_FBS_KSY_VIP_Cx4_reserved), 5=Cx5_reserved (CM_FBS_KSY_VIP_Cx5_reserved), 7=Cx7_failure (CM_FBS_KSY_VIP_Cx7_failure), 1=Cx1_detection_valid (CM_FBS_KSY_VIP_Cx1_detection_valid), 3=Cx3_reserved (CM_FBS_KSY_VIP_Cx3_reserved)}, range raw 0..7, transfer-property=TRIGGERED-WITHOUT-REPETITION  # virtual pedal signalling
          signal FBS_KSY_easy_close2_XIX_KeylessAccess_01_XIX_HCP3_CANFD01: start 78, 2 bit, little-endian, data-type-policy=OVERRIDE, i-signal-type=PRIMITIVE, init-value=0, base-type=BT_FBS_KSY_easy_close2, compu {1=Cx1_tailgate_active_opening (CM_FBS_KSY_easy_close2_Cx1_tailgate_active_opening), 0=Cx0_init (CM_FBS_KSY_easy_close2_Cx0_init), 3=Cx3_reserved (CM_FBS_KSY_easy_close2_Cx3_reserved), 2=Cx2_tailgate_active_closing (CM_FBS_KSY_easy_close2_Cx2_tailgate_active_closing)}, range raw 0..3, transfer-property=TRIGGERED-WITHOUT-REPETITION  # HD_Zufahrt HD_Auffahrt
          signal FBS_KSY_adv_position_XIX_KeylessAccess_01_XIX_HCP3_CANFD01: start 86, 3 bit, little-endian, data-type-policy=OVERRIDE, i-signal-type=PRIMITIVE, init-value=0, base-type=BT_FBS_KSY_adv_position, compu {4=Cx4_position_3 (CM_FBS_KSY_adv_position_Cx4_position_3), 6=Cx6_reserved (CM_FBS_KSY_adv_position_Cx6_reserved), 5=Cx5_position_4 (CM_FBS_KSY_adv_position_Cx5_position_4), 3=Cx3_position_2 (CM_FBS_KSY_adv_position_Cx3_position_2), 2=Cx2_position_1 (CM_FBS_KSY_adv_position_Cx2_position_1), 7=Cx7_no_ID_found (CM_FBS_KSY_adv_position_Cx7_no_ID_found), 1=Cx1_position_0 (CM_FBS_KSY_adv_position_Cx1_position_0), 0=Cx0_Init (CM_FBS_KSY_adv_position_Cx0_Init)}, range raw 0..7, transfer-property=TRIGGERED-WITHOUT-REPETITION  # KY_Position
          signal FBS_KSY_adv_zone_XIX_KeylessAccess_01_XIX_HCP3_CANFD01: start 89, 3 bit, little-endian, data-type-policy=OVERRIDE, i-signal-type=PRIMITIVE, init-value=0, base-type=BT_FBS_KSY_adv_zone, compu {4=Cx4_zone_3 (CM_FBS_KSY_adv_zone_Cx4_zone_3), 1=Cx1_zone_0 (CM_FBS_KSY_adv_zone_Cx1_zone_0), 0=Cx0_Init (CM_FBS_KSY_adv_zone_Cx0_Init), 3=Cx3_zone_2 (CM_FBS_KSY_adv_zone_Cx3_zone_2), 7=Cx7_no_ID_found (CM_FBS_KSY_adv_zone_Cx7_no_ID_found), 5=Cx5_zone_4 (CM_FBS_KSY_adv_zone_Cx5_zone_4), 2=Cx2_zone_1 (CM_FBS_KSY_adv_zone_Cx2_zone_1), 6=Cx6_zone_5 (CM_FBS_KSY_adv_zone_Cx6_zone_5)}, range raw 0..7, transfer-property=TRIGGERED-WITHOUT-REPETITION  # KY_Bereich
          signal FBS_KSY_driver_warning_XIX_KeylessAccess_01_XIX_HCP3_CANFD01: start 92, 4 bit, little-endian, data-type-policy=OVERRIDE, i-signal-type=PRIMITIVE, init-value=0, base-type=BT_FBS_KSY_driver_warning, compu {9=Cx9_reserved (CM_FBS_KSY_driver_warning_Cx9_reserved), 12=Cxc_FBS_TxT_Warn_kein_Schluessel (CM_FBS_KSY_driver_warning_Cxc_FBS_TxT_Warn_kein_Schluessel), 15=Cxf_reserved (CM_FBS_KSY_driver_warning_Cxf_reserved), 0=Cx0_no_warning (CM_FBS_KSY_driver_warning_Cx0_no_warning), 3=Cx3_Schluessel_im_Kofferraum_gefund (CM_FBS_KSY_driver_warning_Cx3_Schluessel_im_Kofferraum_gefund), 4=Cx4_Start_Kein_Schluessel_erkannt (CM_FBS_KSY_driver_warning_Cx4_Start_Kein_Schluessel_erkannt), 5=Cx5_Start_Kein_Schluessel_oder_MDK (CM_FBS_KSY_driver_warning_Cx5_Start_Kein_Schluessel_oder_MDK), 6=Cx6_Warn_kein_MDK_erkannt (CM_FBS_KSY_driver_warning_Cx6_Warn_kein_MDK_erkannt), 14=Cxe_Warn_gueltiges_Keyless_kein_MDK (CM_FBS_KSY_driver_warning_Cxe_Warn_gueltiges_Keyless_kein_MDK), 1=Cx1_Zugang_Kein_Schluessel_erkannt (CM_FBS_KSY_driver_warning_Cx1_Zugang_Kein_Schluessel_erkannt), 8=Cx8_VIP_sensor_verschmutzt (CM_FBS_KSY_driver_warning_Cx8_VIP_sensor_verschmutzt), 13=Cxd_Warn_kein_Keyless_gueltiger_MDK (CM_FBS_KSY_driver_warning_Cxd_Warn_kein_Keyless_gueltiger_MDK), 2=Cx2_Schluessel_im_Innenraum_gefunden (CM_FBS_KSY_driver_warning_Cx2_Schluessel_im_Innenraum_gefunden), 7=Cx7_KL15_Keine_Autom_Aktivierung (CM_FBS_KSY_driver_warning_Cx7_KL15_Keine_Autom_Aktivierung), 10=Cxa_reserved (CM_FBS_KSY_driver_warning_Cxa_reserved), 11=Cxb_FBS_TxT_Warn_Schluessel_Batt (CM_FBS_KSY_driver_warning_Cxb_FBS_TxT_Warn_Schluessel_Batt)}, range raw 0..15, transfer-property=TRIGGERED-WITHOUT-REPETITION  # Kombi Fahrer Hinweise Keyless
          signal FBS_KSY_enable_park_XIX_KeylessAccess_01_XIX_HCP3_CANFD01: start 96, 2 bit, little-endian, data-type-policy=OVERRIDE, i-signal-type=PRIMITIVE, init-value=0, base-type=BT_FBS_KSY_enable_park, compu {1=Cx1_enable_piloted_parking (CM_FBS_KSY_enable_park_Cx1_enable_piloted_parking), 0=Cx0_Init (CM_FBS_KSY_enable_park_Cx0_Init)}, range raw 0..1, transfer-property=TRIGGERED-WITHOUT-REPETITION  # KY_Aktivierung_Pilot_Parken
          signal FBS_KSY_HF_XIX_KeylessAccess_01_XIX_HCP3_CANFD01: start 98, 3 bit, little-endian, data-type-policy=OVERRIDE, i-signal-type=PRIMITIVE, base-type=BT_FBS_KSY_HF, compu {2=Cx2_active_rx_ch2 (CM_FBS_KSY_HF_Cx2_active_rx_ch2), 0=Cx0_inactive (CM_FBS_KSY_HF_Cx0_inactive), 3=Cx3_active_rx_ch3 (CM_FBS_KSY_HF_Cx3_active_rx_ch3), 1=Cx1_active_rx_ch1 (CM_FBS_KSY_HF_Cx1_active_rx_ch1), 4=Cx4_active_tx_ch1 (CM_FBS_KSY_HF_Cx4_active_tx_ch1), 6=Cx6_active_tx_ch3 (CM_FBS_KSY_HF_Cx6_active_tx_ch3), 5=Cx5_active_tx_ch2 (CM_FBS_KSY_HF_Cx5_active_tx_ch2), 7=Cx7_reserved (CM_FBS_KSY_HF_Cx7_reserved) (-reserved-)}, range raw 0..7, transfer-property=TRIGGERED-WITHOUT-REPETITION  # HF active signalling
          signal FBS_KSY_HF_telegram_XIX_KeylessAccess_01_XIX_HCP3_CANFD01: start 101, 8 bit, little-endian, data-type-policy=OVERRIDE, i-signal-type=PRIMITIVE, base-type=BT_FBS_KSY_HF_telegram, compu {8=Cx8_valid_4 (CM_FBS_KSY_HF_telegram_Cx8_valid_4), 32=Cx20_valid_6 (CM_FBS_KSY_HF_telegram_Cx20_valid_6), 128=Cx80_valid_8 (CM_FBS_KSY_HF_telegram_Cx80_valid_8), 64=Cx40_valid_7 (CM_FBS_KSY_HF_telegram_Cx40_valid_7), 2=Cx2_valid_2 (CM_FBS_KSY_HF_telegram_Cx2_valid_2), 16=Cx10_valid_5 (CM_FBS_KSY_HF_telegram_Cx10_valid_5), 1=Cx1_valid_1 (CM_FBS_KSY_HF_telegram_Cx1_valid_1), 0=Cx0_inactive (CM_FBS_KSY_HF_telegram_Cx0_inactive), 4=Cx4_valid_3 (CM_FBS_KSY_HF_telegram_Cx4_valid_3)}, range raw 0..128, transfer-property=TRIGGERED-WITHOUT-REPETITION  # HF telegram status signalling
          signal FBS_KSY_ID_battery_XIX_KeylessAccess_01_XIX_HCP3_CANFD01: start 109, 3 bit, little-endian, data-type-policy=OVERRIDE, i-signal-type=PRIMITIVE, init-value=0, base-type=BT_FBS_KSY_ID_battery, compu {0=Cx0_init (CM_FBS_KSY_ID_battery_Cx0_init), 2=Cx2_battery_level_2 (CM_FBS_KSY_ID_battery_Cx2_battery_level_2), 5=Cx5_battery_level_5 (CM_FBS_KSY_ID_battery_Cx5_battery_level_5), 1=Cx1_battery_level_0_or_battery_level_1 (CM_FBS_KSY_ID_battery_Cx1_battery_level_0_or_battery_level_1) (battery_level_0 or battery_level_1), 6=Cx6_battery_level_6 (CM_FBS_KSY_ID_battery_Cx6_battery_level_6), 4=Cx4_battery_level_4 (CM_FBS_KSY_ID_battery_Cx4_battery_level_4), 3=Cx3_battery_level_3 (CM_FBS_KSY_ID_battery_Cx3_battery_level_3), 7=Cx7_battery_level_7 (CM_FBS_KSY_ID_battery_Cx7_battery_level_7)}, range raw 0..7, transfer-property=TRIGGERED-WITHOUT-REPETITION  # battery status of ID or remote key
          signal FBS_KSY_jobnumber_XIX_KeylessAccess_01_XIX_HCP3_CANFD01: start 112, 8 bit, little-endian, data-type-policy=OVERRIDE, i-signal-type=PRIMITIVE, base-type=BT_FBS_KSY_jobnumber, compu {69=Cx45_job_69 (CM_FBS_KSY_jobnumber_Cx45_job_69), 186=Cxba_job_186 (CM_FBS_KSY_jobnumber_Cxba_job_186), 60=Cx3c_job_60 (CM_FBS_KSY_jobnumber_Cx3c_job_60), 130=Cx82_job_130 (CM_FBS_KSY_jobnumber_Cx82_job_130), 99=Cx63_job_99 (CM_FBS_KSY_jobnumber_Cx63_job_99), 114=Cx72_job_114 (CM_FBS_KSY_jobnumber_Cx72_job_114), 109=Cx6d_job_109 (CM_FBS_KSY_jobnumber_Cx6d_job_109), 16=Cx10_job_16 (CM_FBS_KSY_jobnumber_Cx10_job_16), 221=Cxdd_job_221 (CM_FBS_KSY_jobnumber_Cxdd_job_221), 197=Cxc5_job_197 (CM_FBS_KSY_jobnumber_Cxc5_job_197), 190=Cxbe_job_190 (CM_FBS_KSY_jobnumber_Cxbe_job_190), 205=Cxcd_job_205 (CM_FBS_KSY_jobnumber_Cxcd_job_205), 128=Cx80_job_128 (CM_FBS_KSY_jobnumber_Cx80_job_128), 217=Cxd9_job_217 (CM_FBS_KSY_jobnumber_Cxd9_job_217), 244=Cxf4_job_244 (CM_FBS_KSY_jobnumber_Cxf4_job_244), 119=Cx77_job_119 (CM_FBS_KSY_jobnumber_Cx77_job_119), 209=Cxd1_job_209 (CM_FBS_KSY_jobnumber_Cxd1_job_209), 85=Cx55_job_85 (CM_FBS_KSY_jobnumber_Cx55_job_85), 232=Cxe8_job_232 (CM_FBS_KSY_jobnumber_Cxe8_job_232), 245=Cxf5_job_245 (CM_FBS_KSY_jobnumber_Cxf5_job_245), 138=Cx8a_job_138 (CM_FBS_KSY_jobnumber_Cx8a_job_138), 226=Cxe2_job_226 (CM_FBS_KSY_jobnumber_Cxe2_job_226), 175=Cxaf_job_175 (CM_FBS_KSY_jobnumber_Cxaf_job_175), 173=Cxad_job_173 (CM_FBS_KSY_jobnumber_Cxad_job_173), 240=Cxf0_job_240 (CM_FBS_KSY_jobnumber_Cxf0_job_240), 89=Cx59_job_89 (CM_FBS_KSY_jobnumber_Cx59_job_89), 24=Cx18_job_24 (CM_FBS_KSY_jobnumber_Cx18_job_24), 80=Cx50_job_80 (CM_FBS_KSY_jobnumber_Cx50_job_80), 48=Cx30_job_48 (CM_FBS_KSY_jobnumber_Cx30_job_48), 93=Cx5d_job_93 (CM_FBS_KSY_jobnumber_Cx5d_job_93), 135=Cx87_job_135 (CM_FBS_KSY_jobnumber_Cx87_job_135), 13=Cxd_job_13 (CM_FBS_KSY_jobnumber_Cxd_job_13), 255=Cxff_job_255 (CM_FBS_KSY_jobnumber_Cxff_job_255), 3=Cx3_job_3 (CM_FBS_KSY_jobnumber_Cx3_job_3), 66=Cx42_job_66 (CM_FBS_KSY_jobnumber_Cx42_job_66), 233=Cxe9_job_233 (CM_FBS_KSY_jobnumber_Cxe9_job_233), 108=Cx6c_job_108 (CM_FBS_KSY_jobnumber_Cx6c_job_108), 207=Cxcf_job_207 (CM_FBS_KSY_jobnumber_Cxcf_job_207), 5=Cx5_job_5 (CM_FBS_KSY_jobnumber_Cx5_job_5), 239=Cxef_job_239 (CM_FBS_KSY_jobnumber_Cxef_job_239), 63=Cx3f_job_63 (CM_FBS_KSY_jobnumber_Cx3f_job_63), 143=Cx8f_job_143 (CM_FBS_KSY_jobnumber_Cx8f_job_143), 43=Cx2b_job_43 (CM_FBS_KSY_jobnumber_Cx2b_job_43), 2=Cx2_job_2 (CM_FBS_KSY_jobnumber_Cx2_job_2), 95=Cx5f_job_95 (CM_FBS_KSY_jobnumber_Cx5f_job_95), 28=Cx1c_job_28 (CM_FBS_KSY_jobnumber_Cx1c_job_28), 140=Cx8c_job_140 (CM_FBS_KSY_jobnumber_Cx8c_job_140), 171=Cxab_job_171 (CM_FBS_KSY_jobnumber_Cxab_job_171), 51=Cx33_job_51 (CM_FBS_KSY_jobnumber_Cx33_job_51), 62=Cx3e_job_62 (CM_FBS_KSY_jobnumber_Cx3e_job_62), 167=Cxa7_job_167 (CM_FBS_KSY_jobnumber_Cxa7_job_167), 50=Cx32_job_50 (CM_FBS_KSY_jobnumber_Cx32_job_50), 248=Cxf8_job_248 (CM_FBS_KSY_jobnumber_Cxf8_job_248), 246=Cxf6_job_246 (CM_FBS_KSY_jobnumber_Cxf6_job_246), 98=Cx62_job_98 (CM_FBS_KSY_jobnumber_Cx62_job_98), 70=Cx46_job_70 (CM_FBS_KSY_jobnumber_Cx46_job_70), 160=Cxa0_job_160 (CM_FBS_KSY_jobnumber_Cxa0_job_160), 180=Cxb4_job_180 (CM_FBS_KSY_jobnumber_Cxb4_job_180), 176=Cxb0_job_176 (CM_FBS_KSY_jobnumber_Cxb0_job_176), 198=Cxc6_job_198 (CM_FBS_KSY_jobnumber_Cxc6_job_198), 9=Cx9_job_9 (CM_FBS_KSY_jobnumber_Cx9_job_9), 254=Cxfe_job_254 (CM_FBS_KSY_jobnumber_Cxfe_job_254), 225=Cxe1_job_225 (CM_FBS_KSY_jobnumber_Cxe1_job_225), 92=Cx5c_job_92 (CM_FBS_KSY_jobnumber_Cx5c_job_92), 193=Cxc1_job_193 (CM_FBS_KSY_jobnumber_Cxc1_job_193), 37=Cx25_job_37 (CM_FBS_KSY_jobnumber_Cx25_job_37), 54=Cx36_job_54 (CM_FBS_KSY_jobnumber_Cx36_job_54), 40=Cx28_job_40 (CM_FBS_KSY_jobnumber_Cx28_job_40), 241=Cxf1_job_241 (CM_FBS_KSY_jobnumber_Cxf1_job_241), 22=Cx16_job_22 (CM_FBS_KSY_jobnumber_Cx16_job_22), 79=Cx4f_job_79 (CM_FBS_KSY_jobnumber_Cx4f_job_79), 187=Cxbb_job_187 (CM_FBS_KSY_jobnumber_Cxbb_job_187), 194=Cxc2_job_194 (CM_FBS_KSY_jobnumber_Cxc2_job_194), 131=Cx83_job_131 (CM_FBS_KSY_jobnumber_Cx83_job_131), 35=Cx23_job_35 (CM_FBS_KSY_jobnumber_Cx23_job_35), 177=Cxb1_job_177 (CM_FBS_KSY_jobnumber_Cxb1_job_177), 44=Cx2c_job_44 (CM_FBS_KSY_jobnumber_Cx2c_job_44), 189=Cxbd_job_189 (CM_FBS_KSY_jobnumber_Cxbd_job_189), 77=Cx4d_job_77 (CM_FBS_KSY_jobnumber_Cx4d_job_77), 61=Cx3d_job_61 (CM_FBS_KSY_jobnumber_Cx3d_job_61), 15=Cxf_job_15 (CM_FBS_KSY_jobnumber_Cxf_job_15), 196=Cxc4_job_196 (CM_FBS_KSY_jobnumber_Cxc4_job_196), 20=Cx14_job_20 (CM_FBS_KSY_jobnumber_Cx14_job_20), 147=Cx93_job_147 (CM_FBS_KSY_jobnumber_Cx93_job_147), 116=Cx74_job_116 (CM_FBS_KSY_jobnumber_Cx74_job_116), 26=Cx1a_job_26 (CM_FBS_KSY_jobnumber_Cx1a_job_26), 101=Cx65_job_101 (CM_FBS_KSY_jobnumber_Cx65_job_101), 215=Cxd7_job_215 (CM_FBS_KSY_jobnumber_Cxd7_job_215), 71=Cx47_job_71 (CM_FBS_KSY_jobnumber_Cx47_job_71), 238=Cxee_job_238 (CM_FBS_KSY_jobnumber_Cxee_job_238), 117=Cx75_job_117 (CM_FBS_KSY_jobnumber_Cx75_job_117), 123=Cx7b_job_123 (CM_FBS_KSY_jobnumber_Cx7b_job_123), 110=Cx6e_job_110 (CM_FBS_KSY_jobnumber_Cx6e_job_110), 154=Cx9a_job_154 (CM_FBS_KSY_jobnumber_Cx9a_job_154), 206=Cxce_job_206 (CM_FBS_KSY_jobnumber_Cxce_job_206), 192=Cxc0_job_192 (CM_FBS_KSY_jobnumber_Cxc0_job_192), 73=Cx49_job_73 (CM_FBS_KSY_jobnumber_Cx49_job_73), 84=Cx54_job_84 (CM_FBS_KSY_jobnumber_Cx54_job_84), 243=Cxf3_job_243 (CM_FBS_KSY_jobnumber_Cxf3_job_243), 29=Cx1d_job_29 (CM_FBS_KSY_jobnumber_Cx1d_job_29), 94=Cx5e_job_94 (CM_FBS_KSY_jobnumber_Cx5e_job_94), 172=Cxac_job_172 (CM_FBS_KSY_jobnumber_Cxac_job_172), 251=Cxfb_job_251 (CM_FBS_KSY_jobnumber_Cxfb_job_251), 134=Cx86_job_134 (CM_FBS_KSY_jobnumber_Cx86_job_134), 31=Cx1f_job_31 (CM_FBS_KSY_jobnumber_Cx1f_job_31), 155=Cx9b_job_155 (CM_FBS_KSY_jobnumber_Cx9b_job_155), 200=Cxc8_job_200 (CM_FBS_KSY_jobnumber_Cxc8_job_200), 97=Cx61_job_97 (CM_FBS_KSY_jobnumber_Cx61_job_97), 144=Cx90_job_144 (CM_FBS_KSY_jobnumber_Cx90_job_144), 113=Cx71_job_113 (CM_FBS_KSY_jobnumber_Cx71_job_113), 120=Cx78_job_120 (CM_FBS_KSY_jobnumber_Cx78_job_120), 34=Cx22_job_34 (CM_FBS_KSY_jobnumber_Cx22_job_34), 169=Cxa9_job_169 (CM_FBS_KSY_jobnumber_Cxa9_job_169), 87=Cx57_job_87 (CM_FBS_KSY_jobnumber_Cx57_job_87), 156=Cx9c_job_156 (CM_FBS_KSY_jobnumber_Cx9c_job_156), 178=Cxb2_job_178 (CM_FBS_KSY_jobnumber_Cxb2_job_178), 42=Cx2a_job_42 (CM_FBS_KSY_jobnumber_Cx2a_job_42), 220=Cxdc_job_220 (CM_FBS_KSY_jobnumber_Cxdc_job_220), 49=Cx31_job_49 (CM_FBS_KSY_jobnumber_Cx31_job_49), 142=Cx8e_job_142 (CM_FBS_KSY_jobnumber_Cx8e_job_142), 12=Cxc_job_12 (CM_FBS_KSY_jobnumber_Cxc_job_12), 41=Cx29_job_41 (CM_FBS_KSY_jobnumber_Cx29_job_41), 102=Cx66_job_102 (CM_FBS_KSY_jobnumber_Cx66_job_102), 56=Cx38_job_56 (CM_FBS_KSY_jobnumber_Cx38_job_56), 211=Cxd3_job_211 (CM_FBS_KSY_jobnumber_Cxd3_job_211), 150=Cx96_job_150 (CM_FBS_KSY_jobnumber_Cx96_job_150), 185=Cxb9_job_185 (CM_FBS_KSY_jobnumber_Cxb9_job_185), 129=Cx81_job_129 (CM_FBS_KSY_jobnumber_Cx81_job_129), 72=Cx48_job_72 (CM_FBS_KSY_jobnumber_Cx48_job_72), 58=Cx3a_job_58 (CM_FBS_KSY_jobnumber_Cx3a_job_58), 7=Cx7_job_7 (CM_FBS_KSY_jobnumber_Cx7_job_7), 191=Cxbf_job_191 (CM_FBS_KSY_jobnumber_Cxbf_job_191), 199=Cxc7_job_199 (CM_FBS_KSY_jobnumber_Cxc7_job_199), 19=Cx13_job_19 (CM_FBS_KSY_jobnumber_Cx13_job_19), 170=Cxaa_job_170 (CM_FBS_KSY_jobnumber_Cxaa_job_170), 65=Cx41_job_65 (CM_FBS_KSY_jobnumber_Cx41_job_65), 18=Cx12_job_18 (CM_FBS_KSY_jobnumber_Cx12_job_18), 126=Cx7e_job_126 (CM_FBS_KSY_jobnumber_Cx7e_job_126), 237=Cxed_job_237 (CM_FBS_KSY_jobnumber_Cxed_job_237), 124=Cx7c_job_124 (CM_FBS_KSY_jobnumber_Cx7c_job_124), 30=Cx1e_job_30 (CM_FBS_KSY_jobnumber_Cx1e_job_30), 45=Cx2d_job_45 (CM_FBS_KSY_jobnumber_Cx2d_job_45), 202=Cxca_job_202 (CM_FBS_KSY_jobnumber_Cxca_job_202), 166=Cxa6_job_166 (CM_FBS_KSY_jobnumber_Cxa6_job_166), 164=Cxa4_job_164 (CM_FBS_KSY_jobnumber_Cxa4_job_164), 27=Cx1b_job_27 (CM_FBS_KSY_jobnumber_Cx1b_job_27), 104=Cx68_job_104 (CM_FBS_KSY_jobnumber_Cx68_job_104), 234=Cxea_job_234 (CM_FBS_KSY_jobnumber_Cxea_job_234), 214=Cxd6_job_214 (CM_FBS_KSY_jobnumber_Cxd6_job_214), 118=Cx76_job_118 (CM_FBS_KSY_jobnumber_Cx76_job_118), 179=Cxb3_job_179 (CM_FBS_KSY_jobnumber_Cxb3_job_179), 82=Cx52_job_82 (CM_FBS_KSY_jobnumber_Cx52_job_82), 91=Cx5b_job_91 (CM_FBS_KSY_jobnumber_Cx5b_job_91), 1=Cx1_job_1 (CM_FBS_KSY_jobnumber_Cx1_job_1), 157=Cx9d_job_157 (CM_FBS_KSY_jobnumber_Cx9d_job_157), 203=Cxcb_job_203 (CM_FBS_KSY_jobnumber_Cxcb_job_203), 249=Cxf9_job_249 (CM_FBS_KSY_jobnumber_Cxf9_job_249), 231=Cxe7_job_231 (CM_FBS_KSY_jobnumber_Cxe7_job_231), 227=Cxe3_job_227 (CM_FBS_KSY_jobnumber_Cxe3_job_227), 223=Cxdf_job_223 (CM_FBS_KSY_jobnumber_Cxdf_job_223), 0=Cx0_inactive (CM_FBS_KSY_jobnumber_Cx0_inactive), 47=Cx2f_job_47 (CM_FBS_KSY_jobnumber_Cx2f_job_47), 57=Cx39_job_57 (CM_FBS_KSY_jobnumber_Cx39_job_57), 188=Cxbc_job_188 (CM_FBS_KSY_jobnumber_Cxbc_job_188), 159=Cx9f_job_159 (CM_FBS_KSY_jobnumber_Cx9f_job_159), 88=Cx58_job_88 (CM_FBS_KSY_jobnumber_Cx58_job_88), 105=Cx69_job_105 (CM_FBS_KSY_jobnumber_Cx69_job_105), 158=Cx9e_job_158 (CM_FBS_KSY_jobnumber_Cx9e_job_158), 96=Cx60_job_96 (CM_FBS_KSY_jobnumber_Cx60_job_96), 125=Cx7d_job_125 (CM_FBS_KSY_jobnumber_Cx7d_job_125), 81=Cx51_job_81 (CM_FBS_KSY_jobnumber_Cx51_job_81), 165=Cxa5_job_165 (CM_FBS_KSY_jobnumber_Cxa5_job_165), 103=Cx67_job_103 (CM_FBS_KSY_jobnumber_Cx67_job_103), 74=Cx4a_job_74 (CM_FBS_KSY_jobnumber_Cx4a_job_74), 242=Cxf2_job_242 (CM_FBS_KSY_jobnumber_Cxf2_job_242), 8=Cx8_job_8 (CM_FBS_KSY_jobnumber_Cx8_job_8), 152=Cx98_job_152 (CM_FBS_KSY_jobnumber_Cx98_job_152), 168=Cxa8_job_168 (CM_FBS_KSY_jobnumber_Cxa8_job_168), 112=Cx70_job_112 (CM_FBS_KSY_jobnumber_Cx70_job_112), 136=Cx88_job_136 (CM_FBS_KSY_jobnumber_Cx88_job_136), 174=Cxae_job_174 (CM_FBS_KSY_jobnumber_Cxae_job_174), 106=Cx6a_job_106 (CM_FBS_KSY_jobnumber_Cx6a_job_106), 133=Cx85_job_133 (CM_FBS_KSY_jobnumber_Cx85_job_133), 115=Cx73_job_115 (CM_FBS_KSY_jobnumber_Cx73_job_115), 4=Cx4_job_4 (CM_FBS_KSY_jobnumber_Cx4_job_4), 83=Cx53_job_83 (CM_FBS_KSY_jobnumber_Cx53_job_83), 75=Cx4b_job_75 (CM_FBS_KSY_jobnumber_Cx4b_job_75), 111=Cx6f_job_111 (CM_FBS_KSY_jobnumber_Cx6f_job_111), 46=Cx2e_job_46 (CM_FBS_KSY_jobnumber_Cx2e_job_46), 218=Cxda_job_218 (CM_FBS_KSY_jobnumber_Cxda_job_218), 195=Cxc3_job_195 (CM_FBS_KSY_jobnumber_Cxc3_job_195), 10=Cxa_job_10 (CM_FBS_KSY_jobnumber_Cxa_job_10), 121=Cx79_job_121 (CM_FBS_KSY_jobnumber_Cx79_job_121), 86=Cx56_job_86 (CM_FBS_KSY_jobnumber_Cx56_job_86), 17=Cx11_job_17 (CM_FBS_KSY_jobnumber_Cx11_job_17), 39=Cx27_job_39 (CM_FBS_KSY_jobnumber_Cx27_job_39), 33=Cx21_job_33 (CM_FBS_KSY_jobnumber_Cx21_job_33), 53=Cx35_job_53 (CM_FBS_KSY_jobnumber_Cx35_job_53), 14=Cxe_job_14 (CM_FBS_KSY_jobnumber_Cxe_job_14), 235=Cxeb_job_235 (CM_FBS_KSY_jobnumber_Cxeb_job_235), 148=Cx94_job_148 (CM_FBS_KSY_jobnumber_Cx94_job_148), 52=Cx34_job_52 (CM_FBS_KSY_jobnumber_Cx34_job_52), 250=Cxfa_job_250 (CM_FBS_KSY_jobnumber_Cxfa_job_250), 38=Cx26_job_38 (CM_FBS_KSY_jobnumber_Cx26_job_38), 212=Cxd4_job_212 (CM_FBS_KSY_jobnumber_Cxd4_job_212), 107=Cx6b_job_107 (CM_FBS_KSY_jobnumber_Cx6b_job_107), 219=Cxdb_job_219 (CM_FBS_KSY_jobnumber_Cxdb_job_219), 253=Cxfd_job_253 (CM_FBS_KSY_jobnumber_Cxfd_job_253), 208=Cxd0_job_208 (CM_FBS_KSY_jobnumber_Cxd0_job_208), 163=Cxa3_job_163 (CM_FBS_KSY_jobnumber_Cxa3_job_163), 76=Cx4c_job_76 (CM_FBS_KSY_jobnumber_Cx4c_job_76), 146=Cx92_job_146 (CM_FBS_KSY_jobnumber_Cx92_job_146), 229=Cxe5_job_229 (CM_FBS_KSY_jobnumber_Cxe5_job_229), 32=Cx20_job_32 (CM_FBS_KSY_jobnumber_Cx20_job_32), 11=Cxb_job_11 (CM_FBS_KSY_jobnumber_Cxb_job_11), 122=Cx7a_job_122 (CM_FBS_KSY_jobnumber_Cx7a_job_122), 149=Cx95_job_149 (CM_FBS_KSY_jobnumber_Cx95_job_149), 68=Cx44_job_68 (CM_FBS_KSY_jobnumber_Cx44_job_68), 100=Cx64_job_100 (CM_FBS_KSY_jobnumber_Cx64_job_100), 6=Cx6_job_6 (CM_FBS_KSY_jobnumber_Cx6_job_6), 184=Cxb8_job_184 (CM_FBS_KSY_jobnumber_Cxb8_job_184), 78=Cx4e_job_78 (CM_FBS_KSY_jobnumber_Cx4e_job_78), 162=Cxa2_job_162 (CM_FBS_KSY_jobnumber_Cxa2_job_162), 21=Cx15_job_21 (CM_FBS_KSY_jobnumber_Cx15_job_21), 228=Cxe4_job_228 (CM_FBS_KSY_jobnumber_Cxe4_job_228), 25=Cx19_job_25 (CM_FBS_KSY_jobnumber_Cx19_job_25), 141=Cx8d_job_141 (CM_FBS_KSY_jobnumber_Cx8d_job_141), 210=Cxd2_job_210 (CM_FBS_KSY_jobnumber_Cxd2_job_210), 224=Cxe0_job_224 (CM_FBS_KSY_jobnumber_Cxe0_job_224), 55=Cx37_job_55 (CM_FBS_KSY_jobnumber_Cx37_job_55), 161=Cxa1_job_161 (CM_FBS_KSY_jobnumber_Cxa1_job_161), 145=Cx91_job_145 (CM_FBS_KSY_jobnumber_Cx91_job_145), 90=Cx5a_job_90 (CM_FBS_KSY_jobnumber_Cx5a_job_90), 67=Cx43_job_67 (CM_FBS_KSY_jobnumber_Cx43_job_67), 222=Cxde_job_222 (CM_FBS_KSY_jobnumber_Cxde_job_222), 213=Cxd5_job_213 (CM_FBS_KSY_jobnumber_Cxd5_job_213), 23=Cx17_job_23 (CM_FBS_KSY_jobnumber_Cx17_job_23), 127=Cx7f_job_127 (CM_FBS_KSY_jobnumber_Cx7f_job_127), 132=Cx84_job_132 (CM_FBS_KSY_jobnumber_Cx84_job_132), 181=Cxb5_job_181 (CM_FBS_KSY_jobnumber_Cxb5_job_181), 64=Cx40_job_64 (CM_FBS_KSY_jobnumber_Cx40_job_64), 183=Cxb7_job_183 (CM_FBS_KSY_jobnumber_Cxb7_job_183), 36=Cx24_job_36 (CM_FBS_KSY_jobnumber_Cx24_job_36), 137=Cx89_job_137 (CM_FBS_KSY_jobnumber_Cx89_job_137), 216=Cxd8_job_216 (CM_FBS_KSY_jobnumber_Cxd8_job_216), 59=Cx3b_job_59 (CM_FBS_KSY_jobnumber_Cx3b_job_59), 153=Cx99_job_153 (CM_FBS_KSY_jobnumber_Cx99_job_153), 139=Cx8b_job_139 (CM_FBS_KSY_jobnumber_Cx8b_job_139), 201=Cxc9_job_201 (CM_FBS_KSY_jobnumber_Cxc9_job_201), 230=Cxe6_job_230 (CM_FBS_KSY_jobnumber_Cxe6_job_230), 151=Cx97_job_151 (CM_FBS_KSY_jobnumber_Cx97_job_151), 204=Cxcc_job_204 (CM_FBS_KSY_jobnumber_Cxcc_job_204), 247=Cxf7_job_247 (CM_FBS_KSY_jobnumber_Cxf7_job_247), 182=Cxb6_job_182 (CM_FBS_KSY_jobnumber_Cxb6_job_182), 252=Cxfc_job_252 (CM_FBS_KSY_jobnumber_Cxfc_job_252), 236=Cxec_job_236 (CM_FBS_KSY_jobnumber_Cxec_job_236)}, range raw 0..255, transfer-property=TRIGGERED-WITHOUT-REPETITION  # FBS job signalling
          signal FBS_KSY_LF_XIX_KeylessAccess_01_XIX_HCP3_CANFD01: start 120, 3 bit, little-endian, data-type-policy=OVERRIDE, i-signal-type=PRIMITIVE, init-value=0, base-type=BT_FBS_KSY_LF, compu {1=Cx1_active_LF (CM_FBS_KSY_LF_Cx1_active_LF), 3=Cx3_active_immo_LM (CM_FBS_KSY_LF_Cx3_active_immo_LM), 0=Cx0_inactive (CM_FBS_KSY_LF_Cx0_inactive), 2=Cx2_active_immo_CnT (CM_FBS_KSY_LF_Cx2_active_immo_CnT)}, range raw 0..3, transfer-property=TRIGGERED-WITHOUT-REPETITION  # LF active signalling
          signal FBS_KSY_lock_sensor_auth_XIX_KeylessAccess_01_XIX_HCP3_CANFD01: start 123, 4 bit, little-endian, data-type-policy=OVERRIDE, i-signal-type=PRIMITIVE, init-value=0, base-type=BT_FBS_KSY_lock_sensor_auth, compu {8=Cx8_charge_terminal2_lock_auth (CM_FBS_KSY_lock_sensor_auth_Cx8_charge_terminal2_lock_auth), 4=Cx4_RCDD_lock_authorized (CM_FBS_KSY_lock_sensor_auth_Cx4_RCDD_lock_authorized), 14=Cxe_ctrl_F_authorized (CM_FBS_KSY_lock_sensor_auth_Cxe_ctrl_F_authorized), 9=Cx9_ctrl_A_authorized (CM_FBS_KSY_lock_sensor_auth_Cx9_ctrl_A_authorized), 0=Cx0_no_lock_authorized (CM_FBS_KSY_lock_sensor_auth_Cx0_no_lock_authorized), 5=Cx5_rear_trunk_lock_authorized (CM_FBS_KSY_lock_sensor_auth_Cx5_rear_trunk_lock_authorized), 13=Cxd_ctrl_E_authorized (CM_FBS_KSY_lock_sensor_auth_Cxd_ctrl_E_authorized), 6=Cx6_front_trunk_lock_authorized (CM_FBS_KSY_lock_sensor_auth_Cx6_front_trunk_lock_authorized), 7=Cx7_charge_terminal1_lock_auth (CM_FBS_KSY_lock_sensor_auth_Cx7_charge_terminal1_lock_auth), 2=Cx2_CDD_lock_authorized (CM_FBS_KSY_lock_sensor_auth_Cx2_CDD_lock_authorized), 1=Cx1_DD_lock_authorized (CM_FBS_KSY_lock_sensor_auth_Cx1_DD_lock_authorized), 12=Cxc_ctrl_D_authorized (CM_FBS_KSY_lock_sensor_auth_Cxc_ctrl_D_authorized), 15=Cxf_ctrl_G_authorized (CM_FBS_KSY_lock_sensor_auth_Cxf_ctrl_G_authorized), 11=Cxb_ctrl_C_authorized (CM_FBS_KSY_lock_sensor_auth_Cxb_ctrl_C_authorized), 3=Cx3_RDD_lock_authorized (CM_FBS_KSY_lock_sensor_auth_Cx3_RDD_lock_authorized), 10=Cxa_ctrl_B_authorized (CM_FBS_KSY_lock_sensor_auth_Cxa_ctrl_B_authorized)}, range raw 0..15, transfer-property=TRIGGERED-WITHOUT-REPETITION  # Autorisierung einer Verriegelung an Keyless-Bedienstelle
          signal FBS_KSY_lock_sensor_prox_XIX_KeylessAccess_01_XIX_HCP3_CANFD01: start 127, 4 bit, little-endian, data-type-policy=OVERRIDE, i-signal-type=PRIMITIVE, init-value=0, base-type=BT_FBS_KSY_lock_sensor_prox, compu {4=Cx4_RCDD_lock_prox (CM_FBS_KSY_lock_sensor_prox_Cx4_RCDD_lock_prox), 3=Cx3_RDD_lock_prox (CM_FBS_KSY_lock_sensor_prox_Cx3_RDD_lock_prox), 6=Cx6_front_trunk_lock_prox (CM_FBS_KSY_lock_sensor_prox_Cx6_front_trunk_lock_prox), 15=Cxf_ctrl_G_prox (CM_FBS_KSY_lock_sensor_prox_Cxf_ctrl_G_prox), 14=Cxe_ctrl_F_prox (CM_FBS_KSY_lock_sensor_prox_Cxe_ctrl_F_prox), 5=Cx5_rear_trunk_lock_prox (CM_FBS_KSY_lock_sensor_prox_Cx5_rear_trunk_lock_prox), 11=Cxb_ctrl_C_prox (CM_FBS_KSY_lock_sensor_prox_Cxb_ctrl_C_prox), 10=Cxa_ctrl_B_prox (CM_FBS_KSY_lock_sensor_prox_Cxa_ctrl_B_prox), 12=Cxc_ctrl_D_prox (CM_FBS_KSY_lock_sensor_prox_Cxc_ctrl_D_prox), 2=Cx2_CDD_lock_prox (CM_FBS_KSY_lock_sensor_prox_Cx2_CDD_lock_prox), 9=Cx9_ctrl_A_prox (CM_FBS_KSY_lock_sensor_prox_Cx9_ctrl_A_prox), 1=Cx1_DD_lock_prox (CM_FBS_KSY_lock_sensor_prox_Cx1_DD_lock_prox), 0=Cx0_no_lock_prox (CM_FBS_KSY_lock_sensor_prox_Cx0_no_lock_prox), 13=Cxd_ctrl_E_prox (CM_FBS_KSY_lock_sensor_prox_Cxd_ctrl_E_prox), 7=Cx7_charge_terminal_1_lock_prox (CM_FBS_KSY_lock_sensor_prox_Cx7_charge_terminal_1_lock_prox), 8=Cx8_charge_terminal_2_lock_prox (CM_FBS_KSY_lock_sensor_prox_Cx8_charge_terminal_2_lock_prox)}, range raw 0..15, transfer-property=TRIGGERED-WITHOUT-REPETITION  # lock sensor approximation detected
          signal FBS_KSY_unlock_sensor_auth_XIX_KeylessAccess_01_XIX_HCP3_CANFD01: start 131, 4 bit, little-endian, data-type-policy=OVERRIDE, i-signal-type=PRIMITIVE, init-value=0, base-type=BT_FBS_KSY_unlock_sensor_auth, compu {7=Cx7_charge_terminal1_unlock_auth (CM_FBS_KSY_unlock_sensor_auth_Cx7_charge_terminal1_unlock_auth), 11=Cxb_ctrl_C_authorized (CM_FBS_KSY_unlock_sensor_auth_Cxb_ctrl_C_authorized), 12=Cxc_ctrl_D_authorized (CM_FBS_KSY_unlock_sensor_auth_Cxc_ctrl_D_authorized), 2=Cx2_CDD_unlock_authorized (CM_FBS_KSY_unlock_sensor_auth_Cx2_CDD_unlock_authorized), 14=Cxe_ctrl_F_authorized (CM_FBS_KSY_unlock_sensor_auth_Cxe_ctrl_F_authorized), 10=Cxa_ctrl_B_authorized (CM_FBS_KSY_unlock_sensor_auth_Cxa_ctrl_B_authorized), 5=Cx5_rear_trunk_unlock_authorized (CM_FBS_KSY_unlock_sensor_auth_Cx5_rear_trunk_unlock_authorized), 13=Cxd_ctrl_E_authorized (CM_FBS_KSY_unlock_sensor_auth_Cxd_ctrl_E_authorized), 8=Cx8_charge_terminal2_unlock_auth (CM_FBS_KSY_unlock_sensor_auth_Cx8_charge_terminal2_unlock_auth), 6=Cx6_front_trunk_unlock_authorized (CM_FBS_KSY_unlock_sensor_auth_Cx6_front_trunk_unlock_authorized), 4=Cx4_RCDD_unlock_authorized (CM_FBS_KSY_unlock_sensor_auth_Cx4_RCDD_unlock_authorized), 0=Cx0_no_unlock_authorized (CM_FBS_KSY_unlock_sensor_auth_Cx0_no_unlock_authorized), 1=Cx1_DD_unlock_authorized (CM_FBS_KSY_unlock_sensor_auth_Cx1_DD_unlock_authorized), 15=Cxf_ctrl_G_authorized (CM_FBS_KSY_unlock_sensor_auth_Cxf_ctrl_G_authorized), 9=Cx9_ctrl_A_authorized (CM_FBS_KSY_unlock_sensor_auth_Cx9_ctrl_A_authorized), 3=Cx3_RDD_unlock_authorized (CM_FBS_KSY_unlock_sensor_auth_Cx3_RDD_unlock_authorized)}, range raw 0..15, transfer-property=TRIGGERED-WITHOUT-REPETITION  # Autorisierung einer Entriegelung an Keyless-Bedienstelle
          signal FBS_KSY_unlock_sensor_prox_XIX_KeylessAccess_01_XIX_HCP3_CANFD01: start 135, 4 bit, little-endian, data-type-policy=OVERRIDE, i-signal-type=PRIMITIVE, init-value=0, base-type=BT_FBS_KSY_unlock_sensor_prox, compu {7=Cx7_charge_terminal_1_unlock_prox (CM_FBS_KSY_unlock_sensor_prox_Cx7_charge_terminal_1_unlock_prox), 14=Cxe_ctrl_F_prox (CM_FBS_KSY_unlock_sensor_prox_Cxe_ctrl_F_prox), 11=Cxb_ctrl_C_prox (CM_FBS_KSY_unlock_sensor_prox_Cxb_ctrl_C_prox), 8=Cx8_charge_terminal_2_unlock_prox (CM_FBS_KSY_unlock_sensor_prox_Cx8_charge_terminal_2_unlock_prox), 0=Cx0_no_unlock_prox (CM_FBS_KSY_unlock_sensor_prox_Cx0_no_unlock_prox), 2=Cx2_CDD_unlock_prox (CM_FBS_KSY_unlock_sensor_prox_Cx2_CDD_unlock_prox), 9=Cx9_ctrl_A_prox (CM_FBS_KSY_unlock_sensor_prox_Cx9_ctrl_A_prox), 15=Cxf_ctrl_G_prox (CM_FBS_KSY_unlock_sensor_prox_Cxf_ctrl_G_prox), 3=Cx3_RDD_unlock_prox (CM_FBS_KSY_unlock_sensor_prox_Cx3_RDD_unlock_prox), 6=Cx6_front_trunk_unlock_prox (CM_FBS_KSY_unlock_sensor_prox_Cx6_front_trunk_unlock_prox), 4=Cx4_RCDD_unlock_prox (CM_FBS_KSY_unlock_sensor_prox_Cx4_RCDD_unlock_prox), 1=Cx1_DD_unlock_prox (CM_FBS_KSY_unlock_sensor_prox_Cx1_DD_unlock_prox), 5=Cx5_rear_trunk_unlock_prox (CM_FBS_KSY_unlock_sensor_prox_Cx5_rear_trunk_unlock_prox), 13=Cxd_ctrl_E_prox (CM_FBS_KSY_unlock_sensor_prox_Cxd_ctrl_E_prox), 12=Cxc_ctrl_D_prox (CM_FBS_KSY_unlock_sensor_prox_Cxc_ctrl_D_prox), 10=Cxa_ctrl_B_prox (CM_FBS_KSY_unlock_sensor_prox_Cxa_ctrl_B_prox)}, range raw 0..15, transfer-property=TRIGGERED-WITHOUT-REPETITION  # unlock sensor approximation detected
          signal FBS_KSY_UWB_range_XIX_KeylessAccess_01_XIX_HCP3_CANFD01: start 139, 8 bit, little-endian, data-type-policy=OVERRIDE, i-signal-type=PRIMITIVE, init-value=0, base-type=BT_FBS_KSY_UWB_range, compu {phys=raw*0.1 for raw 0..255; unit Unit_Meter}, range phys 0..25.5 Unit_Meter, raw 0..255, unit=Unit_Meter, transfer-property=TRIGGERED-WITHOUT-REPETITION  # range result in decimeter.
          signal FBS_RKE_button_XIX_KeylessAccess_01_XIX_HCP3_CANFD01: start 147, 8 bit, little-endian, data-type-policy=OVERRIDE, i-signal-type=PRIMITIVE, init-value=0, base-type=BT_FBS_RKE_button, compu {0=Cx0_no_button_pressed (CM_FBS_RKE_button_Cx0_no_button_pressed), 8=Cx8_front_trunk_pressed (CM_FBS_RKE_button_Cx8_front_trunk_pressed), 2=Cx2_lock_pressed (CM_FBS_RKE_button_Cx2_lock_pressed), 32=Cx20_joker_pressed (CM_FBS_RKE_button_Cx20_joker_pressed), 4=Cx4_rear_trunk_pressed (CM_FBS_RKE_button_Cx4_rear_trunk_pressed), 64=Cx40_park_pressed (CM_FBS_RKE_button_Cx40_park_pressed), 128=Cx80_remotestart_pressed (CM_FBS_RKE_button_Cx80_remotestart_pressed), 1=Cx1_unlock_pressed (CM_FBS_RKE_button_Cx1_unlock_pressed), 16=Cx10_panic_pressed (CM_FBS_RKE_button_Cx10_panic_pressed)}, range raw 0..128, transfer-property=TRIGGERED-WITHOUT-REPETITION  # button pressed signalling of ID or key fob device
          signal KY_Position_XIX_KeylessAccess_01_XIX_HCP3_CANFD01: start 159, 3 bit, little-endian, data-type-policy=OVERRIDE, i-signal-type=PRIMITIVE, init-value=0, base-type=BT_KY_Position, compu {6=Cx6_Kein_Schluessel_gefunden (CM_KY_Position_Cx6_Kein_Schluessel_gefunden), 0=Cx0_Position_0 (CM_KY_Position_Cx0_Position_0), 1=Cx1_Postition_1 (CM_KY_Position_Cx1_Postition_1), 2=Cx2_Postition_2 (CM_KY_Position_Cx2_Postition_2), 7=Cx7_Init (CM_KY_Position_Cx7_Init), 4=Cx4_Postition_4 (CM_KY_Position_Cx4_Postition_4), 3=Cx3_Postition_3 (CM_KY_Position_Cx3_Postition_3)}, range raw 0..7, transfer-property=TRIGGERED-WITHOUT-REPETITION  # Schlüsselposition für Funktionen Annäherungslicht, automatisches Entriegeln
          signal VIP_Sensor_betaetigt_XIX_KeylessAccess_01_XIX_HCP3_CANFD01: start 162, 1 bit, little-endian, data-type-policy=OVERRIDE, i-signal-type=PRIMITIVE, init-value=0, base-type=BT_VIP_Sensor_betaetigt, compu {0=Cx0_Heckentr_VIP_nicht_angefordert (CM_VIP_Sensor_betaetigt_Cx0_Heckentr_VIP_nicht_angefordert), 1=Cx1_Heckentr_VIP_angefordert (CM_VIP_Sensor_betaetigt_Cx1_Heckentr_VIP_angefordert)}, range raw 0..1, transfer-property=TRIGGERED-WITHOUT-REPETITION  # Heckentriegelung durch die Bedienstelle Virtuelles Pedal(VIP) erkannt. Der VIP Sensor hat eine Fusskickbewegung erkannt und es wurde ein Kessy - Schlüssel im Heckaussenbereich erkannt.
          signal KY_Bereich_XIX_KeylessAccess_01_XIX_HCP3_CANFD01: start 163, 3 bit, little-endian, data-type-policy=OVERRIDE, i-signal-type=PRIMITIVE, init-value=7, base-type=BT_KY_Bereich, compu {4=Cx4_Bereich_4 (CM_KY_Bereich_Cx4_Bereich_4), 0=Cx0_Bereich_0 (CM_KY_Bereich_Cx0_Bereich_0), 5=Cx5_Bereich_5 (CM_KY_Bereich_Cx5_Bereich_5), 7=Cx7_Init (CM_KY_Bereich_Cx7_Init), 3=Cx3_Bereich_3 (CM_KY_Bereich_Cx3_Bereich_3), 6=Cx6_Kein_Schluessel_gefunden (CM_KY_Bereich_Cx6_Kein_Schluessel_gefunden), 1=Cx1_Bereich_1 (CM_KY_Bereich_Cx1_Bereich_1), 2=Cx2_Bereich_2 (CM_KY_Bereich_Cx2_Bereich_2)}, range raw 0..7, transfer-property=TRIGGERED-WITHOUT-REPETITION  # Schlüsselentfernung für Funktionen Annäherungslicht, automatisches Entriegeln
          signal FBS_KSY_ID_active_XIX_KeylessAccess_01_XIX_HCP3_CANFD01: start 168, 4 bit, little-endian, data-type-policy=OVERRIDE, i-signal-type=PRIMITIVE, init-value=0, base-type=BT_FBS_KSY_ID_active, compu {11=Cxb_S_device_03 (CM_FBS_KSY_ID_active_Cxb_S_device_03), 13=Cxd_S_device_05 (CM_FBS_KSY_ID_active_Cxd_S_device_05), 10=Cxa_S_device_02 (CM_FBS_KSY_ID_active_Cxa_S_device_02), 5=Cx5_ID_device_05 (CM_FBS_KSY_ID_active_Cx5_ID_device_05), 8=Cx8_ID_device_08 (CM_FBS_KSY_ID_active_Cx8_ID_device_08), 12=Cxc_S_device_04 (CM_FBS_KSY_ID_active_Cxc_S_device_04), 6=Cx6_ID_device_06 (CM_FBS_KSY_ID_active_Cx6_ID_device_06), 1=Cx1_ID_device_01 (CM_FBS_KSY_ID_active_Cx1_ID_device_01), 2=Cx2_ID_device_02 (CM_FBS_KSY_ID_active_Cx2_ID_device_02), 15=Cxf_S_device_07 (CM_FBS_KSY_ID_active_Cxf_S_device_07), 3=Cx3_ID_device_03 (CM_FBS_KSY_ID_active_Cx3_ID_device_03), 0=Cx0_Init (CM_FBS_KSY_ID_active_Cx0_Init), 4=Cx4_ID_device_04 (CM_FBS_KSY_ID_active_Cx4_ID_device_04), 9=Cx9_S_device_01 (CM_FBS_KSY_ID_active_Cx9_S_device_01), 7=Cx7_ID_device_07 (CM_FBS_KSY_ID_active_Cx7_ID_device_07), 14=Cxe_S_device_06 (CM_FBS_KSY_ID_active_Cxe_S_device_06)}, range raw 0..15, transfer-property=TRIGGERED-WITHOUT-REPETITION  # active ID- or smart device
          signal WLC_laden_unterbrechen_XIX_KeylessAccess_01_XIX_HCP3_CANFD01: start 175, 1 bit, little-endian, data-type-policy=OVERRIDE, i-signal-type=PRIMITIVE, init-value=0, base-type=BT_WLC_laden_unterbrechen, compu {1=Cx1_Laden_unterbrechen (CM_WLC_laden_unterbrechen_Cx1_Laden_unterbrechen), 0=Cx0_Laden_nicht_unterbrechen (CM_WLC_laden_unterbrechen_Cx0_Laden_nicht_unterbrechen)}, range raw 0..1, transfer-property=TRIGGERED-WITHOUT-REPETITION  # Kommunikation zur Phonebox, das Laden zu unterbrechen
          signal KST_Wegstrecke_Challenge_XIX_KeylessAccess_01_XIX_HCP3_CANFD01: start 176, 20 bit, little-endian, data-type-policy=OVERRIDE, i-signal-type=PRIMITIVE, init-value=0, base-type=BT_KST_Wegstrecke_Challenge, compu {0=Cx0_Init (CM_KST_Wegstrecke_Challenge_Cx0_Init)}, range raw 0, transfer-property=TRIGGERED-WITHOUT-REPETITION  # Wegstreckenchallenge ans Kombi und ESC
          signal FBS_Anf_Start_Auth_XIX_KeylessAccess_01_XIX_HCP3_CANFD01: start 196, 1 bit, little-endian, data-type-policy=OVERRIDE, i-signal-type=PRIMITIVE, init-value=0, base-type=BT_FBS_Anf_Start_Auth, compu {0=Cx0_Init_kein_Auth_Request (CM_FBS_Anf_Start_Auth_Cx0_Init_kein_Auth_Request), 1=Cx1_Auth_Request (CM_FBS_Anf_Start_Auth_Cx1_Auth_Request)}, range raw 0..1, transfer-property=TRIGGERED-WITHOUT-REPETITION  # Trigger um Authentifikation zu starten
          signal FBS_KSY_easy_close1_XIX_KeylessAccess_01_XIX_HCP3_CANFD01: start 204, 3 bit, little-endian, data-type-policy=OVERRIDE, i-signal-type=PRIMITIVE, init-value=0, base-type=BT_FBS_KSY_easy_close1, compu {1=Cx1_Lampe_Aus (CM_FBS_KSY_easy_close1_Cx1_Lampe_Aus), 6=Cx6_easy_close_kein_Abbruch (CM_FBS_KSY_easy_close1_Cx6_easy_close_kein_Abbruch), 7=Cx7_easy_close_Abbruch (CM_FBS_KSY_easy_close1_Cx7_easy_close_Abbruch), 0=Cx0_Init (CM_FBS_KSY_easy_close1_Cx0_Init), 2=Cx2_Lampe_Ein (CM_FBS_KSY_easy_close1_Cx2_Lampe_Ein), 5=Cx5_Akustik_Verweigerung (CM_FBS_KSY_easy_close1_Cx5_Akustik_Verweigerung), 4=Cx4_Lampe_Hektik (CM_FBS_KSY_easy_close1_Cx4_Lampe_Hektik), 3=Cx3_Lampe_Normal (CM_FBS_KSY_easy_close1_Cx3_Lampe_Normal)}, range raw 0..7, transfer-property=TRIGGERED-WITHOUT-REPETITION  # Schliessende Heckklappe mittels Easy Close Funktion
          signal NFC_TGS_Kapa_deaktivieren_XIX_KeylessAccess_01_XIX_HCP3_CANFD01: start 207, 1 bit, little-endian, data-type-policy=OVERRIDE, i-signal-type=PRIMITIVE, init-value=0, base-type=BT_NFC_TGS_Kapa_deaktivieren, compu {1=Cx1_Deaktivierung (CM_NFC_TGS_Kapa_deaktivieren_Cx1_Deaktivierung), 0=Cx0_keine_Deaktivierung (CM_NFC_TGS_Kapa_deaktivieren_Cx0_keine_Deaktivierung)}, range raw 0..1, transfer-property=TRIGGERED-WITHOUT-REPETITION  # Deaktiviert den Kapa-Sensor im eTAB
          signal FBS_MDK_BLE_lock_sensor_auth_XIX_KeylessAccess_01_XIX_HCP3_CANFD01: start 208, 4 bit, little-endian, data-type-policy=OVERRIDE, i-signal-type=PRIMITIVE, init-value=0, base-type=BT_FBS_MDK_BLE_lock_sensor_auth, compu {12=Cxc_ctrl_D_authorized (CM_FBS_MDK_BLE_lock_sensor_auth_Cxc_ctrl_D_authorized), 4=Cx4_RCDD_lock_authorized (CM_FBS_MDK_BLE_lock_sensor_auth_Cx4_RCDD_lock_authorized), 8=Cx8_charge_terminal2_lock_auth (CM_FBS_MDK_BLE_lock_sensor_auth_Cx8_charge_terminal2_lock_auth), 15=Cxf_ctrl_G_authorized (CM_FBS_MDK_BLE_lock_sensor_auth_Cxf_ctrl_G_authorized), 14=Cxe_ctrl_F_authorized (CM_FBS_MDK_BLE_lock_sensor_auth_Cxe_ctrl_F_authorized), 3=Cx3_RDD_lock_authorized (CM_FBS_MDK_BLE_lock_sensor_auth_Cx3_RDD_lock_authorized), 7=Cx7_charge_terminal1_lock_auth (CM_FBS_MDK_BLE_lock_sensor_auth_Cx7_charge_terminal1_lock_auth), 10=Cxa_ctrl_B_authorized (CM_FBS_MDK_BLE_lock_sensor_auth_Cxa_ctrl_B_authorized), 11=Cxb_ctrl_C_authorized (CM_FBS_MDK_BLE_lock_sensor_auth_Cxb_ctrl_C_authorized), 9=Cx9_ctrl_A_authorized (CM_FBS_MDK_BLE_lock_sensor_auth_Cx9_ctrl_A_authorized), 1=Cx1_DD_lock_authorized (CM_FBS_MDK_BLE_lock_sensor_auth_Cx1_DD_lock_authorized), 13=Cxd_ctrl_E_authorized (CM_FBS_MDK_BLE_lock_sensor_auth_Cxd_ctrl_E_authorized), 5=Cx5_rear_trunk_lock_authorized (CM_FBS_MDK_BLE_lock_sensor_auth_Cx5_rear_trunk_lock_authorized), 2=Cx2_CDD_lock_authorized (CM_FBS_MDK_BLE_lock_sensor_auth_Cx2_CDD_lock_authorized), 0=Cx0_no_lock_authorized (CM_FBS_MDK_BLE_lock_sensor_auth_Cx0_no_lock_authorized), 6=Cx6_front_trunk_lock_authorized (CM_FBS_MDK_BLE_lock_sensor_auth_Cx6_front_trunk_lock_authorized)}, range raw 0..15, transfer-property=TRIGGERED-WITHOUT-REPETITION  # Autorisierung einer Verriegelung an MDK-Bedienstelle (BLE)
          signal FBS_MDK_BLE_unlock_sensor_auth_XIX_KeylessAccess_01_XIX_HCP3_CANFD01: start 212, 4 bit, little-endian, data-type-policy=OVERRIDE, i-signal-type=PRIMITIVE, init-value=0, base-type=BT_FBS_MDK_BLE_unlock_sensor_auth, compu {4=Cx4_RCDD_unlock_authorized (CM_FBS_MDK_BLE_unlock_sensor_auth_Cx4_RCDD_unlock_authorized), 7=Cx7_charge_terminal1_unlock_auth (CM_FBS_MDK_BLE_unlock_sensor_auth_Cx7_charge_terminal1_unlock_auth), 11=Cxb_ctrl_C_authorized (CM_FBS_MDK_BLE_unlock_sensor_auth_Cxb_ctrl_C_authorized), 9=Cx9_ctrl_A_authorized (CM_FBS_MDK_BLE_unlock_sensor_auth_Cx9_ctrl_A_authorized), 3=Cx3_RDD_unlock_authorized (CM_FBS_MDK_BLE_unlock_sensor_auth_Cx3_RDD_unlock_authorized), 6=Cx6_front_trunk_unlock_authorized (CM_FBS_MDK_BLE_unlock_sensor_auth_Cx6_front_trunk_unlock_authorized), 14=Cxe_ctrl_F_authorized (CM_FBS_MDK_BLE_unlock_sensor_auth_Cxe_ctrl_F_authorized), 0=Cx0_no_unlock_authorized (CM_FBS_MDK_BLE_unlock_sensor_auth_Cx0_no_unlock_authorized), 10=Cxa_ctrl_B_authorized (CM_FBS_MDK_BLE_unlock_sensor_auth_Cxa_ctrl_B_authorized), 13=Cxd_ctrl_E_authorized (CM_FBS_MDK_BLE_unlock_sensor_auth_Cxd_ctrl_E_authorized), 1=Cx1_DD_unlock_authorized (CM_FBS_MDK_BLE_unlock_sensor_auth_Cx1_DD_unlock_authorized), 2=Cx2_CDD_unlock_authorized (CM_FBS_MDK_BLE_unlock_sensor_auth_Cx2_CDD_unlock_authorized), 8=Cx8_charge_terminal2_unlock_auth (CM_FBS_MDK_BLE_unlock_sensor_auth_Cx8_charge_terminal2_unlock_auth), 12=Cxc_ctrl_D_authorized (CM_FBS_MDK_BLE_unlock_sensor_auth_Cxc_ctrl_D_authorized), 5=Cx5_rear_trunk_unlock_authorized (CM_FBS_MDK_BLE_unlock_sensor_auth_Cx5_rear_trunk_unlock_authorized), 15=Cxf_ctrl_G_authorized (CM_FBS_MDK_BLE_unlock_sensor_auth_Cxf_ctrl_G_authorized)}, range raw 0..15, transfer-property=TRIGGERED-WITHOUT-REPETITION  # Autorisierung einer Entriegelung an MDK-Bedienstelle (BLE)
          signal FBS_MDK_NFC_lock_sensor_auth_XIX_KeylessAccess_01_XIX_HCP3_CANFD01: start 216, 4 bit, little-endian, data-type-policy=OVERRIDE, i-signal-type=PRIMITIVE, init-value=0, base-type=BT_FBS_MDK_NFC_lock_sensor_auth, compu {12=Cxc_ctrl_D_authorized (CM_FBS_MDK_NFC_lock_sensor_auth_Cxc_ctrl_D_authorized), 13=Cxd_ctrl_E_authorized (CM_FBS_MDK_NFC_lock_sensor_auth_Cxd_ctrl_E_authorized), 6=Cx6_front_trunk_lock_authorized (CM_FBS_MDK_NFC_lock_sensor_auth_Cx6_front_trunk_lock_authorized), 8=Cx8_charge_terminal2_lock_auth (CM_FBS_MDK_NFC_lock_sensor_auth_Cx8_charge_terminal2_lock_auth), 2=Cx2_CDD_lock_authorized (CM_FBS_MDK_NFC_lock_sensor_auth_Cx2_CDD_lock_authorized), 1=Cx1_DD_lock_authorized (CM_FBS_MDK_NFC_lock_sensor_auth_Cx1_DD_lock_authorized), 7=Cx7_charge_terminal1_lock_auth (CM_FBS_MDK_NFC_lock_sensor_auth_Cx7_charge_terminal1_lock_auth), 5=Cx5_rear_trunk_lock_authorized (CM_FBS_MDK_NFC_lock_sensor_auth_Cx5_rear_trunk_lock_authorized), 11=Cxb_ctrl_C_authorized (CM_FBS_MDK_NFC_lock_sensor_auth_Cxb_ctrl_C_authorized), 14=Cxe_ctrl_F_authorized (CM_FBS_MDK_NFC_lock_sensor_auth_Cxe_ctrl_F_authorized), 3=Cx3_RDD_lock_authorized (CM_FBS_MDK_NFC_lock_sensor_auth_Cx3_RDD_lock_authorized), 0=Cx0_no_lock_authorized (CM_FBS_MDK_NFC_lock_sensor_auth_Cx0_no_lock_authorized), 9=Cx9_ctrl_A_authorized (CM_FBS_MDK_NFC_lock_sensor_auth_Cx9_ctrl_A_authorized), 4=Cx4_RCDD_lock_authorized (CM_FBS_MDK_NFC_lock_sensor_auth_Cx4_RCDD_lock_authorized), 15=Cxf_ctrl_G_authorized (CM_FBS_MDK_NFC_lock_sensor_auth_Cxf_ctrl_G_authorized), 10=Cxa_ctrl_B_authorized (CM_FBS_MDK_NFC_lock_sensor_auth_Cxa_ctrl_B_authorized)}, range raw 0..15, transfer-property=TRIGGERED-WITHOUT-REPETITION  # Autorisierung einer Verriegelung an MDK-Bedienstelle (NFC)
          signal FBS_MDK_NFC_unlock_sensor_auth_XIX_KeylessAccess_01_XIX_HCP3_CANFD01: start 220, 4 bit, little-endian, data-type-policy=OVERRIDE, i-signal-type=PRIMITIVE, init-value=0, base-type=BT_FBS_MDK_NFC_unlock_sensor_auth, compu {11=Cxb_ctrl_C_authorized (CM_FBS_MDK_NFC_unlock_sensor_auth_Cxb_ctrl_C_authorized), 14=Cxe_ctrl_F_authorized (CM_FBS_MDK_NFC_unlock_sensor_auth_Cxe_ctrl_F_authorized), 9=Cx9_ctrl_A_authorized (CM_FBS_MDK_NFC_unlock_sensor_auth_Cx9_ctrl_A_authorized), 1=Cx1_DD_unlock_authorized (CM_FBS_MDK_NFC_unlock_sensor_auth_Cx1_DD_unlock_authorized), 10=Cxa_ctrl_B_authorized (CM_FBS_MDK_NFC_unlock_sensor_auth_Cxa_ctrl_B_authorized), 3=Cx3_RDD_unlock_authorized (CM_FBS_MDK_NFC_unlock_sensor_auth_Cx3_RDD_unlock_authorized), 2=Cx2_CDD_unlock_authorized (CM_FBS_MDK_NFC_unlock_sensor_auth_Cx2_CDD_unlock_authorized), 12=Cxc_ctrl_D_authorized (CM_FBS_MDK_NFC_unlock_sensor_auth_Cxc_ctrl_D_authorized), 8=Cx8_charge_terminal2_unlock_auth (CM_FBS_MDK_NFC_unlock_sensor_auth_Cx8_charge_terminal2_unlock_auth), 4=Cx4_RCDD_unlock_authorized (CM_FBS_MDK_NFC_unlock_sensor_auth_Cx4_RCDD_unlock_authorized), 0=Cx0_no_unlock_authorized (CM_FBS_MDK_NFC_unlock_sensor_auth_Cx0_no_unlock_authorized), 7=Cx7_charge_terminal1_unlock_auth (CM_FBS_MDK_NFC_unlock_sensor_auth_Cx7_charge_terminal1_unlock_auth), 6=Cx6_front_trunk_unlock_authorized (CM_FBS_MDK_NFC_unlock_sensor_auth_Cx6_front_trunk_unlock_authorized), 13=Cxd_ctrl_E_authorized (CM_FBS_MDK_NFC_unlock_sensor_auth_Cxd_ctrl_E_authorized), 5=Cx5_rear_trunk_unlock_authorized (CM_FBS_MDK_NFC_unlock_sensor_auth_Cx5_rear_trunk_unlock_authorized), 15=Cxf_ctrl_G_authorized (CM_FBS_MDK_NFC_unlock_sensor_auth_Cxf_ctrl_G_authorized)}, range raw 0..15, transfer-property=TRIGGERED-WITHOUT-REPETITION  # Autorisierung einer Entriegelung an MDK-Bedienstelle (NFC)
          signal FBS_MDK_button_XIX_KeylessAccess_01_XIX_HCP3_CANFD01: start 224, 8 bit, little-endian, data-type-policy=OVERRIDE, i-signal-type=PRIMITIVE, init-value=0, base-type=BT_FBS_MDK_button, compu {10=Cxa_close_convertible (CM_FBS_MDK_button_Cxa_close_convertible), 3=Cx3_rear_trunk (CM_FBS_MDK_button_Cx3_rear_trunk), 8=Cx8_remotestart (CM_FBS_MDK_button_Cx8_remotestart), 9=Cx9_open_convertible (CM_FBS_MDK_button_Cx9_open_convertible), 5=Cx5_panic (CM_FBS_MDK_button_Cx5_panic), 0=Cx0_no_command (CM_FBS_MDK_button_Cx0_no_command), 2=Cx2_lock (CM_FBS_MDK_button_Cx2_lock), 7=Cx7_park (CM_FBS_MDK_button_Cx7_park), 4=Cx4_front_trunk (CM_FBS_MDK_button_Cx4_front_trunk), 6=Cx6_joker (CM_FBS_MDK_button_Cx6_joker), 1=Cx1_unlock (CM_FBS_MDK_button_Cx1_unlock)}, range raw 0..10, transfer-property=TRIGGERED-WITHOUT-REPETITION  # smart device button pressed signalling for remote keyless entry
      frame LSR_1_02_XIX_HCP3_CANFD01: id 0x1A555514, to HCP3_IONode, frame-length=32, can-addressing-mode=EXTENDED, can-frame-rx-behavior=CAN-FD, can-frame-tx-behavior=CAN-FD
        pdu LSR_1_02_XIX_HCP3_CANFD01: length=32, transmission-mode-true-timing=cyclic-timing={time-offset=0.0, time-period=1.0}, unused-bit-pattern=0
          signal LSR_VW_SL_Spare_Part_Nr_Index_XIX_LSR_1_02_XIX_HCP3_CANFD01: start 112, 16 bit, little-endian, data-type-policy=OVERRIDE, i-signal-type=PRIMITIVE, init-value=45, base-type=BT_LSR_VW_SL_Spare_Part_Nr_Index, compu {phys=raw for raw 0..65534, 65535=Cxffff_Error (CM_LSR_VW_SL_Spare_Part_Nr_Index_Cxffff_Error); unit Unit_None}, range phys 0..65534 Unit_None, raw 0..65535, unit=Unit_None, transfer-property=PENDING, to HCP3_IONode(timeout 5 s)  # Index der VW/Audi-Teilenummern des LSR gemäß der VW 80127= Teilenummer gemäß Kennung Teilnummer aus DID F187 VW SparePartNumber
          signal LSR_VW_SL_App_SW_Version_Nr_XIX_LSR_1_02_XIX_HCP3_CANFD01: start 128, 32 bit, little-endian, data-type-policy=OVERRIDE, i-signal-type=PRIMITIVE, init-value=45, base-type=BT_LSR_VW_SL_App_SW_Version_Nr, compu {phys=raw for raw 0..4294967294, 4294967295=Cxffffffff_Error (CM_LSR_VW_SL_App_SW_Version_Nr_Cxffffffff_Error); unit Unit_None}, range phys 0..4294967294 Unit_None, raw 0..4294967295, unit=Unit_None, transfer-property=PENDING, to HCP3_IONode(timeout 5 s)  # SW-Version des LSR gemäß VW80127= Entspricht Software-Version gemäß der DID F189 VW Software Version Number
          signal LSR_VW_SL_HW_Version_Nr_XIX_LSR_1_02_XIX_HCP3_CANFD01: start 160, 24 bit, little-endian, data-type-policy=OVERRIDE, i-signal-type=PRIMITIVE, init-value=45, base-type=BT_LSR_VW_SL_HW_Version_Nr, compu {phys=raw for raw 0..16777214, 16777215=Cxffffff_Error (CM_LSR_VW_SL_HW_Version_Nr_Cxffffff_Error); unit Unit_None}, range phys 0..16777214 Unit_None, raw 0..16777215, unit=Unit_None, transfer-property=PENDING, to HCP3_IONode(timeout 5 s)  # Slave-Hardware des LSR gemäß VW80127= Entspricht Kennung Hardware Version gemäß DID F1A3 VW ECU Hardware Version Number
          signal LSR_VW_SL_Spare_Part_Nr_EndNr_XIX_LSR_1_02_XIX_HCP3_CANFD01: start 184, 24 bit, little-endian, data-type-policy=OVERRIDE, i-signal-type=PRIMITIVE, init-value=45, base-type=BT_LSR_VW_SL_Spare_Part_Nr_EndNr, compu {phys=raw for raw 0..16777214, 16777215=Cxffffff_Error (CM_LSR_VW_SL_Spare_Part_Nr_EndNr_Cxffffff_Error); unit Unit_None}, range phys 0..16777214 Unit_None, raw 0..16777215, unit=Unit_None, transfer-property=PENDING, to HCP3_IONode(timeout 5 s)  # Endnummer der VW/Audi-Teilenummern des LSR gemäß der VW 80127= Teilenummer gemäß Kennung Teilnummer aus DID F187 VW SparePartNumber
          signal LSR_VW_SL_Spare_Part_Nr_MittelNr_XIX_LSR_1_02_XIX_HCP3_CANFD01: start 208, 24 bit, little-endian, data-type-policy=OVERRIDE, i-signal-type=PRIMITIVE, init-value=45, base-type=BT_LSR_VW_SL_Spare_Part_Nr_MittelNr, compu {phys=raw for raw 0..16777214, 16777215=Cxffffff_Error (CM_LSR_VW_SL_Spare_Part_Nr_MittelNr_Cxffffff_Error); unit Unit_None}, range phys 0..16777214 Unit_None, raw 0..16777215, unit=Unit_None, transfer-property=PENDING, to HCP3_IONode(timeout 5 s)  # Mittelnummer der VW/Audi-Teilenummern des LSR gemäß der VW 80127= Teilenummer gemäß Kennung Teilnummer aus DID F187 VW SparePartNumber
          signal LSR_VW_SL_Spare_Part_Nr_TMA_XIX_LSR_1_02_XIX_HCP3_CANFD01: start 232, 24 bit, little-endian, data-type-policy=OVERRIDE, i-signal-type=PRIMITIVE, init-value=45, base-type=BT_LSR_VW_SL_Spare_Part_Nr_TMA, compu {phys=raw for raw 0..16777214, 16777215=Cxffffff_Error (CM_LSR_VW_SL_Spare_Part_Nr_TMA_Cxffffff_Error); unit Unit_None}, range phys 0..16777214 Unit_None, raw 0..16777215, unit=Unit_None, transfer-property=PENDING, to HCP3_IONode(timeout 5 s)  # TMA der VW/Audi-Teilenummern des LSR gemäß der VW 80127. Teilenummer gemäß Kennung Teilnummer aus DID F187 VW SparePartNumber
